VERSION "HNNBNNNYNNNNNNNNNNNNNNNNNNNNNNNNNNNNNNNNNN/4/%%%/4/'%**4NNN///"

NS_ :

BS_:

BU_: BAP_Tester BedienDisp_mi BedienDisp_vo_mi CDI ConMod_CD DashCAM Gateway_Max ICC_IO_Node LSH OCU RDK_RS3 Sound_MIB_ab_Gen3 STH ZR_MIB_EINSTIEG_ab_Gen3 ZR_MIB_OPTION_ab_Gen3 ZR_MIB_TOP_ab_Gen3

BO_ 975 TSG_HBFS_01: 8 Gateway_Max
 SG_ HBFS_Tuer_geoeffnet : 0|1@1+ (1.0,0.0) [0.0|1] ""  OCU,ZR_MIB_TOP_ab_Gen3
 SG_ HBFS_verriegelt : 1|1@1+ (1.0,0.0) [0.0|1] ""  OCU
 SG_ HBFS_gesafet : 2|1@1+ (1.0,0.0) [0.0|1] ""  OCU
 SG_ HBFS_Heckrollotaster_betaetigt : 3|1@1+ (1.0,0.0) [0.0|1] ""  Vector__XXX
 SG_ HBFS_Tuerschloss_defekt : 4|1@1+ (1.0,0.0) [0.0|1] ""  Vector__XXX
 SG_ HBFS_Unlock_Taster : 5|1@1+ (1.0,0.0) [0.0|1] ""  Vector__XXX
 SG_ HBFS_Lock_Taster : 6|1@1+ (1.0,0.0) [0.0|1] ""  Vector__XXX
 SG_ HBFS_Sperrklinke : 7|1@1+ (1.0,0.0) [0.0|1] ""  Vector__XXX
 SG_ HBFS_TAG_betaetigt : 8|1@1+ (1.0,0.0) [0.0|1] ""  Vector__XXX
 SG_ HBFS_TIG_betaetigt : 9|1@1+ (1.0,0.0) [0.0|1] ""  Vector__XXX
 SG_ HBFS_FH_S_HFS_AutoHoch : 10|1@1+ (1.0,0.0) [0.0|1] ""  Vector__XXX
 SG_ HBFS_FH_S_HFS_AutoTief : 11|1@1+ (1.0,0.0) [0.0|1] ""  Vector__XXX
 SG_ HBFS_FH_S_HFS_ManHoch : 12|1@1+ (1.0,0.0) [0.0|1] ""  Vector__XXX
 SG_ HBFS_FH_S_HFS_ManTief : 13|1@1+ (1.0,0.0) [0.0|1] ""  Vector__XXX
 SG_ HBFS_Tuer_Status : 14|2@1+ (1.0,0.0) [0.0|3] ""  OCU
 SG_ HBFS_SAD_Schalter : 16|4@1+ (1.0,0.0) [0.0|15] ""  Vector__XXX
 SG_ HBFS_FH_S_ManHoch : 20|1@1+ (1.0,0.0) [0.0|1] ""  Vector__XXX
 SG_ HBFS_FH_S_AutoHoch : 21|1@1+ (1.0,0.0) [0.0|1] ""  Vector__XXX
 SG_ HBFS_FH_S_ManTief : 22|1@1+ (1.0,0.0) [0.0|1] ""  Vector__XXX
 SG_ HBFS_FH_S_AutoTief : 23|1@1+ (1.0,0.0) [0.0|1] ""  Vector__XXX
 SG_ HBFS_FH_Oeffnung : 24|8@1+ (0.5,0) [0.0|100.0] "Unit_PerCent"  OCU,ZR_MIB_TOP_ab_Gen3
 SG_ HBFS_FH_Bew_hoch : 32|1@1+ (1.0,0.0) [0.0|1] ""  Vector__XXX
 SG_ HBFS_FH_Bew_tief : 33|1@1+ (1.0,0.0) [0.0|1] ""  Vector__XXX
 SG_ HBFS_FH_Fang : 34|1@1+ (1.0,0.0) [0.0|1] ""  OCU
 SG_ HBFS_FH_Block : 35|1@1+ (1.0,0.0) [0.0|1] ""  Vector__XXX
 SG_ HBFS_FH_Thermo : 36|1@1+ (1.0,0.0) [0.0|1] ""  Vector__XXX
 SG_ HBFS_UEKB_aktiviert : 37|1@1+ (1.0,0.0) [0.0|1] ""  Vector__XXX
 SG_ HBFS_Tueroeffnen_Warnung : 38|1@1+ (1.0,0.0) [0.0|1] ""  Vector__XXX
 SG_ HBFS_FH_normiert : 39|1@1+ (1.0,0.0) [0.0|1] ""  OCU
 SG_ ASW_Warnung_aktiv_HBFS : 40|1@1+ (1.0,0.0) [0.0|1] ""  Vector__XXX
 SG_ HBFS_Zuziehhilfe_aktiv : 41|1@1+ (1.0,0.0) [0.0|1] ""  Vector__XXX
 SG_ HBFS_Seitenrollo_hoch : 42|1@1+ (1.0,0.0) [0.0|1] ""  Vector__XXX
 SG_ HBFS_Seitenrollo_tief : 43|1@1+ (1.0,0.0) [0.0|1] ""  Vector__XXX
 SG_ HBFS_Status_KiSi : 44|1@1+ (1.0,0.0) [0.0|1] ""  Vector__XXX
 SG_ SSR_HBFS_Pos_Unten : 45|1@1+ (1.0,0.0) [0.0|1] ""  Vector__XXX
 SG_ HBFS_Oben_Block_erw : 46|1@1+ (1.0,0.0) [0.0|1] ""  Vector__XXX
 SG_ HBFS_Unten_Block_erw : 47|1@1+ (1.0,0.0) [0.0|1] ""  Vector__XXX
 SG_ MTHBFS_M_Taste : 48|1@1+ (1.0,0.0) [0.0|1] ""  Vector__XXX
 SG_ MTHBFS_Pos1 : 49|1@1+ (1.0,0.0) [0.0|1] ""  Vector__XXX
 SG_ MTHBFS_Pos2 : 50|1@1+ (1.0,0.0) [0.0|1] ""  Vector__XXX
 SG_ MTHBFS_Pos3 : 51|1@1+ (1.0,0.0) [0.0|1] ""  Vector__XXX
 SG_ HBFS_MRollo_Schalter : 52|3@1+ (1.0,0.0) [0.0|7] ""  Vector__XXX
 SG_ HBFS_Lock_Taster_inv : 55|1@1+ (1.0,0.0) [0.0|1] ""  Vector__XXX
 SG_ HBFS_Status_KiSi_inv : 56|1@1+ (1.0,0.0) [0.0|1] ""  Vector__XXX
 SG_ HBFS_Status_eTAG : 57|2@1+ (1.0,0.0) [0.0|3] ""  Vector__XXX
 SG_ HBFS_Tuer_Status_QBit : 59|1@1+ (1.0,0.0) [0.0|1] ""  Vector__XXX
 SG_ HBFS_TIG_betaetigt_schliessen : 60|1@1+ (1.0,0.0) [0.0|1] ""  Vector__XXX
 SG_ HBFS_TIG_betaetigt_oeffnen : 61|1@1+ (1.0,0.0) [0.0|1] ""  Vector__XXX
 SG_ HBFS_Vorraste_betaetigt : 62|1@1+ (1.0,0.0) [0.0|1] ""  Vector__XXX
 SG_ HBFS_SK_betaetigt : 63|1@1+ (1.0,0.0) [0.0|1] ""  Vector__XXX

BO_ 974 TSG_HFS_01: 8 Gateway_Max
 SG_ HFS_Tuer_geoeffnet : 0|1@1+ (1.0,0.0) [0.0|1] ""  OCU,ZR_MIB_TOP_ab_Gen3
 SG_ HFS_verriegelt : 1|1@1+ (1.0,0.0) [0.0|1] ""  OCU
 SG_ HFS_gesafet : 2|1@1+ (1.0,0.0) [0.0|1] ""  OCU
 SG_ HFS_Heckrollotaster_betaetigt : 3|1@1+ (1.0,0.0) [0.0|1] ""  Vector__XXX
 SG_ HFS_Tuerschloss_defekt : 4|1@1+ (1.0,0.0) [0.0|1] ""  Vector__XXX
 SG_ HFS_Unlock_Taster : 5|1@1+ (1.0,0.0) [0.0|1] ""  Vector__XXX
 SG_ HFS_Lock_Taster : 6|1@1+ (1.0,0.0) [0.0|1] ""  Vector__XXX
 SG_ HFS_Sperrklinke : 7|1@1+ (1.0,0.0) [0.0|1] ""  Vector__XXX
 SG_ HFS_TAG_betaetigt : 8|1@1+ (1.0,0.0) [0.0|1] ""  Vector__XXX
 SG_ HFS_TIG_betaetigt : 9|1@1+ (1.0,0.0) [0.0|1] ""  Vector__XXX
 SG_ HFS_FH_S_HBFS_AutoHoch : 10|1@1+ (1.0,0.0) [0.0|1] ""  Vector__XXX
 SG_ HFS_FH_S_HBFS_AutoTief : 11|1@1+ (1.0,0.0) [0.0|1] ""  Vector__XXX
 SG_ HFS_FH_S_HBFS_ManHoch : 12|1@1+ (1.0,0.0) [0.0|1] ""  Vector__XXX
 SG_ HFS_FH_S_HBFS_ManTief : 13|1@1+ (1.0,0.0) [0.0|1] ""  Vector__XXX
 SG_ HFS_Tuer_Status : 14|2@1+ (1.0,0.0) [0.0|3] ""  OCU
 SG_ HFS_SAD_Schalter : 16|4@1+ (1.0,0.0) [0.0|15] ""  Vector__XXX
 SG_ HFS_FH_S_ManHoch : 20|1@1+ (1.0,0.0) [0.0|1] ""  Vector__XXX
 SG_ HFS_FH_S_AutoHoch : 21|1@1+ (1.0,0.0) [0.0|1] ""  Vector__XXX
 SG_ HFS_FH_S_ManTief : 22|1@1+ (1.0,0.0) [0.0|1] ""  Vector__XXX
 SG_ HFS_FH_S_AutoTief : 23|1@1+ (1.0,0.0) [0.0|1] ""  Vector__XXX
 SG_ HFS_FH_Oeffnung : 24|8@1+ (0.5,0) [0.0|100.0] "Unit_PerCent"  OCU,ZR_MIB_TOP_ab_Gen3
 SG_ HFS_FH_Bew_hoch : 32|1@1+ (1.0,0.0) [0.0|1] ""  Vector__XXX
 SG_ HFS_FH_Bew_tief : 33|1@1+ (1.0,0.0) [0.0|1] ""  Vector__XXX
 SG_ HFS_FH_Fang : 34|1@1+ (1.0,0.0) [0.0|1] ""  OCU
 SG_ HFS_FH_Block : 35|1@1+ (1.0,0.0) [0.0|1] ""  Vector__XXX
 SG_ HFS_FH_Thermo : 36|1@1+ (1.0,0.0) [0.0|1] ""  Vector__XXX
 SG_ HFS_UEKB_aktiviert : 37|1@1+ (1.0,0.0) [0.0|1] ""  Vector__XXX
 SG_ HFS_Tueroeffnen_Warnung : 38|1@1+ (1.0,0.0) [0.0|1] ""  Vector__XXX
 SG_ HFS_FH_normiert : 39|1@1+ (1.0,0.0) [0.0|1] ""  OCU
 SG_ ASW_Warnung_aktiv_HFS : 40|1@1+ (1.0,0.0) [0.0|1] ""  Vector__XXX
 SG_ HFS_Zuziehhilfe_aktiv : 41|1@1+ (1.0,0.0) [0.0|1] ""  Vector__XXX
 SG_ HFS_Seitenrollo_hoch : 42|1@1+ (1.0,0.0) [0.0|1] ""  Vector__XXX
 SG_ HFS_Seitenrollo_tief : 43|1@1+ (1.0,0.0) [0.0|1] ""  Vector__XXX
 SG_ HFS_Status_KiSi : 44|1@1+ (1.0,0.0) [0.0|1] ""  Vector__XXX
 SG_ SSR_HFS_Pos_Unten : 45|1@1+ (1.0,0.0) [0.0|1] ""  Vector__XXX
 SG_ HFS_Oben_Block_erw : 46|1@1+ (1.0,0.0) [0.0|1] ""  Vector__XXX
 SG_ HFS_Unten_Block_erw : 47|1@1+ (1.0,0.0) [0.0|1] ""  Vector__XXX
 SG_ MTHFS_M_Taste : 48|1@1+ (1.0,0.0) [0.0|1] ""  Vector__XXX
 SG_ MTHFS_Pos1 : 49|1@1+ (1.0,0.0) [0.0|1] ""  Vector__XXX
 SG_ MTHFS_Pos2 : 50|1@1+ (1.0,0.0) [0.0|1] ""  Vector__XXX
 SG_ MTHFS_Pos3 : 51|1@1+ (1.0,0.0) [0.0|1] ""  Vector__XXX
 SG_ HFS_MRollo_Schalter : 52|3@1+ (1.0,0.0) [0.0|7] ""  Vector__XXX
 SG_ HFS_Lock_Taster_inv : 55|1@1+ (1.0,0.0) [0.0|1] ""  Vector__XXX
 SG_ HFS_Status_eTAG : 56|2@1+ (1.0,0.0) [0.0|3] ""  Vector__XXX
 SG_ HFS_Tuer_Status_QBit : 58|1@1+ (1.0,0.0) [0.0|1] ""  Vector__XXX
 SG_ HFS_TCR_Mode_aktiv : 59|1@1+ (1.0,0.0) [0.0|1] ""  Vector__XXX
 SG_ HFS_TIG_betaetigt_schliessen : 60|1@1+ (1.0,0.0) [0.0|1] ""  Vector__XXX
 SG_ HFS_TIG_betaetigt_oeffnen : 61|1@1+ (1.0,0.0) [0.0|1] ""  Vector__XXX
 SG_ HFS_Vorraste_betaetigt : 62|1@1+ (1.0,0.0) [0.0|1] ""  Vector__XXX
 SG_ HFS_SK_betaetigt : 63|1@1+ (1.0,0.0) [0.0|1] ""  Vector__XXX

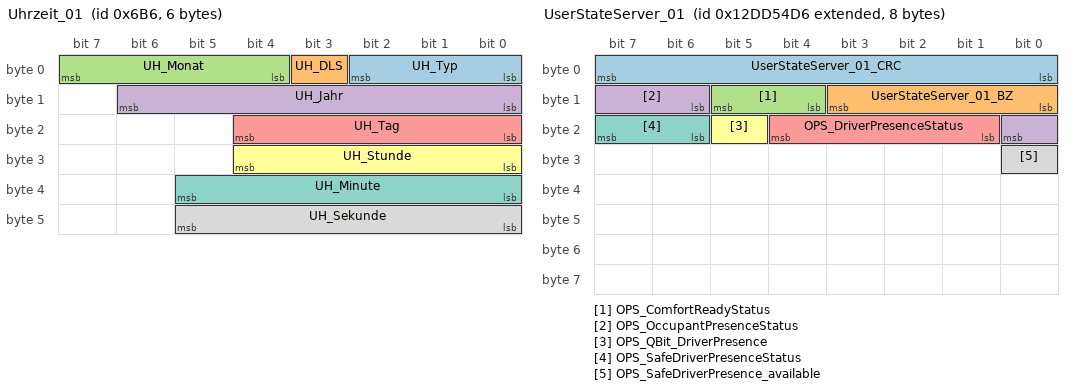
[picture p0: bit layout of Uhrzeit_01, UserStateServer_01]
BO_ 1718 Uhrzeit_01: 6 Gateway_Max
 SG_ UH_Typ : 0|3@1+ (1.0,0.0) [0.0|7] ""  OCU
 SG_ UH_DLS : 3|1@1+ (1.0,0.0) [0.0|1] ""  OCU
 SG_ UH_Monat : 4|4@1+ (1,0) [1|12] "Unit_Month"  CDI,OCU
 SG_ UH_Jahr : 8|7@1+ (1,2000) [2000|2127] "Unit_Year"  CDI,OCU
 SG_ UH_Tag : 16|5@1+ (1,0) [1|31] "Unit_Day"  CDI,OCU
 SG_ UH_Stunde : 24|5@1+ (1,0) [0|23] "Unit_Hours"  CDI,OCU
 SG_ UH_Minute : 32|6@1+ (1,0) [0|59] "Unit_Minut"  CDI,OCU
 SG_ UH_Sekunde : 40|6@1+ (1,0) [0|59] "Unit_Secon"  CDI,OCU

BO_ 2463978710 UserStateServer_01: 8 Gateway_Max
 SG_ UserStateServer_01_CRC : 0|8@1+ (1,0) [0|255] ""  Vector__XXX
 SG_ UserStateServer_01_BZ : 8|4@1+ (1,0) [0|15] ""  Vector__XXX
 SG_ OPS_ComfortReadyStatus : 12|2@1+ (1.0,0.0) [0.0|3] ""  BedienDisp_mi,BedienDisp_vo_mi,ConMod_CD
 SG_ OPS_OccupantPresenceStatus : 14|3@1+ (1.0,0.0) [0.0|7] ""  Vector__XXX
 SG_ OPS_DriverPresenceStatus : 17|4@1+ (1.0,0.0) [0.0|15] ""  BedienDisp_mi,BedienDisp_vo_mi
 SG_ OPS_QBit_DriverPresence : 21|1@1+ (1.0,0.0) [0.0|1] ""  Vector__XXX
 SG_ OPS_SafeDriverPresenceStatus : 22|2@1+ (1.0,0.0) [0.0|3] ""  Vector__XXX
 SG_ OPS_SafeDriverPresence_available : 24|1@1+ (1.0,0.0) [0.0|1] ""  Vector__XXX

BO_ 995 Verdeck_01: 8 Gateway_Max
 SG_ VS_VD_zu_ver : 16|1@1+ (1.0,0.0) [0.0|1] ""  OCU,ZR_MIB_TOP_ab_Gen3
 SG_ VS_VD_entriegelt : 17|1@1+ (1.0,0.0) [0.0|1] ""  OCU
 SG_ VS_VD_offen_ver : 18|1@1+ (1.0,0.0) [0.0|1] ""  OCU,ZR_MIB_TOP_ab_Gen3
 SG_ VS_VD_Zwischenposition : 19|1@1+ (1.0,0.0) [0.0|1] ""  Vector__XXX
 SG_ VS_VD_Bew_auf : 20|1@1+ (1.0,0.0) [0.0|1] ""  Vector__XXX
 SG_ VS_VD_Bew_zu : 21|1@1+ (1.0,0.0) [0.0|1] ""  Vector__XXX
 SG_ VS_Verdeck_Anf : 22|1@1+ (1.0,0.0) [0.0|1] ""  OCU
 SG_ VS_Hardtop : 23|1@1+ (1.0,0.0) [0.0|1] ""  Vector__XXX
 SG_ VS_VD_Fehler : 24|1@1+ (1.0,0.0) [0.0|1] ""  Vector__XXX
 SG_ VS_Lampe_Blk : 25|1@1+ (1.0,0.0) [0.0|1] ""  Vector__XXX
 SG_ VS_Buzzer : 26|1@1+ (1.0,0.0) [0.0|1] ""  Vector__XXX
 SG_ VS_HD_sperren : 27|1@1+ (1.0,0.0) [0.0|1] ""  Vector__XXX
 SG_ VS_HHS_enable : 28|1@1+ (1.0,0.0) [0.0|1] ""  Vector__XXX
 SG_ VD_SpannungsAnf : 29|2@1+ (1.0,0.0) [0.0|3] ""  Vector__XXX
 SG_ VS_VDKD_auf : 31|1@1+ (1.0,0.0) [0.0|1] ""  Vector__XXX
 SG_ VS_FS_AutoHoch : 32|1@1+ (1.0,0.0) [0.0|1] ""  Vector__XXX
 SG_ VS_FS_AutoTief : 33|1@1+ (1.0,0.0) [0.0|1] ""  Vector__XXX
 SG_ VS_FS_ManHoch : 34|1@1+ (1.0,0.0) [0.0|1] ""  Vector__XXX
 SG_ VS_FS_ManTief : 35|1@1+ (1.0,0.0) [0.0|1] ""  Vector__XXX
 SG_ VS_BFS_AutoHoch : 36|1@1+ (1.0,0.0) [0.0|1] ""  Vector__XXX
 SG_ VS_BFS_AutoTief : 37|1@1+ (1.0,0.0) [0.0|1] ""  Vector__XXX
 SG_ VS_BFS_ManHoch : 38|1@1+ (1.0,0.0) [0.0|1] ""  Vector__XXX
 SG_ VS_BFS_ManTief : 39|1@1+ (1.0,0.0) [0.0|1] ""  Vector__XXX
 SG_ VS_HFS_AutoHoch : 40|1@1+ (1.0,0.0) [0.0|1] ""  Vector__XXX
 SG_ VS_HFS_AutoTief : 41|1@1+ (1.0,0.0) [0.0|1] ""  Vector__XXX
 SG_ VS_HFS_ManHoch : 42|1@1+ (1.0,0.0) [0.0|1] ""  Vector__XXX
 SG_ VS_HFS_ManTief : 43|1@1+ (1.0,0.0) [0.0|1] ""  Vector__XXX
 SG_ VS_HBFS_AutoHoch : 44|1@1+ (1.0,0.0) [0.0|1] ""  Vector__XXX
 SG_ VS_HBFS_AutoTief : 45|1@1+ (1.0,0.0) [0.0|1] ""  Vector__XXX
 SG_ VS_HBFS_ManHoch : 46|1@1+ (1.0,0.0) [0.0|1] ""  Vector__XXX
 SG_ VS_HBFS_ManTief : 47|1@1+ (1.0,0.0) [0.0|1] ""  Vector__XXX
 SG_ VS_FH_FT_Langhub : 49|1@1+ (1.0,0.0) [0.0|1] ""  Vector__XXX
 SG_ VS_Windschott_nicht_abgelegt : 50|1@1+ (1.0,0.0) [0.0|1] ""  Vector__XXX
 SG_ VS_FH_BT_Langhub : 51|1@1+ (1.0,0.0) [0.0|1] ""  Vector__XXX
 SG_ VS_FH_HFS_Langhub : 53|1@1+ (1.0,0.0) [0.0|1] ""  Vector__XXX
 SG_ VS_Heckschloss_auf : 54|1@1+ (1.0,0.0) [0.0|1] ""  Vector__XXX
 SG_ VS_FH_HBFS_Langhub : 55|1@1+ (1.0,0.0) [0.0|1] ""  Vector__XXX
 SG_ VSG_Meldungen : 56|6@1+ (1,0) [1|63] "Unit_None"  Vector__XXX
 SG_ VS_StartStopp_Info : 62|2@1+ (1.0,0.0) [0.0|3] ""  Vector__XXX

BO_ 1716 VIN_01: 8 Gateway_Max
 SG_ VIN_01_MUX M  : 0|2@1+ (1,0) [0|3] ""  CDI,ConMod_CD,DashCAM,OCU,ZR_MIB_EINSTIEG_ab_Gen3,ZR_MIB_OPTION_ab_Gen3,ZR_MIB_TOP_ab_Gen3
 SG_ KS_Geheimnis_1 m0  : 8|8@1+ (1,0) [0|255] ""  CDI,ZR_MIB_EINSTIEG_ab_Gen3,ZR_MIB_OPTION_ab_Gen3,ZR_MIB_TOP_ab_Gen3
 SG_ VIN_4 m1  : 8|8@1+ (1,0) [0|255] ""  CDI,ConMod_CD,DashCAM,OCU,ZR_MIB_EINSTIEG_ab_Gen3,ZR_MIB_OPTION_ab_Gen3,ZR_MIB_TOP_ab_Gen3
 SG_ VIN_11 m2  : 8|8@1+ (1,0) [0|255] ""  CDI,ConMod_CD,DashCAM,OCU,ZR_MIB_EINSTIEG_ab_Gen3,ZR_MIB_OPTION_ab_Gen3,ZR_MIB_TOP_ab_Gen3
 SG_ KS_Geheimnis_2 m0  : 16|8@1+ (1,0) [0|255] ""  CDI,ZR_MIB_EINSTIEG_ab_Gen3,ZR_MIB_OPTION_ab_Gen3,ZR_MIB_TOP_ab_Gen3
 SG_ VIN_5 m1  : 16|8@1+ (1,0) [0|255] ""  CDI,ConMod_CD,DashCAM,OCU,ZR_MIB_EINSTIEG_ab_Gen3,ZR_MIB_OPTION_ab_Gen3,ZR_MIB_TOP_ab_Gen3
 SG_ VIN_12 m2  : 16|8@1+ (1,0) [0|255] ""  CDI,ConMod_CD,DashCAM,OCU,ZR_MIB_EINSTIEG_ab_Gen3,ZR_MIB_OPTION_ab_Gen3,ZR_MIB_TOP_ab_Gen3
 SG_ KS_Geheimnis_3 m0  : 24|8@1+ (1,0) [0|255] ""  CDI,ZR_MIB_EINSTIEG_ab_Gen3,ZR_MIB_OPTION_ab_Gen3,ZR_MIB_TOP_ab_Gen3
 SG_ VIN_6 m1  : 24|8@1+ (1,0) [0|255] ""  CDI,ConMod_CD,DashCAM,OCU,ZR_MIB_EINSTIEG_ab_Gen3,ZR_MIB_OPTION_ab_Gen3,ZR_MIB_TOP_ab_Gen3
 SG_ VIN_13 m2  : 24|8@1+ (1,0) [0|255] ""  CDI,ConMod_CD,DashCAM,OCU,ZR_MIB_EINSTIEG_ab_Gen3,ZR_MIB_OPTION_ab_Gen3,ZR_MIB_TOP_ab_Gen3
 SG_ KS_Geheimnis_4 m0  : 32|8@1+ (1,0) [0|255] ""  CDI,ZR_MIB_EINSTIEG_ab_Gen3,ZR_MIB_OPTION_ab_Gen3,ZR_MIB_TOP_ab_Gen3
 SG_ VIN_7 m1  : 32|8@1+ (1,0) [0|255] ""  CDI,ConMod_CD,DashCAM,OCU,ZR_MIB_EINSTIEG_ab_Gen3,ZR_MIB_OPTION_ab_Gen3,ZR_MIB_TOP_ab_Gen3
 SG_ VIN_14 m2  : 32|8@1+ (1,0) [0|255] ""  CDI,ConMod_CD,DashCAM,OCU,ZR_MIB_EINSTIEG_ab_Gen3,ZR_MIB_OPTION_ab_Gen3,ZR_MIB_TOP_ab_Gen3
 SG_ VIN_1 m0  : 40|8@1+ (1,0) [0|255] ""  CDI,ConMod_CD,DashCAM,OCU,ZR_MIB_EINSTIEG_ab_Gen3,ZR_MIB_OPTION_ab_Gen3,ZR_MIB_TOP_ab_Gen3
 SG_ VIN_8 m1  : 40|8@1+ (1,0) [0|255] ""  CDI,ConMod_CD,DashCAM,OCU,ZR_MIB_EINSTIEG_ab_Gen3,ZR_MIB_OPTION_ab_Gen3,ZR_MIB_TOP_ab_Gen3
 SG_ VIN_15 m2  : 40|8@1+ (1,0) [0|255] ""  CDI,ConMod_CD,DashCAM,OCU,ZR_MIB_EINSTIEG_ab_Gen3,ZR_MIB_OPTION_ab_Gen3,ZR_MIB_TOP_ab_Gen3
 SG_ VIN_2 m0  : 48|8@1+ (1,0) [0|255] ""  CDI,ConMod_CD,DashCAM,OCU,ZR_MIB_EINSTIEG_ab_Gen3,ZR_MIB_OPTION_ab_Gen3,ZR_MIB_TOP_ab_Gen3
 SG_ VIN_9 m1  : 48|8@1+ (1,0) [0|255] ""  CDI,ConMod_CD,DashCAM,OCU,ZR_MIB_EINSTIEG_ab_Gen3,ZR_MIB_OPTION_ab_Gen3,ZR_MIB_TOP_ab_Gen3
 SG_ VIN_16 m2  : 48|8@1+ (1,0) [0|255] ""  CDI,ConMod_CD,DashCAM,OCU,ZR_MIB_EINSTIEG_ab_Gen3,ZR_MIB_OPTION_ab_Gen3,ZR_MIB_TOP_ab_Gen3
 SG_ VIN_3 m0  : 56|8@1+ (1,0) [0|255] ""  CDI,ConMod_CD,DashCAM,OCU,ZR_MIB_EINSTIEG_ab_Gen3,ZR_MIB_OPTION_ab_Gen3,ZR_MIB_TOP_ab_Gen3
 SG_ VIN_10 m1  : 56|8@1+ (1,0) [0|255] ""  CDI,ConMod_CD,DashCAM,OCU,ZR_MIB_EINSTIEG_ab_Gen3,ZR_MIB_OPTION_ab_Gen3,ZR_MIB_TOP_ab_Gen3
 SG_ VIN_17 m2  : 56|8@1+ (1,0) [0|255] ""  CDI,ConMod_CD,DashCAM,OCU,ZR_MIB_EINSTIEG_ab_Gen3,ZR_MIB_OPTION_ab_Gen3,ZR_MIB_TOP_ab_Gen3

BO_ 916 WBA_03: 8 Gateway_Max
 SG_ WBA_03_CRC : 0|8@1+ (1,0) [0|255] ""  Vector__XXX
 SG_ WBA_03_BZ : 8|4@1+ (1,0) [0|15] ""  Vector__XXX
 SG_ WBA_Fahrstufe_02 : 12|4@1+ (1.0,0.0) [0.0|15] ""  OCU,ZR_MIB_EINSTIEG_ab_Gen3,ZR_MIB_OPTION_ab_Gen3,ZR_MIB_TOP_ab_Gen3
 SG_ WBA_ZielFahrstufe : 16|4@1+ (1.0,0.0) [0.0|15] ""  Vector__XXX
 SG_ WBA_GE_Warnung_02 : 20|4@1+ (1.0,0.0) [0.0|15] ""  Vector__XXX
 SG_ WBA_eing_Gang_02 : 24|4@1+ (1.0,0.0) [0.0|15] ""  OCU,ZR_MIB_EINSTIEG_ab_Gen3,ZR_MIB_OPTION_ab_Gen3,ZR_MIB_TOP_ab_Gen3
 SG_ WBA_GE_Texte : 28|3@1+ (1.0,0.0) [0.0|7] ""  Vector__XXX
 SG_ WBA_Segeln_aktiv : 31|1@1+ (1.0,0.0) [0.0|1] ""  OCU,ZR_MIB_EINSTIEG_ab_Gen3,ZR_MIB_OPTION_ab_Gen3,ZR_MIB_TOP_ab_Gen3
 SG_ WBA_Schaltschema_02 : 32|3@1+ (1.0,0.0) [0.0|7] ""  Vector__XXX
 SG_ WBA_Schaltschema_FS_inaktiv : 35|2@1+ (1.0,0.0) [0.0|3] ""  Vector__XXX
 SG_ WBA_GE_Zusatzwarnungen : 37|3@1+ (1.0,0.0) [0.0|7] ""  OCU,ZR_MIB_TOP_ab_Gen3
 SG_ GE_Sollgang : 40|4@1+ (1.0,0.0) [0.0|15] ""  OCU,ZR_MIB_EINSTIEG_ab_Gen3,ZR_MIB_OPTION_ab_Gen3,ZR_MIB_TOP_ab_Gen3
 SG_ GE_Tipschaltempf_verfuegbar : 44|1@1+ (1.0,0.0) [0.0|1] ""  OCU,ZR_MIB_OPTION_ab_Gen3
 SG_ WBA_GE_Texte_02 : 45|3@1+ (1.0,0.0) [0.0|7] ""  Vector__XXX
 SG_ WBA_Schaltschema_Tippgasse : 48|1@1+ (1.0,0.0) [0.0|1] ""  Vector__XXX
 SG_ WBA_Schaltschema_Fahreraktion : 49|1@1+ (1.0,0.0) [0.0|1] ""  Vector__XXX
 SG_ WBA_Schaltschema_FS_vorwaerts : 50|2@1+ (1.0,0.0) [0.0|3] ""  Vector__XXX
 SG_ WBA_Shiftlock_Lampe : 52|1@1+ (1.0,0.0) [0.0|1] ""  Vector__XXX
 SG_ WBA_Anforderung_Akustik : 53|1@1+ (1.0,0.0) [0.0|1] ""  Vector__XXX
 SG_ WBA_Blinken : 54|1@1+ (1.0,0.0) [0.0|1] ""  Vector__XXX
 SG_ GE_Wiederstart_Anz_Std : 55|1@1+ (1.0,0.0) [0.0|1] ""  Vector__XXX
 SG_ GE_Stoppverbot_Anz_01 : 56|1@1+ (1.0,0.0) [0.0|1] ""  Vector__XXX
 SG_ GE_Stoppverbot_Anz_02 : 57|1@1+ (1.0,0.0) [0.0|1] ""  Vector__XXX
 SG_ GE_Stoppverbot_Anz_03 : 58|1@1+ (1.0,0.0) [0.0|1] ""  Vector__XXX
 SG_ GE_Stoppverbot_Anz_04 : 59|1@1+ (1.0,0.0) [0.0|1] ""  Vector__XXX
 SG_ GE_Stoppverbot_Anz_05 : 60|1@1+ (1.0,0.0) [0.0|1] ""  Vector__XXX
 SG_ GE_Stoppverbot_Anz_06 : 61|1@1+ (1.0,0.0) [0.0|1] ""  Vector__XXX
 SG_ GE_Stoppverbot_Anz_07 : 62|1@1+ (1.0,0.0) [0.0|1] ""  Vector__XXX
 SG_ GE_Stoppverbot_Anz_Std : 63|1@1+ (1.0,0.0) [0.0|1] ""  Vector__XXX

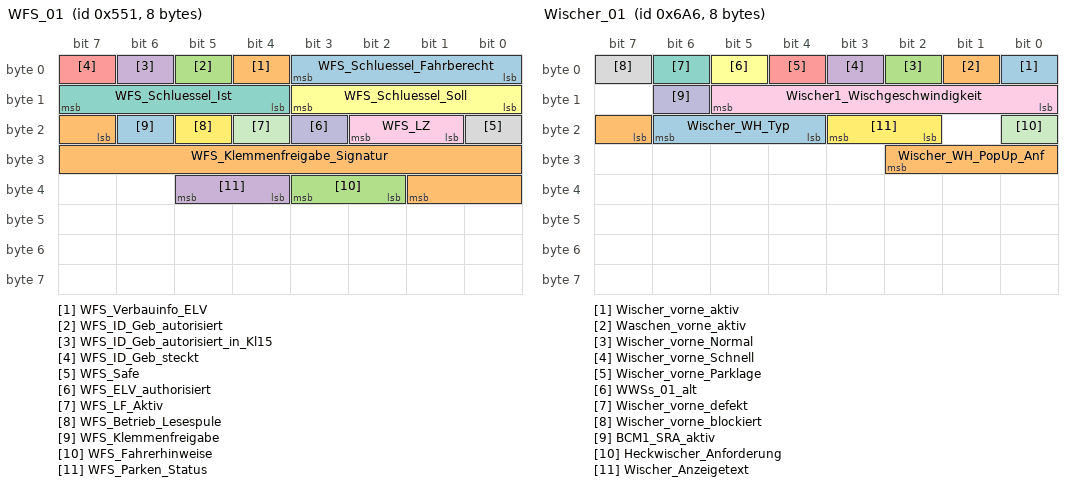
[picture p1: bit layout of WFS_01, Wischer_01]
BO_ 1361 WFS_01: 8 Gateway_Max
 SG_ WFS_Schluessel_Fahrberecht : 0|4@1+ (1.0,0.0) [0.0|15] ""  OCU,ZR_MIB_EINSTIEG_ab_Gen3
 SG_ WFS_Verbauinfo_ELV : 4|1@1+ (1.0,0.0) [0.0|1] ""  Vector__XXX
 SG_ WFS_ID_Geb_autorisiert : 5|1@1+ (1.0,0.0) [0.0|1] ""  Vector__XXX
 SG_ WFS_ID_Geb_autorisiert_in_Kl15 : 6|1@1+ (1.0,0.0) [0.0|1] ""  OCU
 SG_ WFS_ID_Geb_steckt : 7|1@1+ (1.0,0.0) [0.0|1] ""  Vector__XXX
 SG_ WFS_Schluessel_Soll : 8|4@1+ (1,0) [0|8] "Unit_None"  ZR_MIB_EINSTIEG_ab_Gen3,ZR_MIB_TOP_ab_Gen3
 SG_ WFS_Schluessel_Ist : 12|4@1+ (1,0) [0|8] "Unit_None"  ZR_MIB_EINSTIEG_ab_Gen3,ZR_MIB_TOP_ab_Gen3
 SG_ WFS_Safe : 16|1@1+ (1.0,0.0) [0.0|1] ""  Vector__XXX
 SG_ WFS_LZ : 17|2@1+ (1.0,0.0) [0.0|3] ""  Vector__XXX
 SG_ WFS_ELV_authorisiert : 19|1@1+ (1.0,0.0) [0.0|1] ""  Vector__XXX
 SG_ WFS_LF_Aktiv : 20|1@1+ (1.0,0.0) [0.0|1] ""  Vector__XXX
 SG_ WFS_Betrieb_Lesespule : 21|1@1+ (1.0,0.0) [0.0|1] ""  Vector__XXX
 SG_ WFS_Klemmenfreigabe : 22|1@1+ (1.0,0.0) [0.0|1] ""  OCU
 SG_ WFS_Klemmenfreigabe_Signatur : 23|11@1+ (1,0) [0|2047] ""  Vector__XXX
 SG_ WFS_Fahrerhinweise : 34|2@1+ (1.0,0.0) [0.0|3] ""  Vector__XXX
 SG_ WFS_Parken_Status : 36|2@1+ (1.0,0.0) [0.0|3] ""  Vector__XXX

BO_ 1702 Wischer_01: 8 Gateway_Max
 SG_ Wischer_vorne_aktiv : 0|1@1+ (1.0,0.0) [0.0|1] ""  OCU
 SG_ Waschen_vorne_aktiv : 1|1@1+ (1.0,0.0) [0.0|1] ""  OCU
 SG_ Wischer_vorne_Normal : 2|1@1+ (1.0,0.0) [0.0|1] ""  Vector__XXX
 SG_ Wischer_vorne_Schnell : 3|1@1+ (1.0,0.0) [0.0|1] ""  Vector__XXX
 SG_ Wischer_vorne_Parklage : 4|1@1+ (1.0,0.0) [0.0|1] ""  Vector__XXX
 SG_ WWSs_01_alt : 5|1@1+ (1.0,0.0) [0.0|1] ""  Vector__XXX
 SG_ Wischer_vorne_defekt : 6|1@1+ (1.0,0.0) [0.0|1] ""  OCU
 SG_ Wischer_vorne_blockiert : 7|1@1+ (1.0,0.0) [0.0|1] ""  Vector__XXX
 SG_ Wischer1_Wischgeschwindigkeit : 8|6@1+ (1,9) [10|70] "Unit_MinutInver"  OCU
 SG_ BCM1_SRA_aktiv : 14|1@1+ (1.0,0.0) [0.0|1] ""  Vector__XXX
 SG_ Heckwischer_Anforderung : 16|1@1+ (1.0,0.0) [0.0|1] ""  Vector__XXX
 SG_ Wischer_Anzeigetext : 18|2@1+ (1.0,0.0) [0.0|3] ""  Vector__XXX
 SG_ Wischer_WH_Typ : 20|3@1+ (1.0,0.0) [0.0|7] ""  Vector__XXX
 SG_ Wischer_WH_PopUp_Anf : 23|4@1+ (1.0,0.0) [0.0|15] ""  Vector__XXX

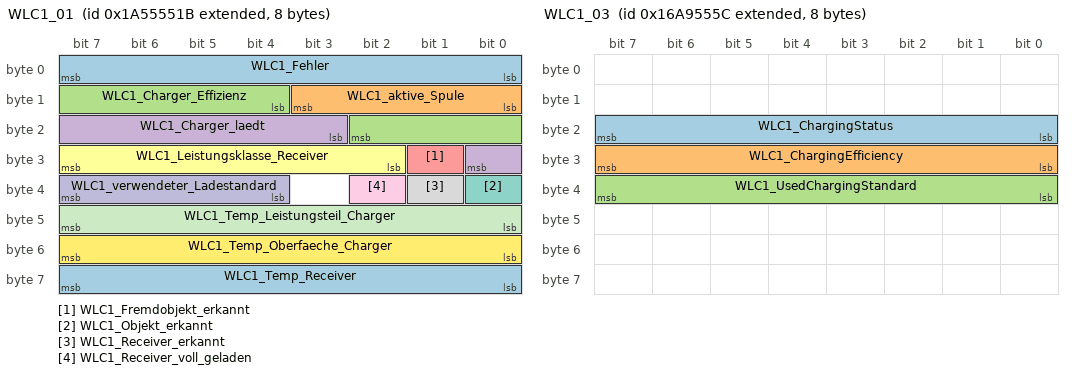
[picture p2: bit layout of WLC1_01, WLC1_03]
BO_ 2589283611 WLC1_01: 8 Gateway_Max
 SG_ WLC1_Fehler : 0|8@1+ (1.0,0.0) [0.0|255] ""  Gateway_Max,ICC_IO_Node,ZR_MIB_EINSTIEG_ab_Gen3,ZR_MIB_OPTION_ab_Gen3,ZR_MIB_TOP_ab_Gen3
 SG_ WLC1_aktive_Spule : 8|4@1+ (1,0) [0|10] ""  Gateway_Max,ICC_IO_Node,ZR_MIB_EINSTIEG_ab_Gen3,ZR_MIB_OPTION_ab_Gen3,ZR_MIB_TOP_ab_Gen3
 SG_ WLC1_Charger_Effizienz : 12|7@1+ (1,0) [0|100] "Unit_PerCent"  Gateway_Max,ICC_IO_Node,ZR_MIB_EINSTIEG_ab_Gen3,ZR_MIB_OPTION_ab_Gen3,ZR_MIB_TOP_ab_Gen3
 SG_ WLC1_Charger_laedt : 19|6@1+ (0.1,0) [0.0|5.0] "Unit_Watt"  Gateway_Max,ICC_IO_Node,ZR_MIB_EINSTIEG_ab_Gen3,ZR_MIB_OPTION_ab_Gen3,ZR_MIB_TOP_ab_Gen3
 SG_ WLC1_Fremdobjekt_erkannt : 25|1@1+ (1.0,0.0) [0.0|1] ""  Gateway_Max,ICC_IO_Node,ZR_MIB_EINSTIEG_ab_Gen3,ZR_MIB_OPTION_ab_Gen3,ZR_MIB_TOP_ab_Gen3
 SG_ WLC1_Leistungsklasse_Receiver : 26|6@1+ (0.1,0) [0.0|5.0] "Unit_Watt"  Gateway_Max,ICC_IO_Node,ZR_MIB_EINSTIEG_ab_Gen3,ZR_MIB_OPTION_ab_Gen3,ZR_MIB_TOP_ab_Gen3
 SG_ WLC1_Objekt_erkannt : 32|1@1+ (1.0,0.0) [0.0|1] ""  Gateway_Max,ICC_IO_Node,ZR_MIB_EINSTIEG_ab_Gen3,ZR_MIB_OPTION_ab_Gen3,ZR_MIB_TOP_ab_Gen3
 SG_ WLC1_Receiver_erkannt : 33|1@1+ (1.0,0.0) [0.0|1] ""  Gateway_Max,ICC_IO_Node,ZR_MIB_EINSTIEG_ab_Gen3,ZR_MIB_OPTION_ab_Gen3,ZR_MIB_TOP_ab_Gen3
 SG_ WLC1_Receiver_voll_geladen : 34|1@1+ (1.0,0.0) [0.0|1] ""  Gateway_Max,ICC_IO_Node,ZR_MIB_EINSTIEG_ab_Gen3,ZR_MIB_OPTION_ab_Gen3,ZR_MIB_TOP_ab_Gen3
 SG_ WLC1_verwendeter_Ladestandard : 36|4@1+ (1,0) [0|15] ""  Gateway_Max,ICC_IO_Node,ZR_MIB_EINSTIEG_ab_Gen3,ZR_MIB_OPTION_ab_Gen3,ZR_MIB_TOP_ab_Gen3
 SG_ WLC1_Temp_Leistungsteil_Charger : 40|8@1+ (1,-58) [-58|120] "Unit_DegreCelsi"  Gateway_Max,ICC_IO_Node,ZR_MIB_EINSTIEG_ab_Gen3,ZR_MIB_OPTION_ab_Gen3,ZR_MIB_TOP_ab_Gen3
 SG_ WLC1_Temp_Oberfaeche_Charger : 48|8@1+ (1,-58) [-58|120] "Unit_DegreCelsi"  Gateway_Max,ICC_IO_Node,ZR_MIB_EINSTIEG_ab_Gen3,ZR_MIB_OPTION_ab_Gen3,ZR_MIB_TOP_ab_Gen3
 SG_ WLC1_Temp_Receiver : 56|8@1+ (1,-58) [-58|120] "Unit_DegreCelsi"  Gateway_Max,ICC_IO_Node,ZR_MIB_EINSTIEG_ab_Gen3,ZR_MIB_OPTION_ab_Gen3,ZR_MIB_TOP_ab_Gen3

BO_ 2527679836 WLC1_03: 8 Gateway_Max
 SG_ WLC1_ChargingStatus : 16|8@1+ (1.0,0.0) [0.0|255] ""  Gateway_Max,ICC_IO_Node,ZR_MIB_EINSTIEG_ab_Gen3,ZR_MIB_OPTION_ab_Gen3,ZR_MIB_TOP_ab_Gen3
 SG_ WLC1_ChargingEfficiency : 24|8@1+ (1,0) [0|100] "Unit_PerCent"  Gateway_Max,ICC_IO_Node,ZR_MIB_EINSTIEG_ab_Gen3,ZR_MIB_OPTION_ab_Gen3,ZR_MIB_TOP_ab_Gen3
 SG_ WLC1_UsedChargingStandard : 32|8@1+ (1.0,0.0) [0.0|255] ""  Gateway_Max,ICC_IO_Node,ZR_MIB_EINSTIEG_ab_Gen3,ZR_MIB_OPTION_ab_Gen3,ZR_MIB_TOP_ab_Gen3

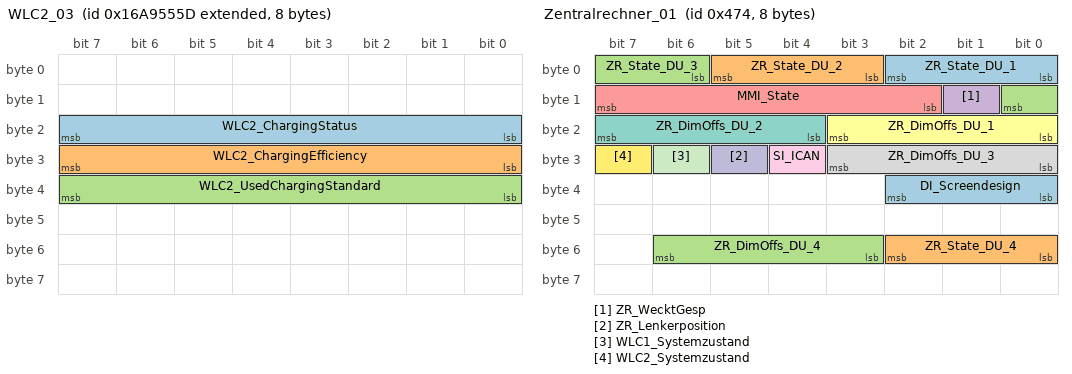
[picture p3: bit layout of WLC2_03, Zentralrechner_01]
BO_ 2527679837 WLC2_03: 8 Gateway_Max
 SG_ WLC2_ChargingStatus : 16|8@1+ (1.0,0.0) [0.0|255] ""  ZR_MIB_EINSTIEG_ab_Gen3,ZR_MIB_OPTION_ab_Gen3
 SG_ WLC2_ChargingEfficiency : 24|8@1+ (1,0) [0|100] "Unit_PerCent"  ZR_MIB_EINSTIEG_ab_Gen3,ZR_MIB_OPTION_ab_Gen3
 SG_ WLC2_UsedChargingStandard : 32|8@1+ (1.0,0.0) [0.0|255] ""  ZR_MIB_EINSTIEG_ab_Gen3,ZR_MIB_OPTION_ab_Gen3

BO_ 2617059072 XCP_LSH_CRO_01: 8 Vector__XXX
 SG_ XCP_LSH_CRO_01_Data : 0|64@1+ (1,0) [0|1] ""  LSH

BO_ 2617059073 XCP_LSH_DTO_01: 8 LSH
 SG_ XCP_LSH_DTO_01_Data : 0|64@1+ (1,0) [0|1] ""  Vector__XXX

BO_ 1140 Zentralrechner_01: 8 ICC_IO_Node
 SG_ ZR_State_DU_1 : 0|3@1+ (1.0,0.0) [0.0|7] ""  Gateway_Max
 SG_ ZR_State_DU_2 : 3|3@1+ (1.0,0.0) [0.0|7] ""  Gateway_Max
 SG_ ZR_State_DU_3 : 6|3@1+ (1.0,0.0) [0.0|7] ""  Gateway_Max
 SG_ ZR_WecktGesp : 9|1@1+ (1.0,0.0) [0.0|1] ""  Gateway_Max
 SG_ MMI_State : 10|6@1+ (1.0,0.0) [0.0|63] ""  BedienDisp_mi,BedienDisp_vo_mi,Gateway_Max
 SG_ ZR_DimOffs_DU_1 : 16|4@1+ (1,-5) [-5|5] "Unit_None"  BedienDisp_vo_mi,Gateway_Max
 SG_ ZR_DimOffs_DU_2 : 20|4@1+ (1,-5) [-5|5] "Unit_None"  Gateway_Max
 SG_ ZR_DimOffs_DU_3 : 24|4@1+ (1,-5) [-5|5] "Unit_None"  Gateway_Max
 SG_ SI_ICAN : 28|1@1+ (1.0,0.0) [0.0|1] ""  Gateway_Max
 SG_ ZR_Lenkerposition : 29|1@1+ (1.0,0.0) [0.0|1] ""  Gateway_Max
 SG_ WLC1_Systemzustand : 30|1@1+ (1.0,0.0) [0.0|1] ""  Gateway_Max
 SG_ WLC2_Systemzustand : 31|1@1+ (1.0,0.0) [0.0|1] ""  Gateway_Max
 SG_ DI_Screendesign : 32|3@1+ (1.0,0.0) [0.0|7] ""  BedienDisp_vo_mi,CDI,Gateway_Max
 SG_ ZR_State_DU_4 : 48|3@1+ (1.0,0.0) [0.0|7] ""  Gateway_Max
 SG_ ZR_DimOffs_DU_4 : 51|4@1+ (1,-5) [-5|5] "Unit_None"  Gateway_Max

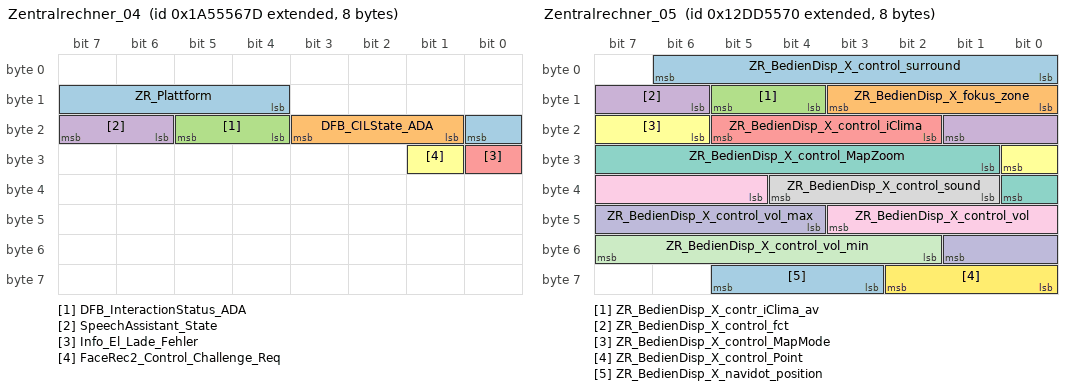
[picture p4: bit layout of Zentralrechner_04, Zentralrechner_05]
BO_ 2589283965 Zentralrechner_04: 8 ZR_MIB_EINSTIEG_ab_Gen3
 SG_ ZR_Plattform : 12|5@1+ (1.0,0.0) [0.0|31] ""  Gateway_Max
 SG_ DFB_CILState_ADA : 17|3@1+ (1.0,0.0) [0.0|7] ""  Gateway_Max
 SG_ DFB_InteractionStatus_ADA : 20|2@1+ (1.0,0.0) [0.0|3] ""  Gateway_Max
 SG_ SpeechAssistant_State : 22|2@1+ (1.0,0.0) [0.0|3] ""  Gateway_Max
 SG_ Info_El_Lade_Fehler : 24|1@1+ (1.0,0.0) [0.0|1] ""  Gateway_Max
 SG_ FaceRec2_Control_Challenge_Req : 25|1@1+ (1.0,0.0) [0.0|1] ""  Gateway_Max

BO_ 2463978864 Zentralrechner_05: 8 Gateway_Max
 SG_ ZR_BedienDisp_X_control_surround : 0|7@1+ (1,0) [0|100] "Unit_None"  Gateway_Max
 SG_ ZR_BedienDisp_X_fokus_zone : 8|4@1+ (1.0,0.0) [0.0|15] ""  Gateway_Max
 SG_ ZR_BedienDisp_X_contr_iClima_av : 12|2@1+ (1.0,0.0) [0.0|3] ""  BedienDisp_vo_mi,Gateway_Max
 SG_ ZR_BedienDisp_X_control_fct : 14|4@1+ (1.0,0.0) [0.0|15] ""  BedienDisp_vo_mi,Gateway_Max
 SG_ ZR_BedienDisp_X_control_iClima : 18|4@1+ (1.0,0.0) [0.0|15] ""  BedienDisp_vo_mi,Gateway_Max
 SG_ ZR_BedienDisp_X_control_MapMode : 22|3@1+ (1.0,0.0) [0.0|7] ""  BedienDisp_vo_mi,Gateway_Max
 SG_ ZR_BedienDisp_X_control_MapZoom : 25|8@1+ (1.0,0.0) [0.0|255] ""  BedienDisp_vo_mi,Gateway_Max
 SG_ ZR_BedienDisp_X_control_sound : 33|4@1+ (1.0,0.0) [0.0|15] ""  BedienDisp_mi,BedienDisp_vo_mi,Gateway_Max
 SG_ ZR_BedienDisp_X_control_vol : 37|7@1+ (1,0) [0|60] "Unit_None"  BedienDisp_mi,BedienDisp_vo_mi,Gateway_Max
 SG_ ZR_BedienDisp_X_control_vol_max : 44|6@1+ (1,0) [0|60] ""  BedienDisp_mi,BedienDisp_vo_mi,Gateway_Max
 SG_ ZR_BedienDisp_X_control_vol_min : 50|6@1+ (1,0) [0|60] ""  BedienDisp_mi,BedienDisp_vo_mi,Gateway_Max
 SG_ ZR_BedienDisp_X_control_Point : 56|3@1+ (1.0,0.0) [0.0|7] ""  BedienDisp_vo_mi,Gateway_Max
 SG_ ZR_BedienDisp_X_navidot_position : 59|3@1+ (1.0,0.0) [0.0|7] ""  BedienDisp_vo_mi,Gateway_Max

BO_ 388 ZV_01: 8 Gateway_Max
 SG_ ZV_01_CRC : 0|8@1+ (1,0) [0|255] ""  Vector__XXX
 SG_ ZV_01_BZ : 8|4@1+ (1,0) [0|15] ""  Vector__XXX
 SG_ ZV_FT_verriegeln : 12|1@1+ (1.0,0.0) [0.0|1] ""  OCU
 SG_ ZV_FT_entriegeln : 13|1@1+ (1.0,0.0) [0.0|1] ""  OCU
 SG_ ZV_BT_verriegeln : 14|1@1+ (1.0,0.0) [0.0|1] ""  OCU
 SG_ ZV_BT_entriegeln : 15|1@1+ (1.0,0.0) [0.0|1] ""  OCU
 SG_ ZV_HFS_verriegeln : 16|1@1+ (1.0,0.0) [0.0|1] ""  OCU
 SG_ ZV_HFS_entriegeln : 17|1@1+ (1.0,0.0) [0.0|1] ""  OCU
 SG_ ZV_HBFS_verriegeln : 18|1@1+ (1.0,0.0) [0.0|1] ""  OCU
 SG_ ZV_HBFS_entriegeln : 19|1@1+ (1.0,0.0) [0.0|1] ""  OCU
 SG_ ZV_zentral_safen : 20|1@1+ (1.0,0.0) [0.0|1] ""  OCU
 SG_ ZV_zentral_entsafen : 21|1@1+ (1.0,0.0) [0.0|1] ""  OCU
 SG_ ZV_Spg_Anklappen : 22|1@1+ (1.0,0.0) [0.0|1] ""  Vector__XXX
 SG_ ZV_Softtouch_betaetigt : 23|1@1+ (1.0,0.0) [0.0|1] ""  Vector__XXX
 SG_ ZV_LED_Steuerung : 24|1@1+ (1.0,0.0) [0.0|1] ""  Vector__XXX
 SG_ ZV_LED_Uebernahme : 25|1@1+ (1.0,0.0) [0.0|1] ""  Vector__XXX
 SG_ ZV_auf_FT : 26|1@1+ (1.0,0.0) [0.0|1] ""  Vector__XXX
 SG_ ZV_zu_FT : 27|1@1+ (1.0,0.0) [0.0|1] ""  Vector__XXX
 SG_ ZV_auf_BT : 28|1@1+ (1.0,0.0) [0.0|1] ""  Vector__XXX
 SG_ ZV_zu_BT : 29|1@1+ (1.0,0.0) [0.0|1] ""  Vector__XXX
 SG_ ZV_auf_Kessy : 30|1@1+ (1.0,0.0) [0.0|1] ""  Vector__XXX
 SG_ ZV_zu_Kessy : 31|1@1+ (1.0,0.0) [0.0|1] ""  Vector__XXX
 SG_ ZV_auf_Funk : 32|1@1+ (1.0,0.0) [0.0|1] ""  Vector__XXX
 SG_ ZV_zu_Funk : 33|1@1+ (1.0,0.0) [0.0|1] ""  Vector__XXX
 SG_ VIP_Sensor_betaetigt : 34|1@1+ (1.0,0.0) [0.0|1] ""  OCU
 SG_ VIP_Freigabe : 35|1@1+ (1.0,0.0) [0.0|1] ""  Vector__XXX
 SG_ ZV_zu_Zeitl_Nachverr : 36|1@1+ (1.0,0.0) [0.0|1] ""  Vector__XXX
 SG_ ZV_HSK_entriegeln : 37|1@1+ (1.0,0.0) [0.0|1] ""  Vector__XXX
 SG_ ZV_HSK_verriegeln : 38|1@1+ (1.0,0.0) [0.0|1] ""  Vector__XXX
 SG_ ZV_Verdeck_zu : 39|1@1+ (1.0,0.0) [0.0|1] ""  Vector__XXX
 SG_ ZV_Verdeck_auf : 40|1@1+ (1.0,0.0) [0.0|1] ""  Vector__XXX
 SG_ FH_FT_hoch : 41|1@1+ (1.0,0.0) [0.0|1] ""  Vector__XXX
 SG_ FH_FT_tief : 42|1@1+ (1.0,0.0) [0.0|1] ""  Vector__XXX
 SG_ FH_BT_hoch : 43|1@1+ (1.0,0.0) [0.0|1] ""  Vector__XXX
 SG_ FH_BT_tief : 44|1@1+ (1.0,0.0) [0.0|1] ""  Vector__XXX
 SG_ FH_HFS_hoch : 45|1@1+ (1.0,0.0) [0.0|1] ""  Vector__XXX
 SG_ FH_HFS_tief : 46|1@1+ (1.0,0.0) [0.0|1] ""  Vector__XXX
 SG_ FH_HBFS_hoch : 47|1@1+ (1.0,0.0) [0.0|1] ""  Vector__XXX
 SG_ FH_HBFS_tief : 48|1@1+ (1.0,0.0) [0.0|1] ""  Vector__XXX
 SG_ BCM_Spg_Synchron : 49|1@1+ (1.0,0.0) [0.0|1] ""  Vector__XXX
 SG_ BCM_BF_Spg_Absenkung : 50|1@1+ (1.0,0.0) [0.0|1] ""  Vector__XXX
 SG_ ZV_Signatur : 51|11@1+ (1,0) [0|2047] ""  OCU
 SG_ ZV_entriegeln_Anf : 62|1@1+ (1.0,0.0) [0.0|1] ""  Vector__XXX
 SG_ ZV_auto_Ansteuerung : 63|1@1+ (1.0,0.0) [0.0|1] ""  Vector__XXX

BO_ 1411 ZV_02: 8 Gateway_Max
 SG_ ZV_verriegeln_Anf : 0|1@1+ (1.0,0.0) [0.0|1] ""  Vector__XXX
 SG_ ZV_STSG_HFS_Anf : 1|1@1+ (1.0,0.0) [0.0|1] ""  Vector__XXX
 SG_ ZV_STSG_HBFS_Anf : 2|1@1+ (1.0,0.0) [0.0|1] ""  Vector__XXX
 SG_ ZV_Anf_Challenge_Auth : 3|1@1+ (1.0,0.0) [0.0|1] ""  Vector__XXX
 SG_ ZV_STSG_Crashzustand : 4|1@1+ (1.0,0.0) [0.0|1] ""  Vector__XXX
 SG_ ZV_STSG_eKiSi_defekt : 5|1@1+ (1.0,0.0) [0.0|1] ""  Vector__XXX
 SG_ ZV_eRWK_Umfeld_Pruefung : 6|1@1+ (1.0,0.0) [0.0|1] ""  Vector__XXX
 SG_ VIP_Sensor_STSG_HFS_betaetigt : 10|1@1+ (1.0,0.0) [0.0|1] ""  Vector__XXX
 SG_ VIP_Sensor_STSG_HBFS_betaetigt : 11|1@1+ (1.0,0.0) [0.0|1] ""  Vector__XXX
 SG_ BCM_FH_Freigabe : 12|1@1+ (1.0,0.0) [0.0|1] ""  Vector__XXX
 SG_ BCM_Komfortfkt_Freigabe : 13|1@1+ (1.0,0.0) [0.0|1] ""  Vector__XXX
 SG_ BCM_HSK_Freigabe : 14|1@1+ (1.0,0.0) [0.0|1] ""  Vector__XXX
 SG_ BCM_Verdeck_Freigabe : 15|1@1+ (1.0,0.0) [0.0|1] ""  Vector__XXX
 SG_ ZV_verriegelt_intern_ist : 16|1@1+ (1.0,0.0) [0.0|1] ""  OCU
 SG_ ZV_verriegelt_extern_ist : 17|1@1+ (1.0,0.0) [0.0|1] ""  OCU
 SG_ ZV_verriegelt_intern_soll : 18|1@1+ (1.0,0.0) [0.0|1] ""  Vector__XXX
 SG_ ZV_verriegelt_extern_soll : 19|1@1+ (1.0,0.0) [0.0|1] ""  CDI,ICC_IO_Node,OCU,ZR_MIB_EINSTIEG_ab_Gen3,ZR_MIB_OPTION_ab_Gen3,ZR_MIB_TOP_ab_Gen3
 SG_ ZV_gesafet_extern_ist : 20|1@1+ (1.0,0.0) [0.0|1] ""  OCU
 SG_ ZV_gesafet_extern_soll : 21|1@1+ (1.0,0.0) [0.0|1] ""  Vector__XXX
 SG_ ZV_Einzeltuerentriegelung : 22|1@1+ (1.0,0.0) [0.0|1] ""  Vector__XXX
 SG_ ZV_Heckeinzelentriegelung : 23|1@1+ (1.0,0.0) [0.0|1] ""  OCU
 SG_ ZV_FT_offen : 24|1@1+ (1.0,0.0) [0.0|1] ""  CDI,ICC_IO_Node,OCU,ZR_MIB_EINSTIEG_ab_Gen3,ZR_MIB_OPTION_ab_Gen3,ZR_MIB_TOP_ab_Gen3
 SG_ ZV_BT_offen : 25|1@1+ (1.0,0.0) [0.0|1] ""  CDI,ICC_IO_Node,OCU,ZR_MIB_EINSTIEG_ab_Gen3,ZR_MIB_OPTION_ab_Gen3,ZR_MIB_TOP_ab_Gen3
 SG_ ZV_HFS_offen : 26|1@1+ (1.0,0.0) [0.0|1] ""  CDI,ICC_IO_Node,OCU,ZR_MIB_EINSTIEG_ab_Gen3,ZR_MIB_OPTION_ab_Gen3,ZR_MIB_TOP_ab_Gen3
 SG_ ZV_HBFS_offen : 27|1@1+ (1.0,0.0) [0.0|1] ""  CDI,ICC_IO_Node,OCU,ZR_MIB_EINSTIEG_ab_Gen3,ZR_MIB_OPTION_ab_Gen3,ZR_MIB_TOP_ab_Gen3
 SG_ ZV_HD_offen : 28|1@1+ (1.0,0.0) [0.0|1] ""  ICC_IO_Node,OCU,ZR_MIB_EINSTIEG_ab_Gen3,ZR_MIB_OPTION_ab_Gen3,ZR_MIB_TOP_ab_Gen3
 SG_ ZV_HS_offen : 29|1@1+ (1.0,0.0) [0.0|1] ""  Vector__XXX
 SG_ IRUE_aktiv : 30|1@1+ (1.0,0.0) [0.0|1] ""  Vector__XXX
 SG_ DWA_aktiv : 31|1@1+ (1.0,0.0) [0.0|1] ""  OCU
 SG_ HD_Hauptraste : 32|1@1+ (1.0,0.0) [0.0|1] ""  OCU
 SG_ HD_Vorraste : 33|1@1+ (1.0,0.0) [0.0|1] ""  Vector__XXX
 SG_ FFB_HDF_Taste : 34|1@1+ (1.0,0.0) [0.0|1] ""  Vector__XXX
 SG_ FFB_Panik_Taste : 35|1@1+ (1.0,0.0) [0.0|1] ""  Vector__XXX
 SG_ FFB_Auf_Taste : 36|1@1+ (1.0,0.0) [0.0|1] ""  Vector__XXX
 SG_ FFB_Zu_Taste : 37|1@1+ (1.0,0.0) [0.0|1] ""  Vector__XXX
 SG_ FFB_CarFinder : 38|1@1+ (1.0,0.0) [0.0|1] ""  Vector__XXX
 SG_ FFB_Komfortoeffnen : 39|1@1+ (1.0,0.0) [0.0|1] ""  Vector__XXX
 SG_ FFB_Komfortschliessen : 40|1@1+ (1.0,0.0) [0.0|1] ""  Vector__XXX
 SG_ FBS_IDG_in_Reichweite : 41|1@1+ (1.0,0.0) [0.0|1] ""  Vector__XXX
 SG_ ZV_Schluessel_Zugang : 42|4@1+ (1.0,0.0) [0.0|15] ""  OCU
 SG_ ZV_SafeFunktion_aktiv : 46|1@1+ (1.0,0.0) [0.0|1] ""  Vector__XXX
 SG_ FBS_Warn_Schluessel_Batt : 47|1@1+ (1.0,0.0) [0.0|1] ""  Vector__XXX
 SG_ ZV_Oeffnungsmodus : 48|2@1+ (1.0,0.0) [0.0|3] ""  Vector__XXX
 SG_ HFS_verriegelt : 50|1@1+ (1.0,0.0) [0.0|1] ""  OCU
 SG_ HFS_gesafet : 51|1@1+ (1.0,0.0) [0.0|1] ""  OCU
 SG_ HBFS_verriegelt : 52|1@1+ (1.0,0.0) [0.0|1] ""  OCU
 SG_ HBFS_gesafet : 53|1@1+ (1.0,0.0) [0.0|1] ""  OCU
 SG_ ZV_ist_Zustand_verfuegbar : 54|1@1+ (1.0,0.0) [0.0|1] ""  Vector__XXX
 SG_ IRUE_Taster_Fkts_LED : 55|1@1+ (1.0,0.0) [0.0|1] ""  Vector__XXX
 SG_ ZV_Tankklappe_offen : 56|1@1+ (1.0,0.0) [0.0|1] ""  OCU
 SG_ ZV_Rollo_auf : 57|1@1+ (1.0,0.0) [0.0|1] ""  OCU
 SG_ ZV_Rollo_zu : 58|1@1+ (1.0,0.0) [0.0|1] ""  OCU
 SG_ ZV_SAD_auf : 59|1@1+ (1.0,0.0) [0.0|1] ""  Vector__XXX
 SG_ ZV_SAD_zu : 60|1@1+ (1.0,0.0) [0.0|1] ""  Vector__XXX
 SG_ BCM_Tankklappensteller_Fehler : 61|1@1+ (1.0,0.0) [0.0|1] ""  OCU
 SG_ ZV_verriegelt_soll : 62|2@1+ (1.0,0.0) [0.0|3] ""  OCU

BO_TX_BU_ 2589283611 :Gateway_Max,ZR_MIB_EINSTIEG_ab_Gen3,ZR_MIB_OPTION_ab_Gen3,ZR_MIB_TOP_ab_Gen3;
BO_TX_BU_ 2527679836 :Gateway_Max,ZR_MIB_EINSTIEG_ab_Gen3,ZR_MIB_OPTION_ab_Gen3,ZR_MIB_TOP_ab_Gen3;
BO_TX_BU_ 1140 :ICC_IO_Node,ZR_MIB_EINSTIEG_ab_Gen3,ZR_MIB_OPTION_ab_Gen3,ZR_MIB_TOP_ab_Gen3;
BO_TX_BU_ 2589283965 :ZR_MIB_EINSTIEG_ab_Gen3,ZR_MIB_OPTION_ab_Gen3,ZR_MIB_TOP_ab_Gen3;
BO_TX_BU_ 2463978864 :Gateway_Max,ZR_MIB_OPTION_ab_Gen3;
CM_ BO_ 995 "ab MQB IS5";
CM_ BO_ 1716 "200ms bei D4 und folgende";
CM_ BO_ 916 "ersetzt WBA_02";
CM_ BO_ 1702 "MLBevo";

CM_ SG_ 975 ASW_Warnung_aktiv_HBFS "Abschaltung der Ambientefunktion Tür hinten der Beifahrerseite bei aktiver ASW Warnung an der Fahrertür";
CM_ SG_ 975 HBFS_FH_Bew_hoch "HBFS Fenster bewegt sich in Richtung hoch";
CM_ SG_ 975 HBFS_FH_Bew_tief "HBFS Fenster bewegt sich in Richtung tief";
CM_ SG_ 975 HBFS_FH_Block "Fensterscheibe befindet sich im mechanischen Block (oben oder unten)";
CM_ SG_ 975 HBFS_FH_Fang "Fangbereich ist 4mm von oberer Lippendichtung";
CM_ SG_ 975 HBFS_FH_normiert "Die Position der Fensterheberscheibe ist bekannt.";
CM_ SG_ 975 HBFS_FH_Oeffnung "Gibt den Fensteröffnungswert in % an.";
CM_ SG_ 975 HBFS_FH_S_AutoHoch "Betaetigung FH Schalter auto tief ";
CM_ SG_ 975 HBFS_FH_S_AutoTief "Betaetigung FH Schalter auto hoch";
CM_ SG_ 975 HBFS_FH_S_HFS_AutoHoch "Automatisches Hochfahren der Seitenscheibe HFS";
CM_ SG_ 975 HBFS_FH_S_HFS_AutoTief "Automatisches Absenken der Seitenscheibe HFS";
CM_ SG_ 975 HBFS_FH_S_HFS_ManHoch "Manuelles Hochfahren der Seitenscheibe HFS";
CM_ SG_ 975 HBFS_FH_S_HFS_ManTief "Manuelles Absenken der Seitenscheibe HFS";
CM_ SG_ 975 HBFS_FH_S_ManHoch "Betaetigung FH Schalter man hoch ";
CM_ SG_ 975 HBFS_FH_S_ManTief "Betaetigung FH Schalter man tief";
CM_ SG_ 975 HBFS_FH_Thermo "gibt an ob Fensterheber im Thermoschutz ist";
CM_ SG_ 975 HBFS_gesafet "HBFS Tuer gesafet.
Im Zustand Safe wird auch das Signal HBFS_verriegelt = 1 gesendet.";
CM_ SG_ 975 HBFS_Heckrollotaster_betaetigt "Verfahren des Heckrollos in Richtung Hoch

Bei Einfachtaster wird Bit als Togglebit verwendet (Heckrollo hoch, tief)";
CM_ SG_ 975 HBFS_Lock_Taster "Betaetigung Lock-Taster";
CM_ SG_ 975 HBFS_Lock_Taster_inv "Lock Taster nicht betätigt";
CM_ SG_ 975 HBFS_MRollo_Schalter "  | MRollo2
-----------------------------
0 | nicht_betaetigt
1 | (m) Zu
2 | (a) Zu
3 | (m) Auf
4 | (a) Auf
5 | Schalter nicht verfuegbar
6 | Init
7 | Fehlerfall";
CM_ SG_ 975 HBFS_Oben_Block_erw "Fensterheber in Blockerwartung oben";
CM_ SG_ 975 HBFS_SAD_Schalter "  |   Ausstelldach MD3
-----------------------------
0 | nicht_betaetigt
1 |
2 |
3 |
4 |
5 | (m) Auf
6 | (a) Auf
7 | (m) Zu
8 | (a) Zu
13| Schalter nicht verfuegbar
14| Init
15| Fehlerfall";
CM_ SG_ 975 HBFS_Seitenrollo_tief "Seitenrollo in Bewegung Richtung tief";
CM_ SG_ 975 HBFS_SK_betaetigt "Status der Sperrklinke";
CM_ SG_ 975 HBFS_Sperrklinke "Vorraste für Schloß

zwischen Vor- und Hauptraste Signal kurz auf 1, danach wieder auf 0 wenn Tür in Hauptraste (Tür ist sicher zu wenn Sperrklinke und Türkontakt auf 0 sind)";
CM_ SG_ 975 HBFS_Status_eTAG "Status des elektrischen Tueraussengriffes Tuer Beifahrerseite hinten";
CM_ SG_ 975 HBFS_Status_KiSi "Status Kindersicherung HBFS
";
CM_ SG_ 975 HBFS_Status_KiSi_inv "Inverser Status der elektrischen Kindersicherung Beifahrerseite hinten";
CM_ SG_ 975 HBFS_TAG_betaetigt "Betaetigung Türaussengriff";
CM_ SG_ 975 HBFS_TIG_betaetigt "Betaetigung Tuerinnengriff";
CM_ SG_ 975 HBFS_TIG_betaetigt_oeffnen "Türinnenbetätigung, Taster Tür öffnen.";
CM_ SG_ 975 HBFS_TIG_betaetigt_schliessen "Türinnenbetätigung, Taster Tür schließen.";
CM_ SG_ 975 HBFS_Tuer_geoeffnet "HBFS Tuer geoeffnet";
CM_ SG_ 975 HBFS_Tuer_Status "Türstatus mit Fehler und Initwert";
CM_ SG_ 975 HBFS_Tuer_Status_QBit "Dieses Bit gibt die Zuverlässigkeit des Türkontakts an. Ein auf dieses Bit folgender Fehlereintrag ist mit dem Sender des Bits abzustimmen (gültig ab PPE).";
CM_ SG_ 975 HBFS_Tueroeffnen_Warnung "Bit wird gesetzt, wenn Tür während der Fahrt geoeffnet werden soll.";
CM_ SG_ 975 HBFS_Tuerschloss_defekt "Das hintere Tuerschloss auf der Beifahrerseite ist nicht mehr funktionsfähig.";
CM_ SG_ 975 HBFS_UEKB_aktiviert "Überschutzbegrenzungskraft bei Reversieren";
CM_ SG_ 975 HBFS_Unlock_Taster "Betaetigung Unlock Taster";
CM_ SG_ 975 HBFS_Unten_Block_erw "Fensterheber in Blockerwartung unten";
CM_ SG_ 975 HBFS_verriegelt "Verriegelungsstatus Tür";
CM_ SG_ 975 HBFS_Vorraste_betaetigt "Status der Vorraste";
CM_ SG_ 975 HBFS_Zuziehhilfe_aktiv "Zuziehhilfe aktiv";
CM_ SG_ 975 MTHBFS_M_Taste "Betätigung M-Taste HBFS";
CM_ SG_ 975 MTHBFS_Pos1 "Betätigung Postionstaste 1 HBFS";
CM_ SG_ 975 MTHBFS_Pos2 "Betätigung Postionstaste 2 HBFS
";
CM_ SG_ 975 MTHBFS_Pos3 "Betätigung Postionstaste 3 HBFS";
CM_ SG_ 975 SSR_HBFS_Pos_Unten "Signal für die 'Global Close'. Über dieses Bit wissen die anderen TSGs, ob der SSR oder der FH verfahren werden darf.";

CM_ SG_ 974 ASW_Warnung_aktiv_HFS "Abschaltung der Ambientefunktion Tür hinten der Fahrerseite bei aktiver ASW Warnung an der Fahrertür";
CM_ SG_ 974 HFS_FH_Bew_hoch "HFS Fenster bewegt sich in Richtung hoch";
CM_ SG_ 974 HFS_FH_Bew_tief "HFS Fenster bewegt sich in Richtung tief";
CM_ SG_ 974 HFS_FH_Block "Fensterscheibe befindet sich im mechanischen Block (oben oder unten)";
CM_ SG_ 974 HFS_FH_Fang "Fangbereich ist 4mm von oberer Lippendichtung";
CM_ SG_ 974 HFS_FH_normiert "Die Position der Fensterheberscheibe ist bekannt.";
CM_ SG_ 974 HFS_FH_Oeffnung "Gibt den Fensteröffnungswert in % an.";
CM_ SG_ 974 HFS_FH_S_AutoHoch "Betaetigung FH Schalter auto hoch";
CM_ SG_ 974 HFS_FH_S_AutoTief "Betaetigung FH Schalter auto tief ";
CM_ SG_ 974 HFS_FH_S_HBFS_AutoHoch "Automatisches Hochfahren der Seitenscheibe HBFS";
CM_ SG_ 974 HFS_FH_S_HBFS_AutoTief "Automatisches Absenken der Seitenscheibe HBFS";
CM_ SG_ 974 HFS_FH_S_HBFS_ManHoch "Manuelles Hochfahren der Seitenscheibe HBFS";
CM_ SG_ 974 HFS_FH_S_HBFS_ManTief "Manuelles Absenken der Seitenscheibe HBFS";
CM_ SG_ 974 HFS_FH_S_ManHoch "Betaetigung FH Schalter man hoch ";
CM_ SG_ 974 HFS_FH_S_ManTief "Betaetigung FH Schalter man tief";
CM_ SG_ 974 HFS_FH_Thermo "gibt an ob Fensterheber im Thermoschutz ist";
CM_ SG_ 974 HFS_gesafet "HFS Tuer gesafet.
Im Zustand Safe wird auch das Signal HFS_verriegelt = 1 gesendet.";
CM_ SG_ 974 HFS_Heckrollotaster_betaetigt "Verfahren des Heckrollos in Richtung Hoch

Bei Einfachtaster wird Bit als Togglebit verwendet (Heckrollo hoch, tief)";
CM_ SG_ 974 HFS_Lock_Taster "Betätigung Lock-Taster";
CM_ SG_ 974 HFS_Lock_Taster_inv "Lock Taster nicht betätigt";
CM_ SG_ 974 HFS_MRollo_Schalter "  | MRollo2
-----------------------------
0 | nicht_betaetigt
1 | (m) Zu
2 | (a) Zu
3 | (m) Auf
4 | (a) Auf
5 | Schalter nicht verfuegbar
6 | Init
7 | Fehlerfall";
CM_ SG_ 974 HFS_Oben_Block_erw "Fensterheber in Blockerwartung oben";
CM_ SG_ 974 HFS_SAD_Schalter "  |   Ausstelldach MD3
-----------------------------
0 | nicht_betaetigt
1 |
2 |
3 |
4 |
5 | (m) Auf
6 | (a) Auf
7 | (m) Zu
8 | (a) Zu
13| Schalter nicht verfuegbar
14| Init
15| Fehlerfall";
CM_ SG_ 974 HFS_Seitenrollo_hoch "Seitenrollo in Bewegung Richtung hoch";
CM_ SG_ 974 HFS_Seitenrollo_tief "Seitenrollo in Bewegung Richtung tief";
CM_ SG_ 974 HFS_SK_betaetigt "Status der Sperrklinke";
CM_ SG_ 974 HFS_Sperrklinke "Vorraste für Schloß

zwischen Vor- und Hauptraste Signal kurz auf 1, danach wieder auf 0 wenn Tür in Hauptraste (Tür ist sicher zu wenn Sperrklinke und Türkontakt auf 0 sind)";
CM_ SG_ 974 HFS_Status_eTAG "Status des elektrischen Tueraussengriffes Tuer Fahrerseite hinten";
CM_ SG_ 974 HFS_Status_KiSi "Status Kindersicherung hinten Fahrerseite";
CM_ SG_ 974 HFS_TAG_betaetigt "Betaetigung Türaussengriff";
CM_ SG_ 974 HFS_TCR_Mode_aktiv "Signal zeigt eine aktive mechanische Redundanz am Türschloss an.";
CM_ SG_ 974 HFS_TIG_betaetigt "Betaetigung Türinnengriff";
CM_ SG_ 974 HFS_TIG_betaetigt_oeffnen "Türinnenbetätigung, Taster Tür öffnen.";
CM_ SG_ 974 HFS_TIG_betaetigt_schliessen "Türinnenbetätigung, Taster Tür schließen.";
CM_ SG_ 974 HFS_Tuer_geoeffnet "HFS Tuer geoeffnet";
CM_ SG_ 974 HFS_Tuer_Status "Türstatus mit Fehler und Initwert";
CM_ SG_ 974 HFS_Tuer_Status_QBit "Dieses Bit gibt die Zuverlässigkeit des Türkontakts an. Ein auf dieses Bit folgender Fehlereintrag ist mit dem Sender des Bits abzustimmen (gültig ab PPE).";
CM_ SG_ 974 HFS_Tueroeffnen_Warnung "Bit wird gesetzt, wenn Tür während der Fahrt geoeffnet werden soll.";
CM_ SG_ 974 HFS_Tuerschloss_defekt "Das hintere Tuerschloss auf der Fahrerseite ist nicht mehr funktionsfähig.";
CM_ SG_ 974 HFS_UEKB_aktiviert "Überschutzbegrenzungskraft bei Reversieren";
CM_ SG_ 974 HFS_Unlock_Taster "Betaetigung Unlock Taster";
CM_ SG_ 974 HFS_Unten_Block_erw "Fensterheber in Blockerwartung unten";
CM_ SG_ 974 HFS_verriegelt "HFS Tuer verriegelt";
CM_ SG_ 974 HFS_Vorraste_betaetigt "Status der Vorraste";
CM_ SG_ 974 HFS_Zuziehhilfe_aktiv "Zuziehhilfe aktiv";
CM_ SG_ 974 MTHFS_M_Taste "Betätigung M-Taste HFS";
CM_ SG_ 974 MTHFS_Pos1 "Betätigung Postionstaste 1 HFS";
CM_ SG_ 974 MTHFS_Pos2 "Betätigung Postionstaste 2 HFS
";
CM_ SG_ 974 MTHFS_Pos3 "Betätigung Postionstaste 3 HFS";
CM_ SG_ 974 SSR_HFS_Pos_Unten "Signal für die 'Global Close'. Über dieses Bit wissen die anderen TSGs, ob der SSR oder der FH verfahren werden darf.";

CM_ SG_ 1718 UH_Minute "0x3C- 0x3f = Werte ungültig";
CM_ SG_ 1718 UH_Monat "0x0D, 0xF =  Werte ungültig
0x0E = Relatives Datum (nur VW)";
CM_ SG_ 1718 UH_Sekunde "0x3C- 0x3f = Werte ungültig";
CM_ SG_ 1718 UH_Stunde "0x18 - 0x1F = Werte ungültig";
CM_ SG_ 1718 UH_Tag "0x0: reserviert bei VW";
CM_ SG_ 1718 UH_Typ "0x4 - 0x7 = tbd. ";

CM_ SG_ 2463978710 OPS_ComfortReadyStatus "Das Signal wird durch den Basisdienst User State Server (Technikvariante: OccupantPresenceService) erzeugt und bildet einen neuen Zustand, bestehend aus einer Verknüpfung der Fahreranwesenheit (Fahrer abwesend / Fahrer anwesend) und der Klemmensteuerung (";
CM_ SG_ 2463978710 OPS_DriverPresenceStatus "Das Signal wird durch den Basisdienst User State Server (Service: OccupantPresenceService) erzeugt und bildet die Fahrerzustände im Fahrzeug ab.";
CM_ SG_ 2463978710 OPS_OccupantPresenceStatus "Das Signal wird durch den Basisdienst User State Server (Service: OccupantPresenceService) erzeugt und bildet die Anwesenheit und Abwesenheit aller Insassen im Fahrzeug ab.";
CM_ SG_ 2463978710 OPS_QBit_DriverPresence "Das Signal wird durch den Basisdienst User State Server (Service: OccupantPresenceService) erzeugt und signalisiert die Qualität der Fahrerzustände.";
CM_ SG_ 2463978710 OPS_SafeDriverPresence_available "Das Signal signalisiert inwiefern alle vorgesehene Sensoren  für die Anwesenheit verwendet werden oder möglichweise bestimmte Sensoren nicht verfügbar sind.
In beiden Fällen wird eine Anwesenheit berechnet, jedoch bei Ausfall bestimmter Sensoren kann zu ";
CM_ SG_ 2463978710 OPS_SafeDriverPresenceStatus "Signalisierung einer sicheren Fahreranwesenheit nach ASIL B";
CM_ SG_ 2463978710 UserStateServer_01_BZ "4bit Botschaftszähler, wird mit jeder Sendebotschaft inkrementiert";
CM_ SG_ 2463978710 UserStateServer_01_CRC "Für MLB:
Berechnung siehe Lastenheft 'Kommunikationsabsicherung für FlexRay und CAN'
Ab MQB und MLBevo:
Berechnung siehe Lastenheft 'End-to-End Kommunikationsabsicherung'

Endwerte siehe Begleitdokument 'S-PDU Kennungsfolgen'";

CM_ SG_ 995 VD_SpannungsAnf "Anforderung Forderung des Verdecks zur Spannungsanhebung des Bordnetzes.";
CM_ SG_ 995 VS_BFS_AutoHoch "automatischer Hochlauf des BFS Fenster ausgelöst durch die Verdecksteuerung";
CM_ SG_ 995 VS_BFS_AutoTief "automatischer Tieflauf des BFS Fenster ausgelöst durch die Verdecksteuerung";
CM_ SG_ 995 VS_BFS_ManHoch "manueller Hochlauf des BFS Fenster ausgelöst durch die Verdecksteuerung";
CM_ SG_ 995 VS_BFS_ManTief "manueller Tieflauf des BFS Fenster ausgelöst durch die Verdecksteuerung";
CM_ SG_ 995 VS_Buzzer "Buzzeransteuerung: 'Buzzeransteuerung' für Gong 200ms (Kombi)";
CM_ SG_ 995 VS_FH_BT_Langhub "Ansteuerung Fensterheber vom Verdecksteuergeraet";
CM_ SG_ 995 VS_FH_FT_Langhub "Ansteuerung Fensterheber vom Verdecksteuergeraet";
CM_ SG_ 995 VS_FH_HBFS_Langhub "Ansteuerung Fensterheber vom Verdecksteuergeraet";
CM_ SG_ 995 VS_FH_HFS_Langhub "Ansteuerung Fensterheber vom Verdecksteuergeraet";
CM_ SG_ 995 VS_FS_AutoHoch "automatischer Hochlauf des FS Fenster ausgelöst durch die Verdecksteuerung";
CM_ SG_ 995 VS_FS_AutoTief "automatischer Tieflauf des FS Fenster ausgelöst durch die Verdecksteuerung";
CM_ SG_ 995 VS_FS_ManHoch "manueller Hochlauf des FS Fenster ausgelöst durch die Verdecksteuerung";
CM_ SG_ 995 VS_FS_ManTief "manueller Tieflauf des FS Fenster ausgelöst durch die Verdecksteuerung";
CM_ SG_ 995 VS_Hardtop "Hardtop montiert";
CM_ SG_ 995 VS_HBFS_AutoHoch "automatischer Hochlauf des HBFS Fenster ausgelöst durch die Verdecksteuerung";
CM_ SG_ 995 VS_HBFS_AutoTief "automatischer Tieflauf des HBFS Fenster ausgelöst durch die Verdecksteuerung";
CM_ SG_ 995 VS_HBFS_ManHoch "manueller Hochlauf des HBFS Fenster ausgelöst durch die Verdecksteuerung";
CM_ SG_ 995 VS_HBFS_ManTief "manueller Tieflauf des HBFS Fenster ausgelöst durch die Verdecksteuerung";
CM_ SG_ 995 VS_HD_sperren "Bei gesetztem Signal wird der Kofferraum/Heckdeckel durch den BCM2 nicht entriegelt werden.";
CM_ SG_ 995 VS_Heckschloss_auf "Signal wird gesetzt, wenn fuer einen Verdeckbetrieb das Öffnen des Heckschlosses erforderlich ist.";
CM_ SG_ 995 VS_HFS_AutoHoch "automatischer Hochlauf des HFS Fenster ausgelöst durch die Verdecksteuerung";
CM_ SG_ 995 VS_HFS_AutoTief "automatischer Tieflauf des HFS Fenster ausgelöst durch die Verdecksteuerung";
CM_ SG_ 995 VS_HFS_ManHoch "manueller Hochlauf des HFS Fenster ausgelöst durch die Verdecksteuerung";
CM_ SG_ 995 VS_HFS_ManTief "manueller Tieflauf des HFS Fenster ausgelöst durch die Verdecksteuerung";
CM_ SG_ 995 VS_HHS_enable "Fehlende Beschreibung (Import)";
CM_ SG_ 995 VS_Lampe_Blk "Ansteuerung Lampe im Kombi

Wird aktiviert bei Aufprüfen, Verdecklauf und Fehlerfall (blinkend).


";
CM_ SG_ 995 VS_StartStopp_Info "Stopp-Freigabe und Start-Anforderung an den Start-Stopp-Koordinator";
CM_ SG_ 995 VS_VD_Bew_auf "



";
CM_ SG_ 995 VS_VD_Bew_zu "


";
CM_ SG_ 995 VS_VD_entriegelt "Zustand des Verdeck entriegelt";
CM_ SG_ 995 VS_VD_Fehler "Fehlerzustand Verdeck";
CM_ SG_ 995 VS_VD_offen_ver "Zustand des Verdecks verriegelt und offen";
CM_ SG_ 995 VS_VD_zu_ver "
";
CM_ SG_ 995 VS_VD_Zwischenposition "Verdeck in Zwischenposition";
CM_ SG_ 995 VS_VDKD_auf "Signal wird gesetzt, wenn der Verdeckkastendeckel vollstaendig geoeffnet ist



";
CM_ SG_ 995 VS_Verdeck_Anf "Verdeckanforderung (Signalisierung der Bereitschaft zur Verdeckbetaetigung ueber Komfortfunktion)";
CM_ SG_ 995 VS_Windschott_nicht_abgelegt "Windschott ist aufgestellt, in Zwischenposition oder die Position ist unbekannt";
CM_ SG_ 995 VSG_Meldungen "Meldungen fuers Kombi lt. konzernübergreifender Abstimmung

0 -> keine Meldung
1 -> 'Verdeckbetrieb RDW aktiv'
2 -> 'Verdeckbetrieb NAR aktiv'
3 -> 'stehendes Verdeck in Zwischenposition (ZP)'
4 -> 'autom. Verdeck in ZP und KL15 aus'
5 -> 'manuelle";

CM_ SG_ 1716 VIN_01_MUX "Achtung:
Die Botschaft ist nicht linear gemultiplext!!!
Sondern 0,1,0,2,0, usw.";
CM_ SG_ 1716 VIN_1 "Initwert:
0x2D bei Fahrzeugen mit Wegfahrsperrengeneration >= 5 
0x58 bei Fahrzeugen mit Wegfahrsperrengeneration < 5 (z.B. WFS-4)";
CM_ SG_ 1716 VIN_10 "Initwert:
0x2D bei Fahrzeugen mit Wegfahrsperrengeneration >= 5 
0x58 bei Fahrzeugen mit Wegfahrsperrengeneration < 5 (z.B. WFS-4)";
CM_ SG_ 1716 VIN_11 "Initwert:
0x2D bei Fahrzeugen mit Wegfahrsperrengeneration >= 5 
0x58 bei Fahrzeugen mit Wegfahrsperrengeneration < 5 (z.B. WFS-4)";
CM_ SG_ 1716 VIN_12 "Initwert:
0x2D bei Fahrzeugen mit Wegfahrsperrengeneration >= 5 
0x58 bei Fahrzeugen mit Wegfahrsperrengeneration < 5 (z.B. WFS-4)";
CM_ SG_ 1716 VIN_13 "Initwert:
0x2D bei Fahrzeugen mit Wegfahrsperrengeneration >= 5 
0x58 bei Fahrzeugen mit Wegfahrsperrengeneration < 5 (z.B. WFS-4)";
CM_ SG_ 1716 VIN_14 "Initwert:
0x2D bei Fahrzeugen mit Wegfahrsperrengeneration >= 5 
0x58 bei Fahrzeugen mit Wegfahrsperrengeneration < 5 (z.B. WFS-4)";
CM_ SG_ 1716 VIN_15 "Initwert:
0x2D bei Fahrzeugen mit Wegfahrsperrengeneration >= 5 
0x58 bei Fahrzeugen mit Wegfahrsperrengeneration < 5 (z.B. WFS-4)";
CM_ SG_ 1716 VIN_16 "Initwert:
0x2D bei Fahrzeugen mit Wegfahrsperrengeneration >= 5 
0x58 bei Fahrzeugen mit Wegfahrsperrengeneration < 5 (z.B. WFS-4)";
CM_ SG_ 1716 VIN_17 "Initwert:
0x2D bei Fahrzeugen mit Wegfahrsperrengeneration >= 5 
0x58 bei Fahrzeugen mit Wegfahrsperrengeneration < 5 (z.B. WFS-4)";
CM_ SG_ 1716 VIN_2 "Initwert:
0x2D bei Fahrzeugen mit Wegfahrsperrengeneration >= 5 
0x58 bei Fahrzeugen mit Wegfahrsperrengeneration < 5 (z.B. WFS-4)";
CM_ SG_ 1716 VIN_3 "Initwert:
0x2D bei Fahrzeugen mit Wegfahrsperrengeneration >= 5 
0x58 bei Fahrzeugen mit Wegfahrsperrengeneration < 5 (z.B. WFS-4)";
CM_ SG_ 1716 VIN_4 "Initwert:
0x2D bei Fahrzeugen mit Wegfahrsperrengeneration >= 5 
0x58 bei Fahrzeugen mit Wegfahrsperrengeneration < 5 (z.B. WFS-4)";
CM_ SG_ 1716 VIN_5 "Initwert:
0x2D bei Fahrzeugen mit Wegfahrsperrengeneration >= 5 
0x58 bei Fahrzeugen mit Wegfahrsperrengeneration < 5 (z.B. WFS-4)";
CM_ SG_ 1716 VIN_6 "Initwert:
0x2D bei Fahrzeugen mit Wegfahrsperrengeneration >= 5 
0x58 bei Fahrzeugen mit Wegfahrsperrengeneration < 5 (z.B. WFS-4)";
CM_ SG_ 1716 VIN_7 "Initwert:
0x2D bei Fahrzeugen mit Wegfahrsperrengeneration >= 5 
0x58 bei Fahrzeugen mit Wegfahrsperrengeneration < 5 (z.B. WFS-4)";
CM_ SG_ 1716 VIN_8 "Initwert:
0x2D bei Fahrzeugen mit Wegfahrsperrengeneration >= 5 
0x58 bei Fahrzeugen mit Wegfahrsperrengeneration < 5 (z.B. WFS-4)";
CM_ SG_ 1716 VIN_9 "Initwert:
0x2D bei Fahrzeugen mit Wegfahrsperrengeneration >= 5 
0x58 bei Fahrzeugen mit Wegfahrsperrengeneration < 5 (z.B. WFS-4)";

CM_ SG_ 916 GE_Sollgang "Signalisiert den Sollgang, in den getippt werden soll. Abhängig vom Signal 'WBA_eing_Gang_02' und dem Sollgang kann dann das Kombi die Hochschaltempfehlung in Tip darstellen.";
CM_ SG_ 916 GE_Stoppverbot_Anz_01 "Dieses Signal gibt die detaillierte Begründung für ein Stoppverbot vom Getriebesteuergerät an.";
CM_ SG_ 916 GE_Stoppverbot_Anz_02 "Dieses Signal gibt die detaillierte Begründung für ein Stoppverbot vom Getriebesteuergerät an.";
CM_ SG_ 916 GE_Stoppverbot_Anz_03 "Dieses Signal gibt die detaillierte Begründung für ein Stoppverbot vom Getriebesteuergerät an.";
CM_ SG_ 916 GE_Stoppverbot_Anz_04 "Dieses Signal gibt die detaillierte Begründung für ein Stoppverbot vom Getriebesteuergerät an.";
CM_ SG_ 916 GE_Stoppverbot_Anz_05 "Dieses Signal gibt die detaillierte Begründung für ein Stoppverbot vom Getriebesteuergerät an.";
CM_ SG_ 916 GE_Stoppverbot_Anz_06 "Dieses Signal gibt die detaillierte Begründung für ein Stoppverbot vom Getriebesteuergerät an.";
CM_ SG_ 916 GE_Stoppverbot_Anz_07 "Dieses Signal gibt die detaillierte Begründung für ein Stoppverbot vom Getriebesteuergerät an.";
CM_ SG_ 916 GE_Stoppverbot_Anz_Std "Dieses Signal gibt die detaillierte Begründung für ein Stoppverbot vom Getriebesteuergerät an.";
CM_ SG_ 916 GE_Tipschaltempf_verfuegbar "Signalisierung, ob eine Hochschaltempfehlung im Tipmodus verfügbar ist oder nicht.";
CM_ SG_ 916 GE_Wiederstart_Anz_Std "Dieses Signal gibt die detaillierte Begründung für einen Wiederstart vom Getriebesteuergerät an. ";
CM_ SG_ 916 WBA_03_CRC "Für MLB:
'Berechnung siehe Lastenheft 'Kommunikationsabsicherung für FlexRay und CAN''

Ab MQB und MLBevo:
'Berechnung siehe Lastenheft 'End-to-End Kommunikationsabsicherung''

Endwerte siehe Begleitdokument 'S-PDU Kennungsfolgen'";
CM_ SG_ 916 WBA_Anforderung_Akustik "Anforderung eines Signaltons bei Anwahl der Fahrstufe R";
CM_ SG_ 916 WBA_Blinken "Dieses Bit steuert die Fehlerlampe an oder wird zum Blinken der WBA-Anzeige genutzt - nur falls WBA_Senderkennung = 00 (GSG)
";
CM_ SG_ 916 WBA_eing_Gang_02 "Das Automatikgetriebe gibt den aktuell eingelegten Gang aus.
Besonderheiten:
0x0 = marktabhängig wird auf Ganganzeige zur Fahrstufe komplett verzichtet
0xA = kurzzeitige Unterdrückung der Ganganzeige (z. B. Segeln, Zwischenstellung, etc.)";
CM_ SG_ 916 WBA_Fahrstufe_02 "Bei Automatgetrieben wird in diesem Signal die aktuelle anzuzeigende Fahrstufe ausgegeben.

Die Signalkodierungen 0x9, 0xA und 0xB werden im MSS-R8NF und MQB-A1/B/A2 verwendet.

Die Signalkodierungen 0xC und 0xD werden nur im MQB-A1/B/A2 verwendet.
";
CM_ SG_ 916 WBA_GE_Texte "Fahrerhinweise für das Kombi";
CM_ SG_ 916 WBA_GE_Texte_02 "Fahrerhinweise für das Kombi";
CM_ SG_ 916 WBA_GE_Warnung_02 "Prioritätswarnungen Getriebe";
CM_ SG_ 916 WBA_GE_Zusatzwarnungen "Prioritaetswarnungen Getriebe an Kombi
Audi MLB Wertebereich 0 bis 3
VW MQB Projekte verwenden nur den Wertebereich 0 bis 2
VW MQB Getriebefehler werden über das Signal  GE_Warnungen_02 gesendet.";
CM_ SG_ 916 WBA_Schaltschema_02 "Basis-Layout des Schaltschemas zur Anzeige im Kombiinstrument";
CM_ SG_ 916 WBA_Schaltschema_Fahreraktion "Signalisiert Fahreraktion an der Schaltbetaetigung";
CM_ SG_ 916 WBA_Schaltschema_FS_inaktiv "Gibt an, welche Fahrstufen innerhalb von WBA_Schaltschema_02 aktuell nicht erreichbar sind (z.B. aufgrund zu hoher Fahrzeuggeschwindigkeit oder fehlender Fahrbereitschaft).";
CM_ SG_ 916 WBA_Schaltschema_FS_vorwaerts "Zeigt an, welche der zwei Vorwärtsfahrstufen aktiv ist und ob in die inaktive geschaltet werden kann.";
CM_ SG_ 916 WBA_Schaltschema_Tippgasse "Zeigt den Verbau einer Tippgasse zur Anzeige im Schaltschema an.";
CM_ SG_ 916 WBA_Segeln_aktiv "Getriebe geht in den Segelbetrieb";
CM_ SG_ 916 WBA_Shiftlock_Lampe "Signalisiert dem Kombi, dass die Shiftlock-Lampe (grünes 'Bremse treten' Symbol) anzuzeigen ist.

Anmerkung: Signal ist nur von Kombis auszuwerten, die die Shiftlock-Info über Soft- oder Hard-LED und nicht als reine Textmeldung anzeigen.";
CM_ SG_ 916 WBA_ZielFahrstufe "Zielfahrprogramm (Darstellung), für getipptes S/E/M mit neuem Wählhebel im MQB";

CM_ SG_ 1361 WFS_Betrieb_Lesespule "Schlüsselkommunikation über die Lesespule";
CM_ SG_ 1361 WFS_ELV_authorisiert "Authorisierung der elektrischen Lenkungsverriegelung an der WFS";
CM_ SG_ 1361 WFS_Fahrerhinweise "Meldungen, Fahrer- und Warnhinweise der Wegfahrsperre";
CM_ SG_ 1361 WFS_ID_Geb_autorisiert "Authorisierung Schluessel (ID-Geber)";
CM_ SG_ 1361 WFS_ID_Geb_autorisiert_in_Kl15 "Authorisierung des Schlüssels im aktiven Klemme-15-Zyklus";
CM_ SG_ 1361 WFS_ID_Geb_steckt "Schluessel (ID-Geber) im Zuendschloss
";
CM_ SG_ 1361 WFS_Klemmenfreigabe "Freigabe von der WFS zum Einschalten der Klemme 15 und Klemme S";
CM_ SG_ 1361 WFS_Klemmenfreigabe_Signatur "Signatur zur Klemmenfreigabe durch die WFS";
CM_ SG_ 1361 WFS_LF_Aktiv "LF Schluesselkommunikation
";
CM_ SG_ 1361 WFS_LZ "Anforderung aus Lastenheft WFS V
";
CM_ SG_ 1361 WFS_Parken_Status "Schnittstelle zwischen WFS und ZFAS für das Pilotierte Parken um in Richtung ZFAS den Status der WFS im BCM2 zu kommunizieren";
CM_ SG_ 1361 WFS_Safe "Status WFS";
CM_ SG_ 1361 WFS_Schluessel_Fahrberecht "Schlüsselnummer Fahrberechtigung
0 = ungueltig, xxxx = Schluessel-Nr.";
CM_ SG_ 1361 WFS_Schluessel_Ist "Istwert der gelernten Schluessel";
CM_ SG_ 1361 WFS_Schluessel_Soll "Sollwert der zu lernenden Schluessel";
CM_ SG_ 1361 WFS_Verbauinfo_ELV "Info über die Konfiguration der ELV im WFS-Master";

CM_ SG_ 1702 BCM1_SRA_aktiv "Status Scheinwerferreinigungsanlage";
CM_ SG_ 1702 Heckwischer_Anforderung "Das Signal beschreibt die Anforderung an den Signalausgang im BCM2 zur Ansteuerung des Heckwischers.";
CM_ SG_ 1702 Waschen_vorne_aktiv "Status: Waschen vorne aktiv";
CM_ SG_ 1702 Wischer1_Wischgeschwindigkeit "aktuelle, durch Sensorik gemessene Wischgeschwindigkeit";
CM_ SG_ 1702 Wischer_Anzeigetext "Das Signal fordert einen Kombi-Pop-Up mit entsprechenden Texten an";
CM_ SG_ 1702 Wischer_vorne_aktiv "Status: Wischer vorne";
CM_ SG_ 1702 Wischer_vorne_blockiert "Blockade Wischer vorne (z.B. durch Schnee)";
CM_ SG_ 1702 Wischer_vorne_defekt "Fehlerstatus Wischer vorne (Anzeige im Kombi)";
CM_ SG_ 1702 Wischer_vorne_Normal "Wischer Front normal aktiv";
CM_ SG_ 1702 Wischer_vorne_Parklage "Wischer Front in Parklage";
CM_ SG_ 1702 Wischer_vorne_Schnell "Wischer vorne schnell aktiv";
CM_ SG_ 1702 Wischer_WH_PopUp_Anf "Anzeige von Wischerstufen im Kombi.";
CM_ SG_ 1702 Wischer_WH_Typ "Signal beinhaltet Lenkstockschaltertyp für grafische Anzeige im Kombi zur Wischerfunktion";
CM_ SG_ 1702 WWSs_01_alt "Veraltet Bit für die LIN-Botschaft WWSs_01.

Betroffene Signale:

Wischer_vorne_aktiv";

CM_ SG_ 2589283611 WLC1_aktive_Spule "Active_Coil";
CM_ SG_ 2589283611 WLC1_Charger_Effizienz "Charger charging (Efficiency in % )
0 = no charging 
1 = charging with 1%
10 = charging with 10 %";
CM_ SG_ 2589283611 WLC1_Charger_laedt "Charger charging (übertragene Leistung) (0,1W)

0 = no charging 
1 = charging with 0,1 Watt
10 = charging with 1 Watt";
CM_ SG_ 2589283611 WLC1_Fehler "Übermittelt auftretende Fehler des WLC an das Master-SG zur Ablage im dort verorteten Fehlerspeicher";
CM_ SG_ 2589283611 WLC1_Fremdobjekt_erkannt "Messwert/Anzeige Fremdobjekt erkannt";
CM_ SG_ 2589283611 WLC1_Leistungsklasse_Receiver "Performance_Class_Receiver
0 = no Device
1 = class with 0,1 Watt
10 = class with 1 Watt";
CM_ SG_ 2589283611 WLC1_Objekt_erkannt "non wireless Charging Device in the storage box ";
CM_ SG_ 2589283611 WLC1_Receiver_erkannt "wireless Charging Device (Phone) is in the storage box ";
CM_ SG_ 2589283611 WLC1_Receiver_voll_geladen "0 = WLC not fully charged or no Device available
1 = WLC Device fully charged ";
CM_ SG_ 2589283611 WLC1_Temp_Leistungsteil_Charger "Temperature_Power_Electronics
0 = -58 °C
1 = -57 °C
..";
CM_ SG_ 2589283611 WLC1_Temp_Oberfaeche_Charger "Surface_Temperature_WLC
0 = -58 °C
1 = -57 °C
..";
CM_ SG_ 2589283611 WLC1_Temp_Receiver "Temperature_Receiver
0 = -58 °C
1 = -57 °C
..";
CM_ SG_ 2589283611 WLC1_verwendeter_Ladestandard "WLC_technology";

CM_ SG_ 2527679836 WLC1_ChargingEfficiency "This signal contains the charging efficiency in per cent of WLC1.";
CM_ SG_ 2527679836 WLC1_ChargingStatus "This signal contains the charging status of WLC1.";
CM_ SG_ 2527679836 WLC1_UsedChargingStandard "This signal contains the used charging standard of WLC1.";

CM_ SG_ 2527679837 WLC2_ChargingEfficiency "This signal contains the charging efficiency in per cent of WLC2.";
CM_ SG_ 2527679837 WLC2_ChargingStatus "This signal contains the charging status of WLC2.";
CM_ SG_ 2527679837 WLC2_UsedChargingStandard "This signal contains the used charging standard of WLC2.";

CM_ SG_ 1140 DI_Screendesign "Information welcher Designwunsch ausgewählt wurde zur Kennlinienumschaltung";
CM_ SG_ 1140 MMI_State "Powerstate des Zentralrechners. MMI_Off wird im Zustand dead mode gesendet.";
CM_ SG_ 1140 SI_ICAN "MQB: Busruhe ICAN.
E3: Busruhe ABCAN.";
CM_ SG_ 1140 WLC1_Systemzustand "0 = Wireless Charger off (Message produced by HMI)
1 = Wireless Charger on (Message produced by HMI)";
CM_ SG_ 1140 WLC2_Systemzustand "0 = Wireless Charger off
1 = Wireless Charger on";
CM_ SG_ 1140 ZR_DimOffs_DU_1 "Dimmungs-Offset der Display Unit.";
CM_ SG_ 1140 ZR_DimOffs_DU_2 "Dimmungs-Offset der Display Unit.";
CM_ SG_ 1140 ZR_DimOffs_DU_3 "Dimmungs-Offset der Display Unit.";
CM_ SG_ 1140 ZR_DimOffs_DU_4 "Dimmungs-Offset der Display Unit.";
CM_ SG_ 1140 ZR_Lenkerposition "Ueber Diagnose (Codierung) im Zentralrechner eingespeicherte Lenkerposition
  ";
CM_ SG_ 1140 ZR_State_DU_1 "Kontrollbit für Display, Hintergrundbeleuchtung aus, Hintergrundbeleuchtung an, Energiesparmodus.
";
CM_ SG_ 1140 ZR_State_DU_2 "Kontrollbit für Display, Hintergrundbeleuchtung aus, Hintergrundbeleuchtung an, Energiesparmodus.
";
CM_ SG_ 1140 ZR_State_DU_3 "Kontrollbit für Display, Hintergrundbeleuchtung aus, Hintergrundbeleuchtung an, Energiesparmodus.
";
CM_ SG_ 1140 ZR_State_DU_4 "Kontrollbit für Display, Hintergrundbeleuchtung aus, Hintergrundbeleuchtung an, Energiesparmodus.";
CM_ SG_ 1140 ZR_WecktGesp "Befehl zum Sperren der Wecktasten am Bedienteil.";

CM_ SG_ 2589283965 DFB_CILState_ADA "Gibt den Status der Bedieneingaben im ABT hinsichtlich der Kritikalität auf die Unaufmerksamkeit des Fahrers an.";
CM_ SG_ 2589283965 DFB_InteractionStatus_ADA "Gibt an, ob eine Bedieneingabe vom Kunde im ABT durchgeführt wurde.";
CM_ SG_ 2589283965 FaceRec2_Control_Challenge_Req "When IAA receives this signal it will provide a challenge via FaceRec2_Control_Challenge.

Duplicate of FaceRec signals for usage in separate messages using not SOK but own application level protection.";
CM_ SG_ 2589283965 Info_El_Lade_Fehler "Status Bit für Funktionsfähigkeit des MIB3 nach OBD-Anforderungen, Kundenfahrzeufunktion Erweiterte Ladefunktion";
CM_ SG_ 2589283965 SpeechAssistant_State "This signal contain the information if a speech assistant is active or not.";
CM_ SG_ 2589283965 ZR_Plattform "Fahrzeug-Plattform (vom Zentralrechner am I-CAN bzw. AB-CAN genutzte Datenfestlegungsversion)";

CM_ SG_ 2463978864 ZR_BedienDisp_X_contr_iClima_av "If iCLimate chosen function is availible to control";
CM_ SG_ 2463978864 ZR_BedienDisp_X_control_fct "Function, which will be active (controlled by rotary knob, visible on rotary knob display)";
CM_ SG_ 2463978864 ZR_BedienDisp_X_control_iClima "iClimate function, which is current active";
CM_ SG_ 2463978864 ZR_BedienDisp_X_control_MapMode "Current map mode";
CM_ SG_ 2463978864 ZR_BedienDisp_X_control_MapZoom "Map zooming signal";
CM_ SG_ 2463978864 ZR_BedienDisp_X_control_Point "number of selected preferred profiles";
CM_ SG_ 2463978864 ZR_BedienDisp_X_control_sound "Source of Audio signal";
CM_ SG_ 2463978864 ZR_BedienDisp_X_control_surround "Current HMI Surround Pegel";
CM_ SG_ 2463978864 ZR_BedienDisp_X_control_vol "Current volume value";
CM_ SG_ 2463978864 ZR_BedienDisp_X_control_vol_max "Current volume maximum value";
CM_ SG_ 2463978864 ZR_BedienDisp_X_control_vol_min "Current volume minimum value";
CM_ SG_ 2463978864 ZR_BedienDisp_X_fokus_zone "Current HMI Sound Fokus Zone";
CM_ SG_ 2463978864 ZR_BedienDisp_X_navidot_position "This signal highlights the corresponding active navidot position in middle rotary knob’s GUI";

CM_ SG_ 388 BCM_BF_Spg_Absenkung "Spiegelabsenkung Beifahrerseite";
CM_ SG_ 388 BCM_Spg_Synchron "Anforderung zur Aktivierung der synchronen Spiegelverstellung";
CM_ SG_ 388 FH_BT_hoch "Freigabeinformation fuer die FH-Komfortfunktion";
CM_ SG_ 388 FH_BT_tief "Freigabeinformation fuer die FH-Komfortfunktion";
CM_ SG_ 388 FH_FT_hoch "Freigabeinformation fuer die FH-Komfortfunktion";
CM_ SG_ 388 FH_FT_tief "Freigabeinformation fuer die FH-Komfortfunktion";
CM_ SG_ 388 FH_HBFS_hoch "Freigabeinformation fuer die FH-Komfortfunktion";
CM_ SG_ 388 FH_HBFS_tief "Freigabeinformation fuer die FH-Komfortfunktion";
CM_ SG_ 388 FH_HFS_hoch "Freigabeinformation fuer die FH-Komfortfunktion";
CM_ SG_ 388 FH_HFS_tief "Freigabeinformation fuer die FH-Komfortfunktion";
CM_ SG_ 388 VIP_Freigabe "Vituelles Pedal ist über HMI freigeschaltet.";
CM_ SG_ 388 VIP_Sensor_betaetigt "Heckentriegelung durch die Bedienstelle Virtuelles Pedal(VIP) erkannt. Der VIP Sensor hat eine Fusskickbewegung erkannt und es wurde ein Kessy - Schlüssel im Heckaussenbereich erkannt.";
CM_ SG_ 388 ZV_01_CRC "Für MLB:
'Berechnung siehe Lastenheft 'Kommunikationsabsicherung für FlexRay und CAN''

Ab MQB und MLBevo:
'Berechnung siehe Lastenheft 'End-to-End Kommunikationsabsicherung''

Endwerte siehe Begleitdokument 'S-PDU Kennungsfolgen'";
CM_ SG_ 388 ZV_auf_BT "ZV Schliessstelle";
CM_ SG_ 388 ZV_auf_FT "ZV Schliessstelle";
CM_ SG_ 388 ZV_auf_Funk "ZV Schliessstelle";
CM_ SG_ 388 ZV_auf_Kessy "ZV Schliessstelle";
CM_ SG_ 388 ZV_auto_Ansteuerung "Kennung für die automatische Ansteuerung der Zentralverriegelung (Autolock/Autounlock)";
CM_ SG_ 388 ZV_BT_entriegeln "Beifahrertür entriegeln (Anforderung ZV)";
CM_ SG_ 388 ZV_BT_verriegeln "Verriegelungsanforderung ZV für BT";
CM_ SG_ 388 ZV_entriegeln_Anf "Bei ZV Anforderung erfolgt die Entriegelung des Ladesteckers";
CM_ SG_ 388 ZV_FT_entriegeln "Entriegelungsanforderung ZV für FT";
CM_ SG_ 388 ZV_FT_verriegeln "Verriegelungsanforderung ZV für FT";
CM_ SG_ 388 ZV_HBFS_entriegeln "Entriegelungsanforderung ZV für HBFS
";
CM_ SG_ 388 ZV_HBFS_verriegeln "Verriegelungsanforderung ZV für HBFS
";
CM_ SG_ 388 ZV_HFS_entriegeln "Entriegelungsanforderung ZV für HFS
";
CM_ SG_ 388 ZV_HFS_verriegeln "Verriegelungsanforderung ZV für HFS
";
CM_ SG_ 388 ZV_HSK_entriegeln "Anforderungssignal zur Ansteuerung des Handschuhkastenmotors in Richtung Entriegeln. ";
CM_ SG_ 388 ZV_HSK_verriegeln "Anforderungssignal zur Ansteuerung des Handschuhkastenmotors in Richtung Verriegeln. ";
CM_ SG_ 388 ZV_LED_Steuerung "Ansteuerung der LED's in den Tueren; BAF gilt nicht für dieses Bit";
CM_ SG_ 388 ZV_LED_Uebernahme "Uebernahme der LED Steuerung durch das TSG FT";
CM_ SG_ 388 ZV_Signatur "Signatur der ZV";
CM_ SG_ 388 ZV_Softtouch_betaetigt "Betätigung Softtouch";
CM_ SG_ 388 ZV_Spg_Anklappen "Anforderung über ZV: Spiegel sind anzuklappen";
CM_ SG_ 388 ZV_Verdeck_auf "Anforderungssignal für ein Komfortöffnen des Verdecks. 
Signal wird angefordert wenn  SKontakt = 0 und eine Doppelbetätigung Schließzylinder_auf oder Funkfernbedienung_Taste_auf  innerhalb zwei Sekunden empfangen wird. Signal wird auch angefordert wenn S";
CM_ SG_ 388 ZV_Verdeck_zu "Anforderungssignal für ein Komfortschließen des Verdecks. 
Signal wird angefordert wenn  SKontakt = 0 und eine Doppelbetätigung Schließzylinder_Zu oder Funkfernbedienung_Taste_zu  innerhalb zwei Sekunden empfangen wird. Signal wird auch angefordert wenn ";
CM_ SG_ 388 ZV_zentral_entsafen "Zentral entsafen";
CM_ SG_ 388 ZV_zentral_safen "Zentral safen";
CM_ SG_ 388 ZV_zu_BT "ZV Schliessstelle";
CM_ SG_ 388 ZV_zu_FT "ZV Schliessstelle";
CM_ SG_ 388 ZV_zu_Funk "ZV Schliessstelle";
CM_ SG_ 388 ZV_zu_Kessy "ZV Schliessstelle";
CM_ SG_ 388 ZV_zu_Zeitl_Nachverr "ZV Schliessstelle";

CM_ SG_ 1411 BCM_FH_Freigabe "Funktionsfreigabe Fensterheber";
CM_ SG_ 1411 BCM_HSK_Freigabe "Handschuhkastenfreigabe";
CM_ SG_ 1411 BCM_Komfortfkt_Freigabe "globale Freigabe der Komfortfunktion";
CM_ SG_ 1411 BCM_Tankklappensteller_Fehler "Fehler: nicht Funktionalität des Tankklappenstellers";
CM_ SG_ 1411 BCM_Verdeck_Freigabe "Freigabe Verdeckbetrieb
";
CM_ SG_ 1411 DWA_aktiv "Status DWA  aktiv";
CM_ SG_ 1411 FBS_IDG_in_Reichweite "Für elektrisch betätigte Türen und Klappen muss für eine Betätigung über Funk eine Reichweitenbegrenzung eingeführt werden. Diese Bit zeigt an, dass sich der Funkschlüssel innerhalb der geforderten Reichweite befindet";
CM_ SG_ 1411 FBS_Warn_Schluessel_Batt "Kombi Prio Warnung Schluessel Batterie
'Bitte Schlüsselbatterie wechseln!'";
CM_ SG_ 1411 FFB_Auf_Taste "Auf-Taste Funkschluessel

";
CM_ SG_ 1411 FFB_CarFinder "Car Finder Funktion (Blinken ohne zu entriegeln)";
CM_ SG_ 1411 FFB_HDF_Taste "HDF Taste am Funkschluessel
";
CM_ SG_ 1411 FFB_Komfortoeffnen "Komfortoeffnen Funk
";
CM_ SG_ 1411 FFB_Komfortschliessen "Komfortschliessen Funk
";
CM_ SG_ 1411 FFB_Panik_Taste "Panik Taste Funkschluessel
";
CM_ SG_ 1411 FFB_Zu_Taste "Zu-Taste Funkschluessel
";
CM_ SG_ 1411 HBFS_gesafet "HBFS Tuer gesafet.
Im Zustand Safe wird auch das Signal HBFS_verriegelt = 1 gesendet.";
CM_ SG_ 1411 HBFS_verriegelt "Verriegelungsstatus Tür";
CM_ SG_ 1411 HD_Hauptraste "SBL-Schloss (MQB/MLBevo): Drehfalle Heckdeckel
sonst (MQB): Hauptraste Heckdeckel";
CM_ SG_ 1411 HD_Vorraste "SBL_Schloss (MQB/MLBevo): Sperrklinke Heckdeckel
sonst (MQB): Vorraste Heckdeckel";
CM_ SG_ 1411 HFS_gesafet "HFS Tuer gesafet.
Im Zustand Safe wird auch das Signal HFS_verriegelt = 1 gesendet.";
CM_ SG_ 1411 HFS_verriegelt "HFS Tuer verriegelt";
CM_ SG_ 1411 IRUE_aktiv "Status Innenraumüberwachung
";
CM_ SG_ 1411 IRUE_Taster_Fkts_LED "Anforderung Funktions-LED IRUE-Taster (LED wird vom TSG angesteuert)
MQB: Bei Verbau eines einzelnen Taster zur Deaktivierung von IRUE und NGS wird dieses Signal zur Ansteuerung der Funktions-LED gesendet.";
CM_ SG_ 1411 VIP_Sensor_STSG_HBFS_betaetigt "Schiebetürlauf HBFS wurde durch VIP angefordert und als berechtigt eingestuft.";
CM_ SG_ 1411 VIP_Sensor_STSG_HFS_betaetigt "Schiebetürlauf HFS wurde durch VIP angefordert und als berechtigt eingestuft.";
CM_ SG_ 1411 ZV_Anf_Challenge_Auth "Anforderung an alle beteiligten Steuergeräte die Challenge an den ZV-Master zu senden.";
CM_ SG_ 1411 ZV_BT_offen "gespiegeltes Bit BT_Tuer_geoeffnet TSG_BT_1 Botschaft";
CM_ SG_ 1411 ZV_Einzeltuerentriegelung "Einzeltürentriegelung ZV
";
CM_ SG_ 1411 ZV_eRWK_Umfeld_Pruefung "Anforderung an PDC/PLA im eRWK-Modus eine Umfeldprüfung durchzuführen";
CM_ SG_ 1411 ZV_FT_offen "gespiegeltes Bit FT_Tuer_geoeffnet TSG_FT_1 Botschaft";
CM_ SG_ 1411 ZV_gesafet_extern_ist "Istzustand: Fahrzeug aussen gesafet
";
CM_ SG_ 1411 ZV_gesafet_extern_soll "Sollzustand: Fahrzeug gesafet extern
";
CM_ SG_ 1411 ZV_HBFS_offen "gespiegeltes Bit HBFS_Tuer_geoeffnet TSG_HBFS_1 Botschaft";
CM_ SG_ 1411 ZV_HD_offen "Status Heckdeckel
";
CM_ SG_ 1411 ZV_Heckeinzelentriegelung "Heckdeckeleinzelentriegelung";
CM_ SG_ 1411 ZV_HFS_offen "gespiegeltes Bit HFS_Tuer_geoeffnet TSG_HFS_1 Botschaft";
CM_ SG_ 1411 ZV_HS_offen "Status Heckscheibe
";
CM_ SG_ 1411 ZV_ist_Zustand_verfuegbar "Verfügbarkeit IST-Zustand ZV

";
CM_ SG_ 1411 ZV_Oeffnungsmodus "Konfigurierter Oeffnungsmodus fuer ZV:
0 = globale Oeffnung (alle Tueren)
1 = ZV mit Einzeltuerentriegelung (FFB - nur Fahrertuer, Kessy - nur bediente Tuer)
2 = ZV individuell selektive Oeffnung (FFB - Fahrerseite, Kessy - bediente Tuer + Fahrertuer)";
CM_ SG_ 1411 ZV_Rollo_auf "Komfortöffnen des Dachrollos";
CM_ SG_ 1411 ZV_Rollo_zu "Komfortschließen des Dachrollos";
CM_ SG_ 1411 ZV_SAD_auf "Komfortöffnen des Schiebeausstelldaches";
CM_ SG_ 1411 ZV_SAD_zu "Komfortschließen des Schiebeausstelldaches";
CM_ SG_ 1411 ZV_SafeFunktion_aktiv "Statusübermittlung ob die Safe Funktion im Fzg. aktiv ist. Das Kombi benötigt das Signal, um den Text Safelock aktiv anzuzeigen. ";
CM_ SG_ 1411 ZV_Schluessel_Zugang "aktuelle Funkschlüsselnummer";
CM_ SG_ 1411 ZV_STSG_Crashzustand "Statusübermittlung ob der Crashzustand der Schiebetüren dauerhaft im Fzg. aktiv ist. Das Kombi benötigt das Signal, um die Meldung anzuzeigen.";
CM_ SG_ 1411 ZV_STSG_eKiSi_defekt "Statusübermittlung ob die elektronische Kindersicherung der Schiebetüren im Fzg. defekt ist. Das Kombi benötigt das Signal, um die Meldung anzuzeigen.";
CM_ SG_ 1411 ZV_STSG_HBFS_Anf "Die ZV fordert einen Lauf bzw. Stopp der Schiebetür an.";
CM_ SG_ 1411 ZV_STSG_HFS_Anf "Die ZV fordert einen Lauf bzw. Stopp der Schiebetür an.";
CM_ SG_ 1411 ZV_Tankklappe_offen "Öffnungsstatus der Tankklappe";
CM_ SG_ 1411 ZV_verriegeln_Anf "Gesammelte externe ZV-Verriegelungsanforderung des Kunden (z. B. zur Aktivierung der Anzeige des Ladezustands über Aussenlicht).";
CM_ SG_ 1411 ZV_verriegelt_extern_ist "Istzustand: Verriegelung Fahrzeug aussen
";
CM_ SG_ 1411 ZV_verriegelt_extern_soll "Sollzustand: Verriegelung Fahrzeug aussen
";
CM_ SG_ 1411 ZV_verriegelt_intern_ist "Istzustand: Verriegelung Fahrzeug innen
";
CM_ SG_ 1411 ZV_verriegelt_intern_soll "Sollzustand: Verriegelung Fahrzeug innen
";
CM_ SG_ 1411 ZV_verriegelt_soll "Fahrzeug Gesamtverriegelungsstatus Sollzustand für Ladestecker- und Ladeklappenverriegelung. ";
BA_DEF_REL_ BU_SG_REL_  "GenSigTimeoutTime" INT 0 65535;
BA_DEF_ BO_  "DiagRequest" ENUM "No", "Yes";
BA_DEF_ BO_  "DiagResponse" ENUM "No", "Yes";
BA_DEF_ BO_  "DiagState" ENUM "No", "Yes";
BA_DEF_ BO_  "GenMsgChkConstant" HEX 0 4095;
BA_DEF_ BO_  "GenMsgCycleTime" INT 0 65535;
BA_DEF_ BO_  "GenMsgCycleTimeFast" INT 0 65535;
BA_DEF_ BO_  "GenMsgDelayTime" INT 0 100000;
BA_DEF_ BO_  "GenMsgILSupport" ENUM "No", "Yes";
BA_DEF_ BO_  "GenMsgNrOfRepetition" INT 0 100;
BA_DEF_ BO_  "GenMsgPDUConstants" STRING;
BA_DEF_ BO_  "GenMsgSendType" ENUM "Cyclic", "not_used", "not_used", "not_used", "not_used", "not_used", "not_used", "IfActive", "NoMsgSendType";
BA_DEF_ BO_  "GenMsgStartDelayTime" INT 0 100000;
BA_DEF_ BO_  "NmMessage" ENUM "No", "Yes";
BA_DEF_ BO_  "NmhMessage" ENUM "No", "Yes";
BA_DEF_ BO_  "MsgType" ENUM "Application", "NM ", "NMH", "TP2.0", "ISO-TP ", "BAP", "EID", "KS", "XCP_PRE_CONFIGURED", "XCP_RUNTIME_CONFIGURED";
BA_DEF_ BO_  "VAGTP20_API" HEX 0 255;
BA_DEF_ BO_  "VAGTP20_DynConnection" ENUM "No", "Yes";
BA_DEF_ BO_  "VAGTP20_DynSetup" ENUM "No", "Yes";
BA_DEF_ BO_  "VAGTP20_StatConnection" ENUM "No", "Yes";
BA_DEF_ SG_  "GenSigActiveRepetitions" INT -2147483648 2147483647;
BA_DEF_ SG_  "GenSigInactiveValue" INT -2147483648 2147483647;
BA_DEF_ SG_  "GenSigSendType" ENUM "Cyclic", "OnWrite", "OnWriteWithRepetition", "OnChange", "OnChangeWithRepetition", "IfActive", "IfActiveWithRepetition", "NoSigSendType", "OnChangeAndIfActive", "OnChangeAndIfActiveWithRepetition";
BA_DEF_ SG_  "GenSigStartValue" INT -2147483648 2147483647;
BA_DEF_ SG_  "NWM-WakeupAllowed" ENUM "No", "Yes";
BA_DEF_ SG_  "GenSigFuncType" ENUM "NoFunction", "MsgCounter", "CRC-8", "XOR", "XOR-2", "DatedBit", "SW-Kl15", "CHK", "Constant", "Protocol", "CRC-8-SAE_J1850", "CRC-32", "DataLength", "DataID", "MsgCounter16", "SOK-Signatur", "Cluster";
BA_DEF_ SG_  "GenSigSwitchedByIgnition" ENUM "No", "Yes";
BA_DEF_ SG_  "Fehlerwert" HEX 0 2147483647;
BA_DEF_ SG_  "GenSigMissingSourceValue" HEX 0 2147483647;
BA_DEF_DEF_REL_  "GenSigTimeoutTime" 0;
BA_DEF_DEF_  "DiagRequest" "No";
BA_DEF_DEF_  "DiagResponse" "No";
BA_DEF_DEF_  "DiagState" "No";
BA_DEF_DEF_  "GenMsgChkConstant" 0;
BA_DEF_DEF_  "GenMsgCycleTime" 0;
BA_DEF_DEF_  "GenMsgCycleTimeFast" 0;
BA_DEF_DEF_  "GenMsgDelayTime" 0;
BA_DEF_DEF_  "GenMsgILSupport" "No";
BA_DEF_DEF_  "GenMsgNrOfRepetition" 0;
BA_DEF_DEF_  "GenMsgPDUConstants" "";
BA_DEF_DEF_  "GenMsgSendType" "NoMsgSendType";
BA_DEF_DEF_  "GenMsgStartDelayTime" 0;
BA_DEF_DEF_  "NmMessage" "No";
BA_DEF_DEF_  "NmhMessage" "No";
BA_DEF_DEF_  "MsgType" "Application";
BA_DEF_DEF_  "VAGTP20_API" 0;
BA_DEF_DEF_  "VAGTP20_DynConnection" "No";
BA_DEF_DEF_  "VAGTP20_DynSetup" "No";
BA_DEF_DEF_  "VAGTP20_StatConnection" "No";
BA_DEF_DEF_  "GenSigActiveRepetitions" 0;
BA_DEF_DEF_  "GenSigInactiveValue" 0;
BA_DEF_DEF_  "GenSigSendType" "NoSigSendType";
BA_DEF_DEF_  "GenSigStartValue" 0;
BA_DEF_DEF_  "NWM-WakeupAllowed" "No";
BA_DEF_DEF_  "GenSigFuncType" "NoFunction";
BA_DEF_DEF_  "GenSigSwitchedByIgnition" "Yes";
BA_DEF_DEF_  "Fehlerwert" 0;
BA_DEF_DEF_  "GenSigMissingSourceValue" 0;
BA_ "GenMsgCycleTime" BO_ 975 100;
BA_ "GenMsgDelayTime" BO_ 975 20;
BA_ "GenMsgILSupport" BO_ 975 1;
BA_ "GenMsgSendType" BO_ 975 0;
BA_ "GenMsgCycleTime" BO_ 974 100;
BA_ "GenMsgDelayTime" BO_ 974 20;
BA_ "GenMsgILSupport" BO_ 974 1;
BA_ "GenMsgSendType" BO_ 974 0;
BA_ "GenMsgCycleTime" BO_ 1718 1000;
BA_ "GenMsgILSupport" BO_ 1718 1;
BA_ "GenMsgSendType" BO_ 1718 0;
BA_ "GenMsgCycleTime" BO_ 2463978710 100;
BA_ "GenMsgCycleTimeFast" BO_ 2463978710 10;
BA_ "GenMsgDelayTime" BO_ 2463978710 10;
BA_ "GenMsgILSupport" BO_ 2463978710 1;
BA_ "GenMsgNrOfRepetition" BO_ 2463978710 5;
BA_ "GenMsgPDUConstants" BO_ 2463978710 "0xf3,0xbb,0x4c,0x48,0x05,0x08,0x69,0xc8,0x60,0x76,0x27,0x02,0x3a,0xa8,0x32,0x51";
BA_ "GenMsgSendType" BO_ 2463978710 0;
BA_ "GenMsgCycleTime" BO_ 995 100;
BA_ "GenMsgCycleTimeFast" BO_ 995 50;
BA_ "GenMsgDelayTime" BO_ 995 50;
BA_ "GenMsgILSupport" BO_ 995 1;
BA_ "GenMsgNrOfRepetition" BO_ 995 5;
BA_ "GenMsgSendType" BO_ 995 0;
BA_ "GenMsgCycleTime" BO_ 1716 200;
BA_ "GenMsgILSupport" BO_ 1716 1;
BA_ "GenMsgSendType" BO_ 1716 0;
BA_ "GenMsgCycleTime" BO_ 916 160;
BA_ "GenMsgCycleTimeFast" BO_ 916 10;
BA_ "GenMsgDelayTime" BO_ 916 10;
BA_ "GenMsgILSupport" BO_ 916 1;
BA_ "GenMsgNrOfRepetition" BO_ 916 3;
BA_ "GenMsgPDUConstants" BO_ 916 "0x47,0x94,0x92,0x6a,0x67,0xb5,0x0d,0x38,0xe3,0x8a,0x5d,0xb4,0x54,0xab,0xae,0x27";
BA_ "GenMsgSendType" BO_ 916 0;
BA_ "GenMsgCycleTime" BO_ 1361 200;
BA_ "GenMsgDelayTime" BO_ 1361 50;
BA_ "GenMsgILSupport" BO_ 1361 1;
BA_ "GenMsgSendType" BO_ 1361 0;
BA_ "GenMsgCycleTime" BO_ 1702 1000;
BA_ "GenMsgDelayTime" BO_ 1702 50;
BA_ "GenMsgILSupport" BO_ 1702 1;
BA_ "GenMsgSendType" BO_ 1702 0;
BA_ "GenMsgCycleTime" BO_ 2589283611 1000;
BA_ "GenMsgDelayTime" BO_ 2589283611 40;
BA_ "GenMsgILSupport" BO_ 2589283611 1;
BA_ "GenMsgSendType" BO_ 2589283611 0;
BA_ "GenMsgCycleTime" BO_ 2527679836 1000;
BA_ "GenMsgDelayTime" BO_ 2527679836 50;
BA_ "GenMsgILSupport" BO_ 2527679836 1;
BA_ "GenMsgSendType" BO_ 2527679836 0;
BA_ "GenMsgCycleTime" BO_ 2527679837 1000;
BA_ "GenMsgDelayTime" BO_ 2527679837 50;
BA_ "GenMsgILSupport" BO_ 2527679837 1;
BA_ "GenMsgSendType" BO_ 2527679837 0;
BA_ "MsgType" BO_ 2617059072 6;
BA_ "MsgType" BO_ 2617059073 6;
BA_ "GenMsgCycleTime" BO_ 1140 1000;
BA_ "GenMsgDelayTime" BO_ 1140 40;
BA_ "GenMsgILSupport" BO_ 1140 1;
BA_ "GenMsgSendType" BO_ 1140 0;
BA_ "GenMsgCycleTime" BO_ 2589283965 500;
BA_ "GenMsgDelayTime" BO_ 2589283965 100;
BA_ "GenMsgILSupport" BO_ 2589283965 1;
BA_ "GenMsgSendType" BO_ 2589283965 0;
BA_ "GenMsgCycleTime" BO_ 2463978864 1000;
BA_ "GenMsgDelayTime" BO_ 2463978864 30;
BA_ "GenMsgILSupport" BO_ 2463978864 1;
BA_ "GenMsgSendType" BO_ 2463978864 0;
BA_ "GenMsgCycleTime" BO_ 388 1000;
BA_ "GenMsgCycleTimeFast" BO_ 388 20;
BA_ "GenMsgILSupport" BO_ 388 1;
BA_ "GenMsgNrOfRepetition" BO_ 388 5;
BA_ "GenMsgPDUConstants" BO_ 388 "0xe3,0xe8,0xc4,0x7f,0xf1,0x95,0xd8,0xb0,0xc7,0xa3,0xf4,0x6c,0xe7,0xc3,0x5a,0xf7";
BA_ "GenMsgSendType" BO_ 388 0;
BA_ "GenMsgCycleTime" BO_ 1411 200;
BA_ "GenMsgCycleTimeFast" BO_ 1411 50;
BA_ "GenMsgDelayTime" BO_ 1411 20;
BA_ "GenMsgILSupport" BO_ 1411 1;
BA_ "GenMsgNrOfRepetition" BO_ 1411 3;
BA_ "GenMsgSendType" BO_ 1411 0;
BA_ "GenSigSendType" SG_ 975 ASW_Warnung_aktiv_HBFS 3;
BA_ "GenSigSwitchedByIgnition" SG_ 975 ASW_Warnung_aktiv_HBFS 0;
BA_ "GenSigSendType" SG_ 975 HBFS_FH_Bew_hoch 3;
BA_ "GenSigSwitchedByIgnition" SG_ 975 HBFS_FH_Bew_hoch 0;
BA_ "GenSigSendType" SG_ 975 HBFS_FH_Bew_tief 3;
BA_ "GenSigSwitchedByIgnition" SG_ 975 HBFS_FH_Bew_tief 0;
BA_ "GenSigSendType" SG_ 975 HBFS_FH_Block 3;
BA_ "GenSigSwitchedByIgnition" SG_ 975 HBFS_FH_Block 0;
BA_ "GenSigSendType" SG_ 975 HBFS_FH_Fang 3;
BA_ "GenSigSwitchedByIgnition" SG_ 975 HBFS_FH_Fang 0;
BA_ "GenSigSendType" SG_ 975 HBFS_FH_normiert 3;
BA_ "GenSigSwitchedByIgnition" SG_ 975 HBFS_FH_normiert 0;
BA_ "GenSigSendType" SG_ 975 HBFS_FH_Oeffnung 3;
BA_ "GenSigSwitchedByIgnition" SG_ 975 HBFS_FH_Oeffnung 0;
BA_ "GenSigSendType" SG_ 975 HBFS_FH_S_AutoHoch 3;
BA_ "GenSigSwitchedByIgnition" SG_ 975 HBFS_FH_S_AutoHoch 0;
BA_ "GenSigSendType" SG_ 975 HBFS_FH_S_AutoTief 3;
BA_ "GenSigSwitchedByIgnition" SG_ 975 HBFS_FH_S_AutoTief 0;
BA_ "GenSigSendType" SG_ 975 HBFS_FH_S_HFS_AutoHoch 3;
BA_ "GenSigSwitchedByIgnition" SG_ 975 HBFS_FH_S_HFS_AutoHoch 0;
BA_ "GenSigSendType" SG_ 975 HBFS_FH_S_HFS_AutoTief 3;
BA_ "GenSigSwitchedByIgnition" SG_ 975 HBFS_FH_S_HFS_AutoTief 0;
BA_ "GenSigSendType" SG_ 975 HBFS_FH_S_HFS_ManHoch 3;
BA_ "GenSigSwitchedByIgnition" SG_ 975 HBFS_FH_S_HFS_ManHoch 0;
BA_ "GenSigSendType" SG_ 975 HBFS_FH_S_HFS_ManTief 3;
BA_ "GenSigSwitchedByIgnition" SG_ 975 HBFS_FH_S_HFS_ManTief 0;
BA_ "GenSigSendType" SG_ 975 HBFS_FH_S_ManHoch 3;
BA_ "GenSigSwitchedByIgnition" SG_ 975 HBFS_FH_S_ManHoch 0;
BA_ "GenSigSendType" SG_ 975 HBFS_FH_S_ManTief 3;
BA_ "GenSigSwitchedByIgnition" SG_ 975 HBFS_FH_S_ManTief 0;
BA_ "GenSigSendType" SG_ 975 HBFS_FH_Thermo 3;
BA_ "GenSigSwitchedByIgnition" SG_ 975 HBFS_FH_Thermo 0;
BA_ "GenSigSendType" SG_ 975 HBFS_gesafet 3;
BA_ "GenSigSwitchedByIgnition" SG_ 975 HBFS_gesafet 0;
BA_ "GenSigSendType" SG_ 975 HBFS_Heckrollotaster_betaetigt 3;
BA_ "GenSigSwitchedByIgnition" SG_ 975 HBFS_Heckrollotaster_betaetigt 0;
BA_ "GenSigSendType" SG_ 975 HBFS_Lock_Taster 3;
BA_ "GenSigSwitchedByIgnition" SG_ 975 HBFS_Lock_Taster 0;
BA_ "GenSigSendType" SG_ 975 HBFS_Lock_Taster_inv 3;
BA_ "GenSigStartValue" SG_ 975 HBFS_Lock_Taster_inv 1;
BA_ "GenSigSwitchedByIgnition" SG_ 975 HBFS_Lock_Taster_inv 0;
BA_ "GenSigSendType" SG_ 975 HBFS_MRollo_Schalter 3;
BA_ "GenSigStartValue" SG_ 975 HBFS_MRollo_Schalter 6;
BA_ "GenSigSwitchedByIgnition" SG_ 975 HBFS_MRollo_Schalter 0;
BA_ "Fehlerwert" SG_ 975 HBFS_MRollo_Schalter 7;
BA_ "GenSigSendType" SG_ 975 HBFS_Oben_Block_erw 3;
BA_ "GenSigSwitchedByIgnition" SG_ 975 HBFS_Oben_Block_erw 0;
BA_ "GenSigSendType" SG_ 975 HBFS_SAD_Schalter 3;
BA_ "GenSigSwitchedByIgnition" SG_ 975 HBFS_SAD_Schalter 0;
BA_ "Fehlerwert" SG_ 975 HBFS_SAD_Schalter 15;
BA_ "GenSigSendType" SG_ 975 HBFS_Seitenrollo_hoch 3;
BA_ "GenSigSwitchedByIgnition" SG_ 975 HBFS_Seitenrollo_hoch 0;
BA_ "GenSigSendType" SG_ 975 HBFS_Seitenrollo_tief 3;
BA_ "GenSigSwitchedByIgnition" SG_ 975 HBFS_Seitenrollo_tief 0;
BA_ "GenSigSendType" SG_ 975 HBFS_SK_betaetigt 3;
BA_ "GenSigSwitchedByIgnition" SG_ 975 HBFS_SK_betaetigt 0;
BA_ "GenSigSendType" SG_ 975 HBFS_Sperrklinke 3;
BA_ "GenSigSwitchedByIgnition" SG_ 975 HBFS_Sperrklinke 0;
BA_ "GenSigSendType" SG_ 975 HBFS_Status_eTAG 0;
BA_ "GenSigSwitchedByIgnition" SG_ 975 HBFS_Status_eTAG 0;
BA_ "Fehlerwert" SG_ 975 HBFS_Status_eTAG 3;
BA_ "GenSigSendType" SG_ 975 HBFS_Status_KiSi 3;
BA_ "GenSigSwitchedByIgnition" SG_ 975 HBFS_Status_KiSi 0;
BA_ "GenSigSendType" SG_ 975 HBFS_Status_KiSi_inv 3;
BA_ "GenSigStartValue" SG_ 975 HBFS_Status_KiSi_inv 1;
BA_ "GenSigSwitchedByIgnition" SG_ 975 HBFS_Status_KiSi_inv 0;
BA_ "GenSigSendType" SG_ 975 HBFS_TAG_betaetigt 3;
BA_ "GenSigSwitchedByIgnition" SG_ 975 HBFS_TAG_betaetigt 0;
BA_ "GenSigSendType" SG_ 975 HBFS_TIG_betaetigt 3;
BA_ "GenSigSwitchedByIgnition" SG_ 975 HBFS_TIG_betaetigt 0;
BA_ "GenSigSendType" SG_ 975 HBFS_TIG_betaetigt_oeffnen 3;
BA_ "GenSigSwitchedByIgnition" SG_ 975 HBFS_TIG_betaetigt_oeffnen 0;
BA_ "GenSigSendType" SG_ 975 HBFS_TIG_betaetigt_schliessen 3;
BA_ "GenSigSwitchedByIgnition" SG_ 975 HBFS_TIG_betaetigt_schliessen 0;
BA_ "GenSigSendType" SG_ 975 HBFS_Tuer_geoeffnet 3;
BA_ "GenSigSwitchedByIgnition" SG_ 975 HBFS_Tuer_geoeffnet 0;
BA_ "GenSigSendType" SG_ 975 HBFS_Tuer_Status 3;
BA_ "GenSigSwitchedByIgnition" SG_ 975 HBFS_Tuer_Status 0;
BA_ "Fehlerwert" SG_ 975 HBFS_Tuer_Status 3;
BA_ "GenSigSendType" SG_ 975 HBFS_Tuer_Status_QBit 3;
BA_ "GenSigSwitchedByIgnition" SG_ 975 HBFS_Tuer_Status_QBit 0;
BA_ "GenSigSendType" SG_ 975 HBFS_Tueroeffnen_Warnung 3;
BA_ "GenSigSwitchedByIgnition" SG_ 975 HBFS_Tueroeffnen_Warnung 0;
BA_ "GenSigSendType" SG_ 975 HBFS_Tuerschloss_defekt 0;
BA_ "GenSigSwitchedByIgnition" SG_ 975 HBFS_Tuerschloss_defekt 0;
BA_ "GenSigSendType" SG_ 975 HBFS_UEKB_aktiviert 3;
BA_ "GenSigSwitchedByIgnition" SG_ 975 HBFS_UEKB_aktiviert 0;
BA_ "GenSigSendType" SG_ 975 HBFS_Unlock_Taster 3;
BA_ "GenSigSwitchedByIgnition" SG_ 975 HBFS_Unlock_Taster 0;
BA_ "GenSigSendType" SG_ 975 HBFS_Unten_Block_erw 3;
BA_ "GenSigSwitchedByIgnition" SG_ 975 HBFS_Unten_Block_erw 0;
BA_ "GenSigSendType" SG_ 975 HBFS_verriegelt 3;
BA_ "GenSigSwitchedByIgnition" SG_ 975 HBFS_verriegelt 0;
BA_ "GenSigSendType" SG_ 975 HBFS_Vorraste_betaetigt 3;
BA_ "GenSigSwitchedByIgnition" SG_ 975 HBFS_Vorraste_betaetigt 0;
BA_ "GenSigSendType" SG_ 975 HBFS_Zuziehhilfe_aktiv 3;
BA_ "GenSigSwitchedByIgnition" SG_ 975 HBFS_Zuziehhilfe_aktiv 0;
BA_ "GenSigSendType" SG_ 975 MTHBFS_M_Taste 3;
BA_ "GenSigSwitchedByIgnition" SG_ 975 MTHBFS_M_Taste 0;
BA_ "GenSigSendType" SG_ 975 MTHBFS_Pos1 3;
BA_ "GenSigSwitchedByIgnition" SG_ 975 MTHBFS_Pos1 0;
BA_ "GenSigSendType" SG_ 975 MTHBFS_Pos2 3;
BA_ "GenSigSwitchedByIgnition" SG_ 975 MTHBFS_Pos2 0;
BA_ "GenSigSendType" SG_ 975 MTHBFS_Pos3 3;
BA_ "GenSigSwitchedByIgnition" SG_ 975 MTHBFS_Pos3 0;
BA_ "GenSigSendType" SG_ 975 SSR_HBFS_Pos_Unten 0;
BA_ "GenSigSwitchedByIgnition" SG_ 975 SSR_HBFS_Pos_Unten 0;
BA_ "GenSigSendType" SG_ 974 ASW_Warnung_aktiv_HFS 3;
BA_ "GenSigSwitchedByIgnition" SG_ 974 ASW_Warnung_aktiv_HFS 0;
BA_ "GenSigSendType" SG_ 974 HFS_FH_Bew_hoch 3;
BA_ "GenSigSwitchedByIgnition" SG_ 974 HFS_FH_Bew_hoch 0;
BA_ "GenSigSendType" SG_ 974 HFS_FH_Bew_tief 3;
BA_ "GenSigSwitchedByIgnition" SG_ 974 HFS_FH_Bew_tief 0;
BA_ "GenSigSendType" SG_ 974 HFS_FH_Block 3;
BA_ "GenSigSwitchedByIgnition" SG_ 974 HFS_FH_Block 0;
BA_ "GenSigSendType" SG_ 974 HFS_FH_Fang 3;
BA_ "GenSigSwitchedByIgnition" SG_ 974 HFS_FH_Fang 0;
BA_ "GenSigSendType" SG_ 974 HFS_FH_normiert 3;
BA_ "GenSigSwitchedByIgnition" SG_ 974 HFS_FH_normiert 0;
BA_ "GenSigSendType" SG_ 974 HFS_FH_Oeffnung 3;
BA_ "GenSigSwitchedByIgnition" SG_ 974 HFS_FH_Oeffnung 0;
BA_ "GenSigSendType" SG_ 974 HFS_FH_S_AutoHoch 3;
BA_ "GenSigSwitchedByIgnition" SG_ 974 HFS_FH_S_AutoHoch 0;
BA_ "GenSigSendType" SG_ 974 HFS_FH_S_AutoTief 3;
BA_ "GenSigSwitchedByIgnition" SG_ 974 HFS_FH_S_AutoTief 0;
BA_ "GenSigSendType" SG_ 974 HFS_FH_S_HBFS_AutoHoch 3;
BA_ "GenSigSwitchedByIgnition" SG_ 974 HFS_FH_S_HBFS_AutoHoch 0;
BA_ "GenSigSendType" SG_ 974 HFS_FH_S_HBFS_AutoTief 3;
BA_ "GenSigSwitchedByIgnition" SG_ 974 HFS_FH_S_HBFS_AutoTief 0;
BA_ "GenSigSendType" SG_ 974 HFS_FH_S_HBFS_ManHoch 3;
BA_ "GenSigSwitchedByIgnition" SG_ 974 HFS_FH_S_HBFS_ManHoch 0;
BA_ "GenSigSendType" SG_ 974 HFS_FH_S_HBFS_ManTief 3;
BA_ "GenSigSwitchedByIgnition" SG_ 974 HFS_FH_S_HBFS_ManTief 0;
BA_ "GenSigSendType" SG_ 974 HFS_FH_S_ManHoch 3;
BA_ "GenSigSwitchedByIgnition" SG_ 974 HFS_FH_S_ManHoch 0;
BA_ "GenSigSendType" SG_ 974 HFS_FH_S_ManTief 3;
BA_ "GenSigSwitchedByIgnition" SG_ 974 HFS_FH_S_ManTief 0;
BA_ "GenSigSendType" SG_ 974 HFS_FH_Thermo 3;
BA_ "GenSigSwitchedByIgnition" SG_ 974 HFS_FH_Thermo 0;
BA_ "GenSigSendType" SG_ 974 HFS_gesafet 3;
BA_ "GenSigSwitchedByIgnition" SG_ 974 HFS_gesafet 0;
BA_ "GenSigSendType" SG_ 974 HFS_Heckrollotaster_betaetigt 3;
BA_ "GenSigSwitchedByIgnition" SG_ 974 HFS_Heckrollotaster_betaetigt 0;
BA_ "GenSigSendType" SG_ 974 HFS_Lock_Taster 3;
BA_ "GenSigSwitchedByIgnition" SG_ 974 HFS_Lock_Taster 0;
BA_ "GenSigSendType" SG_ 974 HFS_Lock_Taster_inv 3;
BA_ "GenSigSwitchedByIgnition" SG_ 974 HFS_Lock_Taster_inv 0;
BA_ "GenSigSendType" SG_ 974 HFS_MRollo_Schalter 3;
BA_ "GenSigStartValue" SG_ 974 HFS_MRollo_Schalter 6;
BA_ "GenSigSwitchedByIgnition" SG_ 974 HFS_MRollo_Schalter 0;
BA_ "Fehlerwert" SG_ 974 HFS_MRollo_Schalter 7;
BA_ "GenSigSendType" SG_ 974 HFS_Oben_Block_erw 3;
BA_ "GenSigSwitchedByIgnition" SG_ 974 HFS_Oben_Block_erw 0;
BA_ "GenSigSendType" SG_ 974 HFS_SAD_Schalter 3;
BA_ "GenSigStartValue" SG_ 974 HFS_SAD_Schalter 14;
BA_ "GenSigSwitchedByIgnition" SG_ 974 HFS_SAD_Schalter 0;
BA_ "Fehlerwert" SG_ 974 HFS_SAD_Schalter 15;
BA_ "GenSigSendType" SG_ 974 HFS_Seitenrollo_hoch 3;
BA_ "GenSigSwitchedByIgnition" SG_ 974 HFS_Seitenrollo_hoch 0;
BA_ "GenSigSendType" SG_ 974 HFS_Seitenrollo_tief 3;
BA_ "GenSigSwitchedByIgnition" SG_ 974 HFS_Seitenrollo_tief 0;
BA_ "GenSigSendType" SG_ 974 HFS_SK_betaetigt 3;
BA_ "GenSigSwitchedByIgnition" SG_ 974 HFS_SK_betaetigt 0;
BA_ "GenSigSendType" SG_ 974 HFS_Sperrklinke 3;
BA_ "GenSigSwitchedByIgnition" SG_ 974 HFS_Sperrklinke 0;
BA_ "GenSigSendType" SG_ 974 HFS_Status_eTAG 0;
BA_ "GenSigSwitchedByIgnition" SG_ 974 HFS_Status_eTAG 0;
BA_ "Fehlerwert" SG_ 974 HFS_Status_eTAG 3;
BA_ "GenSigSendType" SG_ 974 HFS_Status_KiSi 3;
BA_ "GenSigSwitchedByIgnition" SG_ 974 HFS_Status_KiSi 0;
BA_ "GenSigSendType" SG_ 974 HFS_TAG_betaetigt 3;
BA_ "GenSigSwitchedByIgnition" SG_ 974 HFS_TAG_betaetigt 0;
BA_ "GenSigSendType" SG_ 974 HFS_TCR_Mode_aktiv 3;
BA_ "GenSigSwitchedByIgnition" SG_ 974 HFS_TCR_Mode_aktiv 0;
BA_ "GenSigSendType" SG_ 974 HFS_TIG_betaetigt 3;
BA_ "GenSigSwitchedByIgnition" SG_ 974 HFS_TIG_betaetigt 0;
BA_ "GenSigSendType" SG_ 974 HFS_TIG_betaetigt_oeffnen 3;
BA_ "GenSigSwitchedByIgnition" SG_ 974 HFS_TIG_betaetigt_oeffnen 0;
BA_ "GenSigSendType" SG_ 974 HFS_TIG_betaetigt_schliessen 3;
BA_ "GenSigSwitchedByIgnition" SG_ 974 HFS_TIG_betaetigt_schliessen 0;
BA_ "GenSigSendType" SG_ 974 HFS_Tuer_geoeffnet 3;
BA_ "GenSigSwitchedByIgnition" SG_ 974 HFS_Tuer_geoeffnet 0;
BA_ "GenSigSendType" SG_ 974 HFS_Tuer_Status 3;
BA_ "GenSigSwitchedByIgnition" SG_ 974 HFS_Tuer_Status 0;
BA_ "Fehlerwert" SG_ 974 HFS_Tuer_Status 3;
BA_ "GenSigSendType" SG_ 974 HFS_Tuer_Status_QBit 0;
BA_ "GenSigSwitchedByIgnition" SG_ 974 HFS_Tuer_Status_QBit 0;
BA_ "GenSigSendType" SG_ 974 HFS_Tueroeffnen_Warnung 3;
BA_ "GenSigSwitchedByIgnition" SG_ 974 HFS_Tueroeffnen_Warnung 0;
BA_ "GenSigSendType" SG_ 974 HFS_Tuerschloss_defekt 0;
BA_ "GenSigSwitchedByIgnition" SG_ 974 HFS_Tuerschloss_defekt 0;
BA_ "GenSigSendType" SG_ 974 HFS_UEKB_aktiviert 3;
BA_ "GenSigSwitchedByIgnition" SG_ 974 HFS_UEKB_aktiviert 0;
BA_ "GenSigSendType" SG_ 974 HFS_Unlock_Taster 3;
BA_ "GenSigSwitchedByIgnition" SG_ 974 HFS_Unlock_Taster 0;
BA_ "GenSigSendType" SG_ 974 HFS_Unten_Block_erw 3;
BA_ "GenSigSwitchedByIgnition" SG_ 974 HFS_Unten_Block_erw 0;
BA_ "GenSigSendType" SG_ 974 HFS_verriegelt 3;
BA_ "GenSigSwitchedByIgnition" SG_ 974 HFS_verriegelt 0;
BA_ "GenSigSendType" SG_ 974 HFS_Vorraste_betaetigt 3;
BA_ "GenSigSwitchedByIgnition" SG_ 974 HFS_Vorraste_betaetigt 0;
BA_ "GenSigSendType" SG_ 974 HFS_Zuziehhilfe_aktiv 3;
BA_ "GenSigSwitchedByIgnition" SG_ 974 HFS_Zuziehhilfe_aktiv 0;
BA_ "GenSigSendType" SG_ 974 MTHFS_M_Taste 3;
BA_ "GenSigSwitchedByIgnition" SG_ 974 MTHFS_M_Taste 0;
BA_ "GenSigSendType" SG_ 974 MTHFS_Pos1 3;
BA_ "GenSigSwitchedByIgnition" SG_ 974 MTHFS_Pos1 0;
BA_ "GenSigSendType" SG_ 974 MTHFS_Pos2 3;
BA_ "GenSigSwitchedByIgnition" SG_ 974 MTHFS_Pos2 0;
BA_ "GenSigSendType" SG_ 974 MTHFS_Pos3 3;
BA_ "GenSigSwitchedByIgnition" SG_ 974 MTHFS_Pos3 0;
BA_ "GenSigSendType" SG_ 974 SSR_HFS_Pos_Unten 0;
BA_ "GenSigSwitchedByIgnition" SG_ 974 SSR_HFS_Pos_Unten 0;
BA_ "GenSigSendType" SG_ 1718 UH_DLS 0;
BA_ "GenSigSwitchedByIgnition" SG_ 1718 UH_DLS 0;
BA_ "GenSigSendType" SG_ 1718 UH_Jahr 0;
BA_ "GenSigSwitchedByIgnition" SG_ 1718 UH_Jahr 0;
BA_ "GenSigSendType" SG_ 1718 UH_Minute 0;
BA_ "GenSigSwitchedByIgnition" SG_ 1718 UH_Minute 0;
BA_ "GenSigSendType" SG_ 1718 UH_Monat 0;
BA_ "GenSigSwitchedByIgnition" SG_ 1718 UH_Monat 0;
BA_ "Fehlerwert" SG_ 1718 UH_Monat 15;
BA_ "GenSigSendType" SG_ 1718 UH_Sekunde 0;
BA_ "GenSigSwitchedByIgnition" SG_ 1718 UH_Sekunde 0;
BA_ "GenSigSendType" SG_ 1718 UH_Stunde 0;
BA_ "GenSigSwitchedByIgnition" SG_ 1718 UH_Stunde 0;
BA_ "GenSigSendType" SG_ 1718 UH_Tag 0;
BA_ "GenSigSwitchedByIgnition" SG_ 1718 UH_Tag 0;
BA_ "GenSigSendType" SG_ 1718 UH_Typ 0;
BA_ "GenSigFuncType" SG_ 1718 UH_Typ 8;
BA_ "GenSigSwitchedByIgnition" SG_ 1718 UH_Typ 0;
BA_ "GenSigSendType" SG_ 2463978710 OPS_ComfortReadyStatus 4;
BA_ "GenSigSwitchedByIgnition" SG_ 2463978710 OPS_ComfortReadyStatus 0;
BA_ "Fehlerwert" SG_ 2463978710 OPS_ComfortReadyStatus 3;
BA_ "GenSigSendType" SG_ 2463978710 OPS_DriverPresenceStatus 4;
BA_ "GenSigSwitchedByIgnition" SG_ 2463978710 OPS_DriverPresenceStatus 0;
BA_ "Fehlerwert" SG_ 2463978710 OPS_DriverPresenceStatus 15;
BA_ "GenSigSendType" SG_ 2463978710 OPS_OccupantPresenceStatus 4;
BA_ "GenSigSwitchedByIgnition" SG_ 2463978710 OPS_OccupantPresenceStatus 0;
BA_ "Fehlerwert" SG_ 2463978710 OPS_OccupantPresenceStatus 7;
BA_ "GenSigSendType" SG_ 2463978710 OPS_QBit_DriverPresence 4;
BA_ "GenSigStartValue" SG_ 2463978710 OPS_QBit_DriverPresence 1;
BA_ "GenSigSwitchedByIgnition" SG_ 2463978710 OPS_QBit_DriverPresence 0;
BA_ "GenSigSendType" SG_ 2463978710 OPS_SafeDriverPresence_available 4;
BA_ "GenSigSwitchedByIgnition" SG_ 2463978710 OPS_SafeDriverPresence_available 0;
BA_ "GenSigSendType" SG_ 2463978710 OPS_SafeDriverPresenceStatus 4;
BA_ "GenSigSwitchedByIgnition" SG_ 2463978710 OPS_SafeDriverPresenceStatus 0;
BA_ "Fehlerwert" SG_ 2463978710 OPS_SafeDriverPresenceStatus 3;
BA_ "GenSigSendType" SG_ 2463978710 UserStateServer_01_BZ 0;
BA_ "GenSigFuncType" SG_ 2463978710 UserStateServer_01_BZ 1;
BA_ "GenSigSwitchedByIgnition" SG_ 2463978710 UserStateServer_01_BZ 0;
BA_ "GenSigSendType" SG_ 2463978710 UserStateServer_01_CRC 0;
BA_ "GenSigFuncType" SG_ 2463978710 UserStateServer_01_CRC 2;
BA_ "GenSigSwitchedByIgnition" SG_ 2463978710 UserStateServer_01_CRC 0;
BA_ "GenSigSendType" SG_ 995 VD_SpannungsAnf 3;
BA_ "GenSigSwitchedByIgnition" SG_ 995 VD_SpannungsAnf 0;
BA_ "GenSigActiveRepetitions" SG_ 995 VS_BFS_AutoHoch 5;
BA_ "GenSigSendType" SG_ 995 VS_BFS_AutoHoch 4;
BA_ "GenSigSwitchedByIgnition" SG_ 995 VS_BFS_AutoHoch 0;
BA_ "GenSigActiveRepetitions" SG_ 995 VS_BFS_AutoTief 5;
BA_ "GenSigSendType" SG_ 995 VS_BFS_AutoTief 4;
BA_ "GenSigSwitchedByIgnition" SG_ 995 VS_BFS_AutoTief 0;
BA_ "GenSigActiveRepetitions" SG_ 995 VS_BFS_ManHoch 5;
BA_ "GenSigSendType" SG_ 995 VS_BFS_ManHoch 4;
BA_ "GenSigSwitchedByIgnition" SG_ 995 VS_BFS_ManHoch 0;
BA_ "GenSigActiveRepetitions" SG_ 995 VS_BFS_ManTief 5;
BA_ "GenSigSendType" SG_ 995 VS_BFS_ManTief 4;
BA_ "GenSigSwitchedByIgnition" SG_ 995 VS_BFS_ManTief 0;
BA_ "GenSigSendType" SG_ 995 VS_Buzzer 3;
BA_ "GenSigSwitchedByIgnition" SG_ 995 VS_Buzzer 0;
BA_ "GenSigSendType" SG_ 995 VS_FH_BT_Langhub 3;
BA_ "GenSigSwitchedByIgnition" SG_ 995 VS_FH_BT_Langhub 0;
BA_ "GenSigSendType" SG_ 995 VS_FH_FT_Langhub 3;
BA_ "GenSigSwitchedByIgnition" SG_ 995 VS_FH_FT_Langhub 0;
BA_ "GenSigSendType" SG_ 995 VS_FH_HBFS_Langhub 3;
BA_ "GenSigSwitchedByIgnition" SG_ 995 VS_FH_HBFS_Langhub 0;
BA_ "GenSigSendType" SG_ 995 VS_FH_HFS_Langhub 3;
BA_ "GenSigSwitchedByIgnition" SG_ 995 VS_FH_HFS_Langhub 0;
BA_ "GenSigActiveRepetitions" SG_ 995 VS_FS_AutoHoch 5;
BA_ "GenSigSendType" SG_ 995 VS_FS_AutoHoch 4;
BA_ "GenSigSwitchedByIgnition" SG_ 995 VS_FS_AutoHoch 0;
BA_ "GenSigActiveRepetitions" SG_ 995 VS_FS_AutoTief 5;
BA_ "GenSigSendType" SG_ 995 VS_FS_AutoTief 4;
BA_ "GenSigSwitchedByIgnition" SG_ 995 VS_FS_AutoTief 0;
BA_ "GenSigActiveRepetitions" SG_ 995 VS_FS_ManHoch 5;
BA_ "GenSigSendType" SG_ 995 VS_FS_ManHoch 4;
BA_ "GenSigSwitchedByIgnition" SG_ 995 VS_FS_ManHoch 0;
BA_ "GenSigActiveRepetitions" SG_ 995 VS_FS_ManTief 5;
BA_ "GenSigSendType" SG_ 995 VS_FS_ManTief 4;
BA_ "GenSigSwitchedByIgnition" SG_ 995 VS_FS_ManTief 0;
BA_ "GenSigSendType" SG_ 995 VS_Hardtop 3;
BA_ "GenSigSwitchedByIgnition" SG_ 995 VS_Hardtop 0;
BA_ "GenSigActiveRepetitions" SG_ 995 VS_HBFS_AutoHoch 5;
BA_ "GenSigSendType" SG_ 995 VS_HBFS_AutoHoch 4;
BA_ "GenSigSwitchedByIgnition" SG_ 995 VS_HBFS_AutoHoch 0;
BA_ "GenSigActiveRepetitions" SG_ 995 VS_HBFS_AutoTief 5;
BA_ "GenSigSendType" SG_ 995 VS_HBFS_AutoTief 4;
BA_ "GenSigSwitchedByIgnition" SG_ 995 VS_HBFS_AutoTief 0;
BA_ "GenSigActiveRepetitions" SG_ 995 VS_HBFS_ManHoch 5;
BA_ "GenSigSendType" SG_ 995 VS_HBFS_ManHoch 4;
BA_ "GenSigSwitchedByIgnition" SG_ 995 VS_HBFS_ManHoch 0;
BA_ "GenSigActiveRepetitions" SG_ 995 VS_HBFS_ManTief 5;
BA_ "GenSigSendType" SG_ 995 VS_HBFS_ManTief 4;
BA_ "GenSigSwitchedByIgnition" SG_ 995 VS_HBFS_ManTief 0;
BA_ "GenSigSendType" SG_ 995 VS_HD_sperren 3;
BA_ "GenSigSwitchedByIgnition" SG_ 995 VS_HD_sperren 0;
BA_ "GenSigSendType" SG_ 995 VS_Heckschloss_auf 3;
BA_ "GenSigSwitchedByIgnition" SG_ 995 VS_Heckschloss_auf 0;
BA_ "GenSigActiveRepetitions" SG_ 995 VS_HFS_AutoHoch 5;
BA_ "GenSigSendType" SG_ 995 VS_HFS_AutoHoch 4;
BA_ "GenSigSwitchedByIgnition" SG_ 995 VS_HFS_AutoHoch 0;
BA_ "GenSigActiveRepetitions" SG_ 995 VS_HFS_AutoTief 5;
BA_ "GenSigSendType" SG_ 995 VS_HFS_AutoTief 4;
BA_ "GenSigSwitchedByIgnition" SG_ 995 VS_HFS_AutoTief 0;
BA_ "GenSigActiveRepetitions" SG_ 995 VS_HFS_ManHoch 5;
BA_ "GenSigSendType" SG_ 995 VS_HFS_ManHoch 4;
BA_ "GenSigSwitchedByIgnition" SG_ 995 VS_HFS_ManHoch 0;
BA_ "GenSigActiveRepetitions" SG_ 995 VS_HFS_ManTief 5;
BA_ "GenSigSendType" SG_ 995 VS_HFS_ManTief 4;
BA_ "GenSigSwitchedByIgnition" SG_ 995 VS_HFS_ManTief 0;
BA_ "GenSigSendType" SG_ 995 VS_HHS_enable 3;
BA_ "GenSigSwitchedByIgnition" SG_ 995 VS_HHS_enable 0;
BA_ "GenSigSendType" SG_ 995 VS_Lampe_Blk 3;
BA_ "GenSigSwitchedByIgnition" SG_ 995 VS_Lampe_Blk 0;
BA_ "GenSigSendType" SG_ 995 VS_StartStopp_Info 3;
BA_ "GenSigSwitchedByIgnition" SG_ 995 VS_StartStopp_Info 0;
BA_ "Fehlerwert" SG_ 995 VS_StartStopp_Info 3;
BA_ "GenSigSendType" SG_ 995 VS_VD_Bew_auf 3;
BA_ "GenSigSwitchedByIgnition" SG_ 995 VS_VD_Bew_auf 0;
BA_ "GenSigSendType" SG_ 995 VS_VD_Bew_zu 3;
BA_ "GenSigSwitchedByIgnition" SG_ 995 VS_VD_Bew_zu 0;
BA_ "GenSigSendType" SG_ 995 VS_VD_entriegelt 3;
BA_ "GenSigSwitchedByIgnition" SG_ 995 VS_VD_entriegelt 0;
BA_ "GenSigSendType" SG_ 995 VS_VD_Fehler 3;
BA_ "GenSigSwitchedByIgnition" SG_ 995 VS_VD_Fehler 0;
BA_ "GenSigSendType" SG_ 995 VS_VD_offen_ver 3;
BA_ "GenSigSwitchedByIgnition" SG_ 995 VS_VD_offen_ver 0;
BA_ "GenSigSendType" SG_ 995 VS_VD_zu_ver 3;
BA_ "GenSigSwitchedByIgnition" SG_ 995 VS_VD_zu_ver 0;
BA_ "GenSigSendType" SG_ 995 VS_VD_Zwischenposition 3;
BA_ "GenSigSwitchedByIgnition" SG_ 995 VS_VD_Zwischenposition 0;
BA_ "GenSigSendType" SG_ 995 VS_VDKD_auf 3;
BA_ "GenSigSwitchedByIgnition" SG_ 995 VS_VDKD_auf 0;
BA_ "GenSigSendType" SG_ 995 VS_Verdeck_Anf 3;
BA_ "GenSigSwitchedByIgnition" SG_ 995 VS_Verdeck_Anf 0;
BA_ "GenSigSendType" SG_ 995 VS_Windschott_nicht_abgelegt 3;
BA_ "GenSigSwitchedByIgnition" SG_ 995 VS_Windschott_nicht_abgelegt 0;
BA_ "GenSigSendType" SG_ 995 VSG_Meldungen 3;
BA_ "GenSigSwitchedByIgnition" SG_ 995 VSG_Meldungen 0;
BA_ "GenSigSwitchedByIgnition" SG_ 1716 KS_Geheimnis_1 0;
BA_ "GenSigSwitchedByIgnition" SG_ 1716 KS_Geheimnis_2 0;
BA_ "GenSigSwitchedByIgnition" SG_ 1716 KS_Geheimnis_3 0;
BA_ "GenSigSwitchedByIgnition" SG_ 1716 KS_Geheimnis_4 0;
BA_ "GenSigSendType" SG_ 1716 VIN_01_MUX 0;
BA_ "GenSigSwitchedByIgnition" SG_ 1716 VIN_01_MUX 0;
BA_ "GenSigStartValue" SG_ 1716 VIN_1 45;
BA_ "GenSigSwitchedByIgnition" SG_ 1716 VIN_1 0;
BA_ "GenSigStartValue" SG_ 1716 VIN_10 45;
BA_ "GenSigSwitchedByIgnition" SG_ 1716 VIN_10 0;
BA_ "GenSigStartValue" SG_ 1716 VIN_11 45;
BA_ "GenSigSwitchedByIgnition" SG_ 1716 VIN_11 0;
BA_ "GenSigStartValue" SG_ 1716 VIN_12 45;
BA_ "GenSigSwitchedByIgnition" SG_ 1716 VIN_12 0;
BA_ "GenSigStartValue" SG_ 1716 VIN_13 45;
BA_ "GenSigSwitchedByIgnition" SG_ 1716 VIN_13 0;
BA_ "GenSigStartValue" SG_ 1716 VIN_14 45;
BA_ "GenSigSwitchedByIgnition" SG_ 1716 VIN_14 0;
BA_ "GenSigStartValue" SG_ 1716 VIN_15 45;
BA_ "GenSigSwitchedByIgnition" SG_ 1716 VIN_15 0;
BA_ "GenSigStartValue" SG_ 1716 VIN_16 45;
BA_ "GenSigSwitchedByIgnition" SG_ 1716 VIN_16 0;
BA_ "GenSigStartValue" SG_ 1716 VIN_17 45;
BA_ "GenSigSwitchedByIgnition" SG_ 1716 VIN_17 0;
BA_ "GenSigStartValue" SG_ 1716 VIN_2 45;
BA_ "GenSigSwitchedByIgnition" SG_ 1716 VIN_2 0;
BA_ "GenSigStartValue" SG_ 1716 VIN_3 45;
BA_ "GenSigSwitchedByIgnition" SG_ 1716 VIN_3 0;
BA_ "GenSigStartValue" SG_ 1716 VIN_4 45;
BA_ "GenSigSwitchedByIgnition" SG_ 1716 VIN_4 0;
BA_ "GenSigStartValue" SG_ 1716 VIN_5 45;
BA_ "GenSigSwitchedByIgnition" SG_ 1716 VIN_5 0;
BA_ "GenSigStartValue" SG_ 1716 VIN_6 45;
BA_ "GenSigSwitchedByIgnition" SG_ 1716 VIN_6 0;
BA_ "GenSigStartValue" SG_ 1716 VIN_7 45;
BA_ "GenSigSwitchedByIgnition" SG_ 1716 VIN_7 0;
BA_ "GenSigStartValue" SG_ 1716 VIN_8 45;
BA_ "GenSigSwitchedByIgnition" SG_ 1716 VIN_8 0;
BA_ "GenSigStartValue" SG_ 1716 VIN_9 45;
BA_ "GenSigSwitchedByIgnition" SG_ 1716 VIN_9 0;
BA_ "GenSigSendType" SG_ 916 GE_Sollgang 4;
BA_ "GenSigSwitchedByIgnition" SG_ 916 GE_Sollgang 0;
BA_ "GenSigSendType" SG_ 916 GE_Stoppverbot_Anz_01 0;
BA_ "GenSigSwitchedByIgnition" SG_ 916 GE_Stoppverbot_Anz_01 0;
BA_ "GenSigSendType" SG_ 916 GE_Stoppverbot_Anz_02 0;
BA_ "GenSigSwitchedByIgnition" SG_ 916 GE_Stoppverbot_Anz_02 0;
BA_ "GenSigSendType" SG_ 916 GE_Stoppverbot_Anz_03 0;
BA_ "GenSigSwitchedByIgnition" SG_ 916 GE_Stoppverbot_Anz_03 0;
BA_ "GenSigSendType" SG_ 916 GE_Stoppverbot_Anz_04 0;
BA_ "GenSigSwitchedByIgnition" SG_ 916 GE_Stoppverbot_Anz_04 0;
BA_ "GenSigSendType" SG_ 916 GE_Stoppverbot_Anz_05 0;
BA_ "GenSigSwitchedByIgnition" SG_ 916 GE_Stoppverbot_Anz_05 0;
BA_ "GenSigSendType" SG_ 916 GE_Stoppverbot_Anz_06 0;
BA_ "GenSigSwitchedByIgnition" SG_ 916 GE_Stoppverbot_Anz_06 0;
BA_ "GenSigSendType" SG_ 916 GE_Stoppverbot_Anz_07 0;
BA_ "GenSigSwitchedByIgnition" SG_ 916 GE_Stoppverbot_Anz_07 0;
BA_ "GenSigSendType" SG_ 916 GE_Stoppverbot_Anz_Std 0;
BA_ "GenSigSwitchedByIgnition" SG_ 916 GE_Stoppverbot_Anz_Std 0;
BA_ "GenSigSendType" SG_ 916 GE_Tipschaltempf_verfuegbar 0;
BA_ "GenSigFuncType" SG_ 916 GE_Tipschaltempf_verfuegbar 8;
BA_ "GenSigSwitchedByIgnition" SG_ 916 GE_Tipschaltempf_verfuegbar 0;
BA_ "GenSigSendType" SG_ 916 GE_Wiederstart_Anz_Std 0;
BA_ "GenSigSwitchedByIgnition" SG_ 916 GE_Wiederstart_Anz_Std 0;
BA_ "GenSigSendType" SG_ 916 WBA_03_BZ 0;
BA_ "GenSigFuncType" SG_ 916 WBA_03_BZ 1;
BA_ "GenSigSwitchedByIgnition" SG_ 916 WBA_03_BZ 0;
BA_ "GenSigSendType" SG_ 916 WBA_03_CRC 0;
BA_ "GenSigFuncType" SG_ 916 WBA_03_CRC 2;
BA_ "GenSigSwitchedByIgnition" SG_ 916 WBA_03_CRC 0;
BA_ "GenSigSendType" SG_ 916 WBA_Anforderung_Akustik 4;
BA_ "GenSigSwitchedByIgnition" SG_ 916 WBA_Anforderung_Akustik 0;
BA_ "GenSigSendType" SG_ 916 WBA_Blinken 3;
BA_ "GenSigSwitchedByIgnition" SG_ 916 WBA_Blinken 0;
BA_ "GenSigSendType" SG_ 916 WBA_eing_Gang_02 4;
BA_ "GenSigSwitchedByIgnition" SG_ 916 WBA_eing_Gang_02 0;
BA_ "GenSigSendType" SG_ 916 WBA_Fahrstufe_02 4;
BA_ "GenSigSwitchedByIgnition" SG_ 916 WBA_Fahrstufe_02 0;
BA_ "GenSigSendType" SG_ 916 WBA_GE_Texte 4;
BA_ "GenSigSwitchedByIgnition" SG_ 916 WBA_GE_Texte 0;
BA_ "GenSigSendType" SG_ 916 WBA_GE_Texte_02 0;
BA_ "GenSigSwitchedByIgnition" SG_ 916 WBA_GE_Texte_02 0;
BA_ "GenSigSendType" SG_ 916 WBA_GE_Warnung_02 4;
BA_ "GenSigSwitchedByIgnition" SG_ 916 WBA_GE_Warnung_02 0;
BA_ "GenSigSendType" SG_ 916 WBA_GE_Zusatzwarnungen 4;
BA_ "GenSigSwitchedByIgnition" SG_ 916 WBA_GE_Zusatzwarnungen 0;
BA_ "GenSigSendType" SG_ 916 WBA_Schaltschema_02 4;
BA_ "GenSigSwitchedByIgnition" SG_ 916 WBA_Schaltschema_02 0;
BA_ "GenSigSendType" SG_ 916 WBA_Schaltschema_Fahreraktion 4;
BA_ "GenSigSwitchedByIgnition" SG_ 916 WBA_Schaltschema_Fahreraktion 0;
BA_ "GenSigSendType" SG_ 916 WBA_Schaltschema_FS_inaktiv 4;
BA_ "GenSigSwitchedByIgnition" SG_ 916 WBA_Schaltschema_FS_inaktiv 0;
BA_ "GenSigSendType" SG_ 916 WBA_Schaltschema_FS_vorwaerts 4;
BA_ "GenSigSwitchedByIgnition" SG_ 916 WBA_Schaltschema_FS_vorwaerts 0;
BA_ "GenSigSendType" SG_ 916 WBA_Schaltschema_Tippgasse 4;
BA_ "GenSigSwitchedByIgnition" SG_ 916 WBA_Schaltschema_Tippgasse 0;
BA_ "GenSigSendType" SG_ 916 WBA_Segeln_aktiv 4;
BA_ "GenSigSwitchedByIgnition" SG_ 916 WBA_Segeln_aktiv 0;
BA_ "GenSigSendType" SG_ 916 WBA_Shiftlock_Lampe 4;
BA_ "GenSigSwitchedByIgnition" SG_ 916 WBA_Shiftlock_Lampe 0;
BA_ "GenSigSendType" SG_ 916 WBA_ZielFahrstufe 3;
BA_ "GenSigSwitchedByIgnition" SG_ 916 WBA_ZielFahrstufe 0;
BA_ "GenSigSendType" SG_ 1361 WFS_Betrieb_Lesespule 3;
BA_ "GenSigSwitchedByIgnition" SG_ 1361 WFS_Betrieb_Lesespule 0;
BA_ "GenSigSendType" SG_ 1361 WFS_ELV_authorisiert 3;
BA_ "GenSigSwitchedByIgnition" SG_ 1361 WFS_ELV_authorisiert 0;
BA_ "GenSigSendType" SG_ 1361 WFS_Fahrerhinweise 3;
BA_ "GenSigSwitchedByIgnition" SG_ 1361 WFS_Fahrerhinweise 0;
BA_ "GenSigSendType" SG_ 1361 WFS_ID_Geb_autorisiert 3;
BA_ "GenSigSwitchedByIgnition" SG_ 1361 WFS_ID_Geb_autorisiert 0;
BA_ "GenSigSendType" SG_ 1361 WFS_ID_Geb_autorisiert_in_Kl15 3;
BA_ "GenSigSwitchedByIgnition" SG_ 1361 WFS_ID_Geb_autorisiert_in_Kl15 0;
BA_ "GenSigSendType" SG_ 1361 WFS_ID_Geb_steckt 3;
BA_ "GenSigSwitchedByIgnition" SG_ 1361 WFS_ID_Geb_steckt 0;
BA_ "GenSigSendType" SG_ 1361 WFS_Klemmenfreigabe 3;
BA_ "GenSigSwitchedByIgnition" SG_ 1361 WFS_Klemmenfreigabe 0;
BA_ "GenSigSendType" SG_ 1361 WFS_Klemmenfreigabe_Signatur 3;
BA_ "GenSigSwitchedByIgnition" SG_ 1361 WFS_Klemmenfreigabe_Signatur 0;
BA_ "GenSigSendType" SG_ 1361 WFS_LF_Aktiv 3;
BA_ "GenSigSwitchedByIgnition" SG_ 1361 WFS_LF_Aktiv 0;
BA_ "GenSigSendType" SG_ 1361 WFS_LZ 3;
BA_ "GenSigSwitchedByIgnition" SG_ 1361 WFS_LZ 0;
BA_ "GenSigSendType" SG_ 1361 WFS_Parken_Status 3;
BA_ "GenSigSwitchedByIgnition" SG_ 1361 WFS_Parken_Status 0;
BA_ "GenSigSendType" SG_ 1361 WFS_Safe 3;
BA_ "GenSigSwitchedByIgnition" SG_ 1361 WFS_Safe 0;
BA_ "GenSigSendType" SG_ 1361 WFS_Schluessel_Fahrberecht 0;
BA_ "GenSigSwitchedByIgnition" SG_ 1361 WFS_Schluessel_Fahrberecht 0;
BA_ "GenSigSendType" SG_ 1361 WFS_Schluessel_Ist 3;
BA_ "GenSigSwitchedByIgnition" SG_ 1361 WFS_Schluessel_Ist 0;
BA_ "GenSigSendType" SG_ 1361 WFS_Schluessel_Soll 3;
BA_ "GenSigSwitchedByIgnition" SG_ 1361 WFS_Schluessel_Soll 0;
BA_ "GenSigSendType" SG_ 1361 WFS_Verbauinfo_ELV 3;
BA_ "GenSigSwitchedByIgnition" SG_ 1361 WFS_Verbauinfo_ELV 0;
BA_ "GenSigSendType" SG_ 1702 BCM1_SRA_aktiv 3;
BA_ "GenSigSwitchedByIgnition" SG_ 1702 BCM1_SRA_aktiv 0;
BA_ "GenSigActiveRepetitions" SG_ 1702 Heckwischer_Anforderung 3;
BA_ "GenSigSendType" SG_ 1702 Heckwischer_Anforderung 4;
BA_ "GenSigSwitchedByIgnition" SG_ 1702 Heckwischer_Anforderung 0;
BA_ "GenSigSendType" SG_ 1702 Waschen_vorne_aktiv 3;
BA_ "GenSigSwitchedByIgnition" SG_ 1702 Waschen_vorne_aktiv 0;
BA_ "GenSigSendType" SG_ 1702 Wischer1_Wischgeschwindigkeit 0;
BA_ "GenSigStartValue" SG_ 1702 Wischer1_Wischgeschwindigkeit 62;
BA_ "GenSigSwitchedByIgnition" SG_ 1702 Wischer1_Wischgeschwindigkeit 0;
BA_ "Fehlerwert" SG_ 1702 Wischer1_Wischgeschwindigkeit 63;
BA_ "GenSigSendType" SG_ 1702 Wischer_Anzeigetext 3;
BA_ "GenSigSwitchedByIgnition" SG_ 1702 Wischer_Anzeigetext 0;
BA_ "GenSigSendType" SG_ 1702 Wischer_vorne_aktiv 3;
BA_ "GenSigSwitchedByIgnition" SG_ 1702 Wischer_vorne_aktiv 0;
BA_ "GenSigSendType" SG_ 1702 Wischer_vorne_blockiert 3;
BA_ "GenSigSwitchedByIgnition" SG_ 1702 Wischer_vorne_blockiert 0;
BA_ "GenSigSendType" SG_ 1702 Wischer_vorne_defekt 3;
BA_ "GenSigSwitchedByIgnition" SG_ 1702 Wischer_vorne_defekt 0;
BA_ "GenSigSendType" SG_ 1702 Wischer_vorne_Normal 3;
BA_ "GenSigSwitchedByIgnition" SG_ 1702 Wischer_vorne_Normal 0;
BA_ "GenSigSendType" SG_ 1702 Wischer_vorne_Parklage 3;
BA_ "GenSigStartValue" SG_ 1702 Wischer_vorne_Parklage 1;
BA_ "GenSigSwitchedByIgnition" SG_ 1702 Wischer_vorne_Parklage 0;
BA_ "GenSigSendType" SG_ 1702 Wischer_vorne_Schnell 3;
BA_ "GenSigSwitchedByIgnition" SG_ 1702 Wischer_vorne_Schnell 0;
BA_ "GenSigSendType" SG_ 1702 Wischer_WH_PopUp_Anf 3;
BA_ "GenSigSwitchedByIgnition" SG_ 1702 Wischer_WH_PopUp_Anf 0;
BA_ "GenSigSendType" SG_ 1702 Wischer_WH_Typ 0;
BA_ "GenSigSwitchedByIgnition" SG_ 1702 Wischer_WH_Typ 0;
BA_ "GenSigSendType" SG_ 1702 WWSs_01_alt 0;
BA_ "GenSigStartValue" SG_ 1702 WWSs_01_alt 1;
BA_ "GenSigFuncType" SG_ 1702 WWSs_01_alt 5;
BA_ "GenSigSwitchedByIgnition" SG_ 1702 WWSs_01_alt 0;
BA_ "GenSigSendType" SG_ 2589283611 WLC1_aktive_Spule 3;
BA_ "GenSigSwitchedByIgnition" SG_ 2589283611 WLC1_aktive_Spule 0;
BA_ "GenSigSendType" SG_ 2589283611 WLC1_Charger_Effizienz 3;
BA_ "GenSigSwitchedByIgnition" SG_ 2589283611 WLC1_Charger_Effizienz 0;
BA_ "GenSigSendType" SG_ 2589283611 WLC1_Charger_laedt 3;
BA_ "GenSigSwitchedByIgnition" SG_ 2589283611 WLC1_Charger_laedt 0;
BA_ "GenSigSendType" SG_ 2589283611 WLC1_Fehler 3;
BA_ "GenSigSwitchedByIgnition" SG_ 2589283611 WLC1_Fehler 0;
BA_ "GenSigSendType" SG_ 2589283611 WLC1_Fremdobjekt_erkannt 3;
BA_ "GenSigSwitchedByIgnition" SG_ 2589283611 WLC1_Fremdobjekt_erkannt 0;
BA_ "GenSigSendType" SG_ 2589283611 WLC1_Leistungsklasse_Receiver 0;
BA_ "GenSigSwitchedByIgnition" SG_ 2589283611 WLC1_Leistungsklasse_Receiver 0;
BA_ "GenSigSendType" SG_ 2589283611 WLC1_Objekt_erkannt 3;
BA_ "GenSigSwitchedByIgnition" SG_ 2589283611 WLC1_Objekt_erkannt 0;
BA_ "GenSigSendType" SG_ 2589283611 WLC1_Receiver_erkannt 3;
BA_ "GenSigSwitchedByIgnition" SG_ 2589283611 WLC1_Receiver_erkannt 0;
BA_ "GenSigSendType" SG_ 2589283611 WLC1_Receiver_voll_geladen 3;
BA_ "GenSigSwitchedByIgnition" SG_ 2589283611 WLC1_Receiver_voll_geladen 0;
BA_ "GenSigSendType" SG_ 2589283611 WLC1_Temp_Leistungsteil_Charger 0;
BA_ "GenSigSwitchedByIgnition" SG_ 2589283611 WLC1_Temp_Leistungsteil_Charger 0;
BA_ "GenSigSendType" SG_ 2589283611 WLC1_Temp_Oberfaeche_Charger 0;
BA_ "GenSigSwitchedByIgnition" SG_ 2589283611 WLC1_Temp_Oberfaeche_Charger 0;
BA_ "GenSigSendType" SG_ 2589283611 WLC1_Temp_Receiver 0;
BA_ "GenSigSwitchedByIgnition" SG_ 2589283611 WLC1_Temp_Receiver 0;
BA_ "GenSigSendType" SG_ 2589283611 WLC1_verwendeter_Ladestandard 0;
BA_ "GenSigSwitchedByIgnition" SG_ 2589283611 WLC1_verwendeter_Ladestandard 0;
BA_ "GenSigSendType" SG_ 2527679836 WLC1_ChargingEfficiency 3;
BA_ "GenSigSendType" SG_ 2527679836 WLC1_ChargingStatus 3;
BA_ "GenSigSendType" SG_ 2527679836 WLC1_UsedChargingStandard 3;
BA_ "GenSigSendType" SG_ 2527679837 WLC2_ChargingEfficiency 3;
BA_ "GenSigSendType" SG_ 2527679837 WLC2_ChargingStatus 3;
BA_ "GenSigSendType" SG_ 2527679837 WLC2_UsedChargingStandard 3;
BA_ "GenSigSwitchedByIgnition" SG_ 2617059072 XCP_LSH_CRO_01_Data 0;
BA_ "GenSigSwitchedByIgnition" SG_ 2617059073 XCP_LSH_DTO_01_Data 0;
BA_ "GenSigSendType" SG_ 1140 DI_Screendesign 3;
BA_ "GenSigStartValue" SG_ 1140 DI_Screendesign 6;
BA_ "GenSigSwitchedByIgnition" SG_ 1140 DI_Screendesign 0;
BA_ "Fehlerwert" SG_ 1140 DI_Screendesign 7;
BA_ "GenSigSendType" SG_ 1140 MMI_State 3;
BA_ "GenSigSwitchedByIgnition" SG_ 1140 MMI_State 0;
BA_ "GenSigSendType" SG_ 1140 SI_ICAN 3;
BA_ "GenSigStartValue" SG_ 1140 SI_ICAN 1;
BA_ "GenSigSwitchedByIgnition" SG_ 1140 SI_ICAN 0;
BA_ "GenSigSendType" SG_ 1140 WLC1_Systemzustand 3;
BA_ "GenSigSwitchedByIgnition" SG_ 1140 WLC1_Systemzustand 0;
BA_ "GenSigSendType" SG_ 1140 WLC2_Systemzustand 3;
BA_ "GenSigSwitchedByIgnition" SG_ 1140 WLC2_Systemzustand 0;
BA_ "GenSigSendType" SG_ 1140 ZR_DimOffs_DU_1 3;
BA_ "GenSigStartValue" SG_ 1140 ZR_DimOffs_DU_1 14;
BA_ "GenSigSwitchedByIgnition" SG_ 1140 ZR_DimOffs_DU_1 0;
BA_ "GenSigSendType" SG_ 1140 ZR_DimOffs_DU_2 3;
BA_ "GenSigStartValue" SG_ 1140 ZR_DimOffs_DU_2 14;
BA_ "GenSigSwitchedByIgnition" SG_ 1140 ZR_DimOffs_DU_2 0;
BA_ "GenSigSendType" SG_ 1140 ZR_DimOffs_DU_3 3;
BA_ "GenSigStartValue" SG_ 1140 ZR_DimOffs_DU_3 14;
BA_ "GenSigSwitchedByIgnition" SG_ 1140 ZR_DimOffs_DU_3 0;
BA_ "GenSigSendType" SG_ 1140 ZR_DimOffs_DU_4 3;
BA_ "GenSigSendType" SG_ 1140 ZR_Lenkerposition 0;
BA_ "GenSigSwitchedByIgnition" SG_ 1140 ZR_Lenkerposition 0;
BA_ "GenSigSendType" SG_ 1140 ZR_State_DU_1 3;
BA_ "GenSigSwitchedByIgnition" SG_ 1140 ZR_State_DU_1 0;
BA_ "GenSigSendType" SG_ 1140 ZR_State_DU_2 3;
BA_ "GenSigSwitchedByIgnition" SG_ 1140 ZR_State_DU_2 0;
BA_ "GenSigSendType" SG_ 1140 ZR_State_DU_3 3;
BA_ "GenSigSwitchedByIgnition" SG_ 1140 ZR_State_DU_3 0;
BA_ "GenSigSendType" SG_ 1140 ZR_State_DU_4 3;
BA_ "GenSigSendType" SG_ 1140 ZR_WecktGesp 3;
BA_ "GenSigSwitchedByIgnition" SG_ 1140 ZR_WecktGesp 0;
BA_ "GenSigSendType" SG_ 2589283965 DFB_CILState_ADA 3;
BA_ "GenSigSwitchedByIgnition" SG_ 2589283965 DFB_CILState_ADA 0;
BA_ "GenSigSendType" SG_ 2589283965 DFB_InteractionStatus_ADA 3;
BA_ "GenSigSwitchedByIgnition" SG_ 2589283965 DFB_InteractionStatus_ADA 0;
BA_ "GenSigSendType" SG_ 2589283965 FaceRec2_Control_Challenge_Req 3;
BA_ "GenSigSwitchedByIgnition" SG_ 2589283965 FaceRec2_Control_Challenge_Req 0;
BA_ "GenSigSendType" SG_ 2589283965 Info_El_Lade_Fehler 3;
BA_ "GenSigSwitchedByIgnition" SG_ 2589283965 Info_El_Lade_Fehler 0;
BA_ "Fehlerwert" SG_ 2589283965 Info_El_Lade_Fehler 1;
BA_ "GenSigSendType" SG_ 2589283965 SpeechAssistant_State 3;
BA_ "GenSigSwitchedByIgnition" SG_ 2589283965 SpeechAssistant_State 0;
BA_ "GenSigSendType" SG_ 2589283965 ZR_Plattform 3;
BA_ "GenSigSwitchedByIgnition" SG_ 2589283965 ZR_Plattform 0;
BA_ "GenSigSendType" SG_ 2463978864 ZR_BedienDisp_X_contr_iClima_av 3;
BA_ "GenSigSwitchedByIgnition" SG_ 2463978864 ZR_BedienDisp_X_contr_iClima_av 0;
BA_ "Fehlerwert" SG_ 2463978864 ZR_BedienDisp_X_contr_iClima_av 3;
BA_ "GenSigSendType" SG_ 2463978864 ZR_BedienDisp_X_control_fct 3;
BA_ "GenSigSwitchedByIgnition" SG_ 2463978864 ZR_BedienDisp_X_control_fct 0;
BA_ "Fehlerwert" SG_ 2463978864 ZR_BedienDisp_X_control_fct 15;
BA_ "GenSigSendType" SG_ 2463978864 ZR_BedienDisp_X_control_iClima 3;
BA_ "GenSigSwitchedByIgnition" SG_ 2463978864 ZR_BedienDisp_X_control_iClima 0;
BA_ "Fehlerwert" SG_ 2463978864 ZR_BedienDisp_X_control_iClima 15;
BA_ "GenSigSendType" SG_ 2463978864 ZR_BedienDisp_X_control_MapMode 3;
BA_ "GenSigSwitchedByIgnition" SG_ 2463978864 ZR_BedienDisp_X_control_MapMode 0;
BA_ "Fehlerwert" SG_ 2463978864 ZR_BedienDisp_X_control_MapMode 7;
BA_ "GenSigSendType" SG_ 2463978864 ZR_BedienDisp_X_control_MapZoom 3;
BA_ "GenSigSwitchedByIgnition" SG_ 2463978864 ZR_BedienDisp_X_control_MapZoom 0;
BA_ "GenSigSendType" SG_ 2463978864 ZR_BedienDisp_X_control_Point 3;
BA_ "GenSigSwitchedByIgnition" SG_ 2463978864 ZR_BedienDisp_X_control_Point 0;
BA_ "Fehlerwert" SG_ 2463978864 ZR_BedienDisp_X_control_Point 7;
BA_ "GenSigSendType" SG_ 2463978864 ZR_BedienDisp_X_control_sound 3;
BA_ "GenSigSwitchedByIgnition" SG_ 2463978864 ZR_BedienDisp_X_control_sound 0;
BA_ "GenSigSendType" SG_ 2463978864 ZR_BedienDisp_X_control_surround 3;
BA_ "GenSigStartValue" SG_ 2463978864 ZR_BedienDisp_X_control_surround 126;
BA_ "GenSigSwitchedByIgnition" SG_ 2463978864 ZR_BedienDisp_X_control_surround 0;
BA_ "Fehlerwert" SG_ 2463978864 ZR_BedienDisp_X_control_surround 127;
BA_ "GenSigSendType" SG_ 2463978864 ZR_BedienDisp_X_control_vol 3;
BA_ "GenSigStartValue" SG_ 2463978864 ZR_BedienDisp_X_control_vol 126;
BA_ "GenSigSwitchedByIgnition" SG_ 2463978864 ZR_BedienDisp_X_control_vol 0;
BA_ "Fehlerwert" SG_ 2463978864 ZR_BedienDisp_X_control_vol 127;
BA_ "GenSigSendType" SG_ 2463978864 ZR_BedienDisp_X_control_vol_max 3;
BA_ "GenSigStartValue" SG_ 2463978864 ZR_BedienDisp_X_control_vol_max 62;
BA_ "GenSigSwitchedByIgnition" SG_ 2463978864 ZR_BedienDisp_X_control_vol_max 0;
BA_ "Fehlerwert" SG_ 2463978864 ZR_BedienDisp_X_control_vol_max 63;
BA_ "GenSigSendType" SG_ 2463978864 ZR_BedienDisp_X_control_vol_min 3;
BA_ "GenSigStartValue" SG_ 2463978864 ZR_BedienDisp_X_control_vol_min 62;
BA_ "GenSigSwitchedByIgnition" SG_ 2463978864 ZR_BedienDisp_X_control_vol_min 0;
BA_ "Fehlerwert" SG_ 2463978864 ZR_BedienDisp_X_control_vol_min 63;
BA_ "GenSigSendType" SG_ 2463978864 ZR_BedienDisp_X_fokus_zone 3;
BA_ "GenSigSwitchedByIgnition" SG_ 2463978864 ZR_BedienDisp_X_fokus_zone 0;
BA_ "Fehlerwert" SG_ 2463978864 ZR_BedienDisp_X_fokus_zone 15;
BA_ "GenSigSendType" SG_ 2463978864 ZR_BedienDisp_X_navidot_position 3;
BA_ "GenSigSwitchedByIgnition" SG_ 2463978864 ZR_BedienDisp_X_navidot_position 0;
BA_ "Fehlerwert" SG_ 2463978864 ZR_BedienDisp_X_navidot_position 7;
BA_ "GenSigSendType" SG_ 388 BCM_BF_Spg_Absenkung 0;
BA_ "GenSigSwitchedByIgnition" SG_ 388 BCM_BF_Spg_Absenkung 0;
BA_ "GenSigSendType" SG_ 388 BCM_Spg_Synchron 0;
BA_ "GenSigSwitchedByIgnition" SG_ 388 BCM_Spg_Synchron 0;
BA_ "GenSigSendType" SG_ 388 FH_BT_hoch 6;
BA_ "GenSigSwitchedByIgnition" SG_ 388 FH_BT_hoch 0;
BA_ "GenSigSendType" SG_ 388 FH_BT_tief 6;
BA_ "GenSigSwitchedByIgnition" SG_ 388 FH_BT_tief 0;
BA_ "GenSigSendType" SG_ 388 FH_FT_hoch 6;
BA_ "GenSigSwitchedByIgnition" SG_ 388 FH_FT_hoch 0;
BA_ "GenSigSendType" SG_ 388 FH_FT_tief 6;
BA_ "GenSigSwitchedByIgnition" SG_ 388 FH_FT_tief 0;
BA_ "GenSigSendType" SG_ 388 FH_HBFS_hoch 6;
BA_ "GenSigSwitchedByIgnition" SG_ 388 FH_HBFS_hoch 0;
BA_ "GenSigSendType" SG_ 388 FH_HBFS_tief 6;
BA_ "GenSigSwitchedByIgnition" SG_ 388 FH_HBFS_tief 0;
BA_ "GenSigSendType" SG_ 388 FH_HFS_hoch 6;
BA_ "GenSigSwitchedByIgnition" SG_ 388 FH_HFS_hoch 0;
BA_ "GenSigSendType" SG_ 388 FH_HFS_tief 6;
BA_ "GenSigSwitchedByIgnition" SG_ 388 FH_HFS_tief 0;
BA_ "GenSigSendType" SG_ 388 VIP_Freigabe 0;
BA_ "GenSigSwitchedByIgnition" SG_ 388 VIP_Freigabe 0;
BA_ "GenSigSendType" SG_ 388 VIP_Sensor_betaetigt 6;
BA_ "GenSigSwitchedByIgnition" SG_ 388 VIP_Sensor_betaetigt 0;
BA_ "GenSigSendType" SG_ 388 ZV_01_BZ 0;
BA_ "GenSigFuncType" SG_ 388 ZV_01_BZ 1;
BA_ "GenSigSendType" SG_ 388 ZV_01_CRC 0;
BA_ "GenSigFuncType" SG_ 388 ZV_01_CRC 2;
BA_ "GenSigSendType" SG_ 388 ZV_auf_BT 6;
BA_ "GenSigSwitchedByIgnition" SG_ 388 ZV_auf_BT 0;
BA_ "GenSigSendType" SG_ 388 ZV_auf_FT 6;
BA_ "GenSigSwitchedByIgnition" SG_ 388 ZV_auf_FT 0;
BA_ "GenSigSendType" SG_ 388 ZV_auf_Funk 6;
BA_ "GenSigSwitchedByIgnition" SG_ 388 ZV_auf_Funk 0;
BA_ "GenSigSendType" SG_ 388 ZV_auf_Kessy 6;
BA_ "GenSigSwitchedByIgnition" SG_ 388 ZV_auf_Kessy 0;
BA_ "GenSigSendType" SG_ 388 ZV_auto_Ansteuerung 6;
BA_ "GenSigSwitchedByIgnition" SG_ 388 ZV_auto_Ansteuerung 0;
BA_ "GenSigSendType" SG_ 388 ZV_BT_entriegeln 6;
BA_ "GenSigSwitchedByIgnition" SG_ 388 ZV_BT_entriegeln 0;
BA_ "GenSigSendType" SG_ 388 ZV_BT_verriegeln 6;
BA_ "GenSigSwitchedByIgnition" SG_ 388 ZV_BT_verriegeln 0;
BA_ "GenSigSendType" SG_ 388 ZV_entriegeln_Anf 6;
BA_ "GenSigSwitchedByIgnition" SG_ 388 ZV_entriegeln_Anf 0;
BA_ "GenSigSendType" SG_ 388 ZV_FT_entriegeln 6;
BA_ "GenSigSwitchedByIgnition" SG_ 388 ZV_FT_entriegeln 0;
BA_ "GenSigSendType" SG_ 388 ZV_FT_verriegeln 6;
BA_ "GenSigSwitchedByIgnition" SG_ 388 ZV_FT_verriegeln 0;
BA_ "GenSigSendType" SG_ 388 ZV_HBFS_entriegeln 6;
BA_ "GenSigSwitchedByIgnition" SG_ 388 ZV_HBFS_entriegeln 0;
BA_ "GenSigSendType" SG_ 388 ZV_HBFS_verriegeln 6;
BA_ "GenSigSwitchedByIgnition" SG_ 388 ZV_HBFS_verriegeln 0;
BA_ "GenSigSendType" SG_ 388 ZV_HFS_entriegeln 6;
BA_ "GenSigSwitchedByIgnition" SG_ 388 ZV_HFS_entriegeln 0;
BA_ "GenSigSendType" SG_ 388 ZV_HFS_verriegeln 6;
BA_ "GenSigSwitchedByIgnition" SG_ 388 ZV_HFS_verriegeln 0;
BA_ "GenSigSendType" SG_ 388 ZV_HSK_entriegeln 6;
BA_ "GenSigSwitchedByIgnition" SG_ 388 ZV_HSK_entriegeln 0;
BA_ "GenSigSendType" SG_ 388 ZV_HSK_verriegeln 6;
BA_ "GenSigSwitchedByIgnition" SG_ 388 ZV_HSK_verriegeln 0;
BA_ "GenSigSendType" SG_ 388 ZV_LED_Steuerung 6;
BA_ "GenSigSwitchedByIgnition" SG_ 388 ZV_LED_Steuerung 0;
BA_ "GenSigSendType" SG_ 388 ZV_LED_Uebernahme 6;
BA_ "GenSigSwitchedByIgnition" SG_ 388 ZV_LED_Uebernahme 0;
BA_ "GenSigSendType" SG_ 388 ZV_Signatur 6;
BA_ "GenSigSwitchedByIgnition" SG_ 388 ZV_Signatur 0;
BA_ "GenSigSendType" SG_ 388 ZV_Softtouch_betaetigt 6;
BA_ "GenSigSwitchedByIgnition" SG_ 388 ZV_Softtouch_betaetigt 0;
BA_ "GenSigSendType" SG_ 388 ZV_Spg_Anklappen 6;
BA_ "GenSigSwitchedByIgnition" SG_ 388 ZV_Spg_Anklappen 0;
BA_ "GenSigSendType" SG_ 388 ZV_Verdeck_auf 6;
BA_ "GenSigSwitchedByIgnition" SG_ 388 ZV_Verdeck_auf 0;
BA_ "GenSigSendType" SG_ 388 ZV_Verdeck_zu 6;
BA_ "GenSigSwitchedByIgnition" SG_ 388 ZV_Verdeck_zu 0;
BA_ "GenSigSendType" SG_ 388 ZV_zentral_entsafen 6;
BA_ "GenSigSwitchedByIgnition" SG_ 388 ZV_zentral_entsafen 0;
BA_ "GenSigSendType" SG_ 388 ZV_zentral_safen 6;
BA_ "GenSigSwitchedByIgnition" SG_ 388 ZV_zentral_safen 0;
BA_ "GenSigSendType" SG_ 388 ZV_zu_BT 6;
BA_ "GenSigSwitchedByIgnition" SG_ 388 ZV_zu_BT 0;
BA_ "GenSigSendType" SG_ 388 ZV_zu_FT 6;
BA_ "GenSigSwitchedByIgnition" SG_ 388 ZV_zu_FT 0;
BA_ "GenSigSendType" SG_ 388 ZV_zu_Funk 6;
BA_ "GenSigSwitchedByIgnition" SG_ 388 ZV_zu_Funk 0;
BA_ "GenSigSendType" SG_ 388 ZV_zu_Kessy 6;
BA_ "GenSigSwitchedByIgnition" SG_ 388 ZV_zu_Kessy 0;
BA_ "GenSigSendType" SG_ 388 ZV_zu_Zeitl_Nachverr 6;
BA_ "GenSigSwitchedByIgnition" SG_ 388 ZV_zu_Zeitl_Nachverr 0;
BA_ "GenSigSendType" SG_ 1411 BCM_FH_Freigabe 3;
BA_ "GenSigSwitchedByIgnition" SG_ 1411 BCM_FH_Freigabe 0;
BA_ "GenSigSendType" SG_ 1411 BCM_HSK_Freigabe 3;
BA_ "GenSigSwitchedByIgnition" SG_ 1411 BCM_HSK_Freigabe 0;
BA_ "GenSigSendType" SG_ 1411 BCM_Komfortfkt_Freigabe 3;
BA_ "GenSigSwitchedByIgnition" SG_ 1411 BCM_Komfortfkt_Freigabe 0;
BA_ "GenSigSendType" SG_ 1411 BCM_Tankklappensteller_Fehler 0;
BA_ "GenSigSwitchedByIgnition" SG_ 1411 BCM_Tankklappensteller_Fehler 0;
BA_ "Fehlerwert" SG_ 1411 BCM_Tankklappensteller_Fehler 1;
BA_ "GenSigSendType" SG_ 1411 BCM_Verdeck_Freigabe 3;
BA_ "GenSigSwitchedByIgnition" SG_ 1411 BCM_Verdeck_Freigabe 0;
BA_ "GenSigSendType" SG_ 1411 DWA_aktiv 3;
BA_ "GenSigSwitchedByIgnition" SG_ 1411 DWA_aktiv 0;
BA_ "GenSigSendType" SG_ 1411 FBS_IDG_in_Reichweite 6;
BA_ "GenSigSwitchedByIgnition" SG_ 1411 FBS_IDG_in_Reichweite 0;
BA_ "GenSigSendType" SG_ 1411 FBS_Warn_Schluessel_Batt 3;
BA_ "GenSigSwitchedByIgnition" SG_ 1411 FBS_Warn_Schluessel_Batt 0;
BA_ "GenSigSendType" SG_ 1411 FFB_Auf_Taste 6;
BA_ "GenSigSwitchedByIgnition" SG_ 1411 FFB_Auf_Taste 0;
BA_ "GenSigSendType" SG_ 1411 FFB_CarFinder 6;
BA_ "GenSigSwitchedByIgnition" SG_ 1411 FFB_CarFinder 0;
BA_ "GenSigSendType" SG_ 1411 FFB_HDF_Taste 6;
BA_ "GenSigSwitchedByIgnition" SG_ 1411 FFB_HDF_Taste 0;
BA_ "GenSigSendType" SG_ 1411 FFB_Komfortoeffnen 6;
BA_ "GenSigSwitchedByIgnition" SG_ 1411 FFB_Komfortoeffnen 0;
BA_ "GenSigSendType" SG_ 1411 FFB_Komfortschliessen 6;
BA_ "GenSigSwitchedByIgnition" SG_ 1411 FFB_Komfortschliessen 0;
BA_ "GenSigSendType" SG_ 1411 FFB_Panik_Taste 6;
BA_ "GenSigSwitchedByIgnition" SG_ 1411 FFB_Panik_Taste 0;
BA_ "GenSigSendType" SG_ 1411 FFB_Zu_Taste 6;
BA_ "GenSigSwitchedByIgnition" SG_ 1411 FFB_Zu_Taste 0;
BA_ "GenSigSendType" SG_ 1411 HBFS_gesafet 3;
BA_ "GenSigSwitchedByIgnition" SG_ 1411 HBFS_gesafet 0;
BA_ "GenSigSendType" SG_ 1411 HBFS_verriegelt 3;
BA_ "GenSigSwitchedByIgnition" SG_ 1411 HBFS_verriegelt 0;
BA_ "GenSigSendType" SG_ 1411 HD_Hauptraste 3;
BA_ "GenSigSwitchedByIgnition" SG_ 1411 HD_Hauptraste 0;
BA_ "GenSigSendType" SG_ 1411 HD_Vorraste 3;
BA_ "GenSigSwitchedByIgnition" SG_ 1411 HD_Vorraste 0;
BA_ "GenSigSendType" SG_ 1411 HFS_gesafet 3;
BA_ "GenSigSwitchedByIgnition" SG_ 1411 HFS_gesafet 0;
BA_ "GenSigSendType" SG_ 1411 HFS_verriegelt 3;
BA_ "GenSigSwitchedByIgnition" SG_ 1411 HFS_verriegelt 0;
BA_ "GenSigSendType" SG_ 1411 IRUE_aktiv 3;
BA_ "GenSigSwitchedByIgnition" SG_ 1411 IRUE_aktiv 0;
BA_ "GenSigSendType" SG_ 1411 IRUE_Taster_Fkts_LED 3;
BA_ "GenSigSwitchedByIgnition" SG_ 1411 IRUE_Taster_Fkts_LED 0;
BA_ "GenSigSendType" SG_ 1411 VIP_Sensor_STSG_HBFS_betaetigt 6;
BA_ "GenSigSwitchedByIgnition" SG_ 1411 VIP_Sensor_STSG_HBFS_betaetigt 0;
BA_ "GenSigSendType" SG_ 1411 VIP_Sensor_STSG_HFS_betaetigt 6;
BA_ "GenSigSwitchedByIgnition" SG_ 1411 VIP_Sensor_STSG_HFS_betaetigt 0;
BA_ "GenSigSendType" SG_ 1411 ZV_Anf_Challenge_Auth 6;
BA_ "GenSigSwitchedByIgnition" SG_ 1411 ZV_Anf_Challenge_Auth 0;
BA_ "GenSigSendType" SG_ 1411 ZV_BT_offen 3;
BA_ "GenSigSwitchedByIgnition" SG_ 1411 ZV_BT_offen 0;
BA_ "GenSigSendType" SG_ 1411 ZV_Einzeltuerentriegelung 3;
BA_ "GenSigSwitchedByIgnition" SG_ 1411 ZV_Einzeltuerentriegelung 0;
BA_ "GenSigSendType" SG_ 1411 ZV_eRWK_Umfeld_Pruefung 6;
BA_ "GenSigSwitchedByIgnition" SG_ 1411 ZV_eRWK_Umfeld_Pruefung 0;
BA_ "GenSigSendType" SG_ 1411 ZV_FT_offen 3;
BA_ "GenSigSwitchedByIgnition" SG_ 1411 ZV_FT_offen 0;
BA_ "GenSigSendType" SG_ 1411 ZV_gesafet_extern_ist 3;
BA_ "GenSigSwitchedByIgnition" SG_ 1411 ZV_gesafet_extern_ist 0;
BA_ "GenSigSendType" SG_ 1411 ZV_gesafet_extern_soll 3;
BA_ "GenSigSwitchedByIgnition" SG_ 1411 ZV_gesafet_extern_soll 0;
BA_ "GenSigSendType" SG_ 1411 ZV_HBFS_offen 3;
BA_ "GenSigSwitchedByIgnition" SG_ 1411 ZV_HBFS_offen 0;
BA_ "GenSigSendType" SG_ 1411 ZV_HD_offen 3;
BA_ "GenSigSwitchedByIgnition" SG_ 1411 ZV_HD_offen 0;
BA_ "GenSigSendType" SG_ 1411 ZV_Heckeinzelentriegelung 3;
BA_ "GenSigSwitchedByIgnition" SG_ 1411 ZV_Heckeinzelentriegelung 0;
BA_ "GenSigSendType" SG_ 1411 ZV_HFS_offen 3;
BA_ "GenSigSwitchedByIgnition" SG_ 1411 ZV_HFS_offen 0;
BA_ "GenSigSendType" SG_ 1411 ZV_HS_offen 3;
BA_ "GenSigSwitchedByIgnition" SG_ 1411 ZV_HS_offen 0;
BA_ "GenSigSendType" SG_ 1411 ZV_ist_Zustand_verfuegbar 3;
BA_ "GenSigSwitchedByIgnition" SG_ 1411 ZV_ist_Zustand_verfuegbar 0;
BA_ "GenSigSendType" SG_ 1411 ZV_Oeffnungsmodus 3;
BA_ "GenSigSwitchedByIgnition" SG_ 1411 ZV_Oeffnungsmodus 0;
BA_ "GenSigSendType" SG_ 1411 ZV_Rollo_auf 3;
BA_ "GenSigSwitchedByIgnition" SG_ 1411 ZV_Rollo_auf 0;
BA_ "GenSigSendType" SG_ 1411 ZV_Rollo_zu 3;
BA_ "GenSigSwitchedByIgnition" SG_ 1411 ZV_Rollo_zu 0;
BA_ "GenSigSendType" SG_ 1411 ZV_SAD_auf 3;
BA_ "GenSigSwitchedByIgnition" SG_ 1411 ZV_SAD_auf 0;
BA_ "GenSigSendType" SG_ 1411 ZV_SAD_zu 3;
BA_ "GenSigSwitchedByIgnition" SG_ 1411 ZV_SAD_zu 0;
BA_ "GenSigSendType" SG_ 1411 ZV_SafeFunktion_aktiv 3;
BA_ "GenSigSwitchedByIgnition" SG_ 1411 ZV_SafeFunktion_aktiv 0;
BA_ "GenSigSendType" SG_ 1411 ZV_Schluessel_Zugang 3;
BA_ "GenSigSwitchedByIgnition" SG_ 1411 ZV_Schluessel_Zugang 0;
BA_ "GenSigSendType" SG_ 1411 ZV_STSG_Crashzustand 4;
BA_ "GenSigSwitchedByIgnition" SG_ 1411 ZV_STSG_Crashzustand 0;
BA_ "GenSigSendType" SG_ 1411 ZV_STSG_eKiSi_defekt 4;
BA_ "GenSigSwitchedByIgnition" SG_ 1411 ZV_STSG_eKiSi_defekt 0;
BA_ "GenSigSendType" SG_ 1411 ZV_STSG_HBFS_Anf 3;
BA_ "GenSigSwitchedByIgnition" SG_ 1411 ZV_STSG_HBFS_Anf 0;
BA_ "GenSigSendType" SG_ 1411 ZV_STSG_HFS_Anf 3;
BA_ "GenSigSwitchedByIgnition" SG_ 1411 ZV_STSG_HFS_Anf 0;
BA_ "GenSigSendType" SG_ 1411 ZV_Tankklappe_offen 0;
BA_ "GenSigSwitchedByIgnition" SG_ 1411 ZV_Tankklappe_offen 0;
BA_ "GenSigSendType" SG_ 1411 ZV_verriegeln_Anf 6;
BA_ "GenSigSwitchedByIgnition" SG_ 1411 ZV_verriegeln_Anf 0;
BA_ "GenSigSendType" SG_ 1411 ZV_verriegelt_extern_ist 3;
BA_ "GenSigSwitchedByIgnition" SG_ 1411 ZV_verriegelt_extern_ist 0;
BA_ "GenSigSendType" SG_ 1411 ZV_verriegelt_extern_soll 3;
BA_ "GenSigSwitchedByIgnition" SG_ 1411 ZV_verriegelt_extern_soll 0;
BA_ "GenSigSendType" SG_ 1411 ZV_verriegelt_intern_ist 3;
BA_ "GenSigSwitchedByIgnition" SG_ 1411 ZV_verriegelt_intern_ist 0;
BA_ "GenSigSendType" SG_ 1411 ZV_verriegelt_intern_soll 3;
BA_ "GenSigSwitchedByIgnition" SG_ 1411 ZV_verriegelt_intern_soll 0;
BA_ "GenSigSendType" SG_ 1411 ZV_verriegelt_soll 3;
BA_ "GenSigSwitchedByIgnition" SG_ 1411 ZV_verriegelt_soll 0;
BA_REL_ "GenSigTimeoutTime" BU_SG_REL_ BedienDisp_mi SG_ 2463978710 OPS_ComfortReadyStatus 1000;
BA_REL_ "GenSigTimeoutTime" BU_SG_REL_ BedienDisp_mi SG_ 2463978710 OPS_DriverPresenceStatus 1000;
BA_REL_ "GenSigTimeoutTime" BU_SG_REL_ BedienDisp_mi SG_ 1140 MMI_State 5000;
BA_REL_ "GenSigTimeoutTime" BU_SG_REL_ BedienDisp_mi SG_ 2463978864 ZR_BedienDisp_X_control_sound 5000;
BA_REL_ "GenSigTimeoutTime" BU_SG_REL_ BedienDisp_mi SG_ 2463978864 ZR_BedienDisp_X_control_vol 5000;
BA_REL_ "GenSigTimeoutTime" BU_SG_REL_ BedienDisp_mi SG_ 2463978864 ZR_BedienDisp_X_control_vol_max 5000;
BA_REL_ "GenSigTimeoutTime" BU_SG_REL_ BedienDisp_mi SG_ 2463978864 ZR_BedienDisp_X_control_vol_min 5000;
BA_REL_ "GenSigTimeoutTime" BU_SG_REL_ BedienDisp_vo_mi SG_ 2463978710 OPS_ComfortReadyStatus 1000;
BA_REL_ "GenSigTimeoutTime" BU_SG_REL_ BedienDisp_vo_mi SG_ 2463978710 OPS_DriverPresenceStatus 1000;
BA_REL_ "GenSigTimeoutTime" BU_SG_REL_ BedienDisp_vo_mi SG_ 1140 MMI_State 5000;
BA_REL_ "GenSigTimeoutTime" BU_SG_REL_ BedienDisp_vo_mi SG_ 1140 ZR_DimOffs_DU_1 5000;
BA_REL_ "GenSigTimeoutTime" BU_SG_REL_ BedienDisp_vo_mi SG_ 1140 DI_Screendesign 5000;
BA_REL_ "GenSigTimeoutTime" BU_SG_REL_ BedienDisp_vo_mi SG_ 2463978864 ZR_BedienDisp_X_contr_iClima_av 5000;
BA_REL_ "GenSigTimeoutTime" BU_SG_REL_ BedienDisp_vo_mi SG_ 2463978864 ZR_BedienDisp_X_control_fct 5000;
BA_REL_ "GenSigTimeoutTime" BU_SG_REL_ BedienDisp_vo_mi SG_ 2463978864 ZR_BedienDisp_X_control_iClima 5000;
BA_REL_ "GenSigTimeoutTime" BU_SG_REL_ BedienDisp_vo_mi SG_ 2463978864 ZR_BedienDisp_X_control_MapMode 5000;
BA_REL_ "GenSigTimeoutTime" BU_SG_REL_ BedienDisp_vo_mi SG_ 2463978864 ZR_BedienDisp_X_control_MapZoom 5000;
BA_REL_ "GenSigTimeoutTime" BU_SG_REL_ BedienDisp_vo_mi SG_ 2463978864 ZR_BedienDisp_X_control_sound 5000;
BA_REL_ "GenSigTimeoutTime" BU_SG_REL_ BedienDisp_vo_mi SG_ 2463978864 ZR_BedienDisp_X_control_vol 5000;
BA_REL_ "GenSigTimeoutTime" BU_SG_REL_ BedienDisp_vo_mi SG_ 2463978864 ZR_BedienDisp_X_control_vol_max 5000;
BA_REL_ "GenSigTimeoutTime" BU_SG_REL_ BedienDisp_vo_mi SG_ 2463978864 ZR_BedienDisp_X_control_vol_min 5000;
BA_REL_ "GenSigTimeoutTime" BU_SG_REL_ BedienDisp_vo_mi SG_ 2463978864 ZR_BedienDisp_X_control_Point 5000;
BA_REL_ "GenSigTimeoutTime" BU_SG_REL_ BedienDisp_vo_mi SG_ 2463978864 ZR_BedienDisp_X_navidot_position 5000;
BA_REL_ "GenSigTimeoutTime" BU_SG_REL_ CDI SG_ 1718 UH_Monat 5000;
BA_REL_ "GenSigTimeoutTime" BU_SG_REL_ CDI SG_ 1718 UH_Jahr 5000;
BA_REL_ "GenSigTimeoutTime" BU_SG_REL_ CDI SG_ 1718 UH_Tag 5000;
BA_REL_ "GenSigTimeoutTime" BU_SG_REL_ CDI SG_ 1718 UH_Stunde 5000;
BA_REL_ "GenSigTimeoutTime" BU_SG_REL_ CDI SG_ 1718 UH_Minute 5000;
BA_REL_ "GenSigTimeoutTime" BU_SG_REL_ CDI SG_ 1718 UH_Sekunde 5000;
BA_REL_ "GenSigTimeoutTime" BU_SG_REL_ CDI SG_ 1716 VIN_01_MUX 2000;
BA_REL_ "GenSigTimeoutTime" BU_SG_REL_ CDI SG_ 1716 KS_Geheimnis_1 2000;
BA_REL_ "GenSigTimeoutTime" BU_SG_REL_ CDI SG_ 1716 VIN_4 2000;
BA_REL_ "GenSigTimeoutTime" BU_SG_REL_ CDI SG_ 1716 VIN_11 2000;
BA_REL_ "GenSigTimeoutTime" BU_SG_REL_ CDI SG_ 1716 KS_Geheimnis_2 2000;
BA_REL_ "GenSigTimeoutTime" BU_SG_REL_ CDI SG_ 1716 VIN_5 2000;
BA_REL_ "GenSigTimeoutTime" BU_SG_REL_ CDI SG_ 1716 VIN_12 2000;
BA_REL_ "GenSigTimeoutTime" BU_SG_REL_ CDI SG_ 1716 KS_Geheimnis_3 2000;
BA_REL_ "GenSigTimeoutTime" BU_SG_REL_ CDI SG_ 1716 VIN_6 2000;
BA_REL_ "GenSigTimeoutTime" BU_SG_REL_ CDI SG_ 1716 VIN_13 2000;
BA_REL_ "GenSigTimeoutTime" BU_SG_REL_ CDI SG_ 1716 KS_Geheimnis_4 2000;
BA_REL_ "GenSigTimeoutTime" BU_SG_REL_ CDI SG_ 1716 VIN_7 2000;
BA_REL_ "GenSigTimeoutTime" BU_SG_REL_ CDI SG_ 1716 VIN_14 2000;
BA_REL_ "GenSigTimeoutTime" BU_SG_REL_ CDI SG_ 1716 VIN_1 2000;
BA_REL_ "GenSigTimeoutTime" BU_SG_REL_ CDI SG_ 1716 VIN_8 2000;
BA_REL_ "GenSigTimeoutTime" BU_SG_REL_ CDI SG_ 1716 VIN_15 2000;
BA_REL_ "GenSigTimeoutTime" BU_SG_REL_ CDI SG_ 1716 VIN_2 2000;
BA_REL_ "GenSigTimeoutTime" BU_SG_REL_ CDI SG_ 1716 VIN_9 2000;
BA_REL_ "GenSigTimeoutTime" BU_SG_REL_ CDI SG_ 1716 VIN_16 2000;
BA_REL_ "GenSigTimeoutTime" BU_SG_REL_ CDI SG_ 1716 VIN_3 2000;
BA_REL_ "GenSigTimeoutTime" BU_SG_REL_ CDI SG_ 1716 VIN_10 2000;
BA_REL_ "GenSigTimeoutTime" BU_SG_REL_ CDI SG_ 1716 VIN_17 2000;
BA_REL_ "GenSigTimeoutTime" BU_SG_REL_ CDI SG_ 1140 DI_Screendesign 5000;
BA_REL_ "GenSigTimeoutTime" BU_SG_REL_ CDI SG_ 1411 ZV_verriegelt_extern_soll 2000;
BA_REL_ "GenSigTimeoutTime" BU_SG_REL_ CDI SG_ 1411 ZV_FT_offen 2000;
BA_REL_ "GenSigTimeoutTime" BU_SG_REL_ CDI SG_ 1411 ZV_BT_offen 2000;
BA_REL_ "GenSigTimeoutTime" BU_SG_REL_ CDI SG_ 1411 ZV_HFS_offen 2000;
BA_REL_ "GenSigTimeoutTime" BU_SG_REL_ CDI SG_ 1411 ZV_HBFS_offen 2000;
BA_REL_ "GenSigTimeoutTime" BU_SG_REL_ ConMod_CD SG_ 2463978710 OPS_ComfortReadyStatus 1000;
BA_REL_ "GenSigTimeoutTime" BU_SG_REL_ ConMod_CD SG_ 1716 VIN_01_MUX 2000;
BA_REL_ "GenSigTimeoutTime" BU_SG_REL_ ConMod_CD SG_ 1716 VIN_4 2000;
BA_REL_ "GenSigTimeoutTime" BU_SG_REL_ ConMod_CD SG_ 1716 VIN_11 2000;
BA_REL_ "GenSigTimeoutTime" BU_SG_REL_ ConMod_CD SG_ 1716 VIN_5 2000;
BA_REL_ "GenSigTimeoutTime" BU_SG_REL_ ConMod_CD SG_ 1716 VIN_12 2000;
BA_REL_ "GenSigTimeoutTime" BU_SG_REL_ ConMod_CD SG_ 1716 VIN_6 2000;
BA_REL_ "GenSigTimeoutTime" BU_SG_REL_ ConMod_CD SG_ 1716 VIN_13 2000;
BA_REL_ "GenSigTimeoutTime" BU_SG_REL_ ConMod_CD SG_ 1716 VIN_7 2000;
BA_REL_ "GenSigTimeoutTime" BU_SG_REL_ ConMod_CD SG_ 1716 VIN_14 2000;
BA_REL_ "GenSigTimeoutTime" BU_SG_REL_ ConMod_CD SG_ 1716 VIN_1 2000;
BA_REL_ "GenSigTimeoutTime" BU_SG_REL_ ConMod_CD SG_ 1716 VIN_8 2000;
BA_REL_ "GenSigTimeoutTime" BU_SG_REL_ ConMod_CD SG_ 1716 VIN_15 2000;
BA_REL_ "GenSigTimeoutTime" BU_SG_REL_ ConMod_CD SG_ 1716 VIN_2 2000;
BA_REL_ "GenSigTimeoutTime" BU_SG_REL_ ConMod_CD SG_ 1716 VIN_9 2000;
BA_REL_ "GenSigTimeoutTime" BU_SG_REL_ ConMod_CD SG_ 1716 VIN_16 2000;
BA_REL_ "GenSigTimeoutTime" BU_SG_REL_ ConMod_CD SG_ 1716 VIN_3 2000;
BA_REL_ "GenSigTimeoutTime" BU_SG_REL_ ConMod_CD SG_ 1716 VIN_10 2000;
BA_REL_ "GenSigTimeoutTime" BU_SG_REL_ ConMod_CD SG_ 1716 VIN_17 2000;
BA_REL_ "GenSigTimeoutTime" BU_SG_REL_ DashCAM SG_ 1716 VIN_01_MUX 2000;
BA_REL_ "GenSigTimeoutTime" BU_SG_REL_ DashCAM SG_ 1716 VIN_4 2000;
BA_REL_ "GenSigTimeoutTime" BU_SG_REL_ DashCAM SG_ 1716 VIN_11 2000;
BA_REL_ "GenSigTimeoutTime" BU_SG_REL_ DashCAM SG_ 1716 VIN_5 2000;
BA_REL_ "GenSigTimeoutTime" BU_SG_REL_ DashCAM SG_ 1716 VIN_12 2000;
BA_REL_ "GenSigTimeoutTime" BU_SG_REL_ DashCAM SG_ 1716 VIN_6 2000;
BA_REL_ "GenSigTimeoutTime" BU_SG_REL_ DashCAM SG_ 1716 VIN_13 2000;
BA_REL_ "GenSigTimeoutTime" BU_SG_REL_ DashCAM SG_ 1716 VIN_7 2000;
BA_REL_ "GenSigTimeoutTime" BU_SG_REL_ DashCAM SG_ 1716 VIN_14 2000;
BA_REL_ "GenSigTimeoutTime" BU_SG_REL_ DashCAM SG_ 1716 VIN_1 2000;
BA_REL_ "GenSigTimeoutTime" BU_SG_REL_ DashCAM SG_ 1716 VIN_8 2000;
BA_REL_ "GenSigTimeoutTime" BU_SG_REL_ DashCAM SG_ 1716 VIN_15 2000;
BA_REL_ "GenSigTimeoutTime" BU_SG_REL_ DashCAM SG_ 1716 VIN_2 2000;
BA_REL_ "GenSigTimeoutTime" BU_SG_REL_ DashCAM SG_ 1716 VIN_9 2000;
BA_REL_ "GenSigTimeoutTime" BU_SG_REL_ DashCAM SG_ 1716 VIN_16 2000;
BA_REL_ "GenSigTimeoutTime" BU_SG_REL_ DashCAM SG_ 1716 VIN_3 2000;
BA_REL_ "GenSigTimeoutTime" BU_SG_REL_ DashCAM SG_ 1716 VIN_10 2000;
BA_REL_ "GenSigTimeoutTime" BU_SG_REL_ DashCAM SG_ 1716 VIN_17 2000;
BA_REL_ "GenSigTimeoutTime" BU_SG_REL_ Gateway_Max SG_ 2589283965 DFB_CILState_ADA 5000;
BA_REL_ "GenSigTimeoutTime" BU_SG_REL_ Gateway_Max SG_ 2589283965 DFB_InteractionStatus_ADA 5000;
BA_REL_ "GenSigTimeoutTime" BU_SG_REL_ Gateway_Max SG_ 2589283965 SpeechAssistant_State 5000;
BA_REL_ "GenSigTimeoutTime" BU_SG_REL_ Gateway_Max SG_ 2589283965 Info_El_Lade_Fehler 5000;
BA_REL_ "GenSigTimeoutTime" BU_SG_REL_ ICC_IO_Node SG_ 1411 ZV_verriegelt_extern_soll 2000;
BA_REL_ "GenSigTimeoutTime" BU_SG_REL_ ICC_IO_Node SG_ 1411 ZV_FT_offen 2000;
BA_REL_ "GenSigTimeoutTime" BU_SG_REL_ ICC_IO_Node SG_ 1411 ZV_BT_offen 2000;
BA_REL_ "GenSigTimeoutTime" BU_SG_REL_ ICC_IO_Node SG_ 1411 ZV_HFS_offen 2000;
BA_REL_ "GenSigTimeoutTime" BU_SG_REL_ ICC_IO_Node SG_ 1411 ZV_HBFS_offen 2000;
BA_REL_ "GenSigTimeoutTime" BU_SG_REL_ ICC_IO_Node SG_ 1411 ZV_HD_offen 2000;
BA_REL_ "GenSigTimeoutTime" BU_SG_REL_ OCU SG_ 975 HBFS_Tuer_geoeffnet 1000;
BA_REL_ "GenSigTimeoutTime" BU_SG_REL_ OCU SG_ 975 HBFS_verriegelt 1000;
BA_REL_ "GenSigTimeoutTime" BU_SG_REL_ OCU SG_ 975 HBFS_gesafet 1000;
BA_REL_ "GenSigTimeoutTime" BU_SG_REL_ OCU SG_ 975 HBFS_Tuer_Status 1000;
BA_REL_ "GenSigTimeoutTime" BU_SG_REL_ OCU SG_ 975 HBFS_FH_Oeffnung 1000;
BA_REL_ "GenSigTimeoutTime" BU_SG_REL_ OCU SG_ 975 HBFS_FH_Fang 1000;
BA_REL_ "GenSigTimeoutTime" BU_SG_REL_ OCU SG_ 975 HBFS_FH_normiert 1000;
BA_REL_ "GenSigTimeoutTime" BU_SG_REL_ OCU SG_ 974 HFS_Tuer_geoeffnet 1000;
BA_REL_ "GenSigTimeoutTime" BU_SG_REL_ OCU SG_ 974 HFS_verriegelt 1000;
BA_REL_ "GenSigTimeoutTime" BU_SG_REL_ OCU SG_ 974 HFS_gesafet 1000;
BA_REL_ "GenSigTimeoutTime" BU_SG_REL_ OCU SG_ 974 HFS_Tuer_Status 1000;
BA_REL_ "GenSigTimeoutTime" BU_SG_REL_ OCU SG_ 974 HFS_FH_Oeffnung 1000;
BA_REL_ "GenSigTimeoutTime" BU_SG_REL_ OCU SG_ 974 HFS_FH_Fang 1000;
BA_REL_ "GenSigTimeoutTime" BU_SG_REL_ OCU SG_ 974 HFS_FH_normiert 1000;
BA_REL_ "GenSigTimeoutTime" BU_SG_REL_ OCU SG_ 1718 UH_Typ 5000;
BA_REL_ "GenSigTimeoutTime" BU_SG_REL_ OCU SG_ 1718 UH_DLS 5000;
BA_REL_ "GenSigTimeoutTime" BU_SG_REL_ OCU SG_ 1718 UH_Monat 5000;
BA_REL_ "GenSigTimeoutTime" BU_SG_REL_ OCU SG_ 1718 UH_Jahr 5000;
BA_REL_ "GenSigTimeoutTime" BU_SG_REL_ OCU SG_ 1718 UH_Tag 5000;
BA_REL_ "GenSigTimeoutTime" BU_SG_REL_ OCU SG_ 1718 UH_Stunde 5000;
BA_REL_ "GenSigTimeoutTime" BU_SG_REL_ OCU SG_ 1718 UH_Minute 5000;
BA_REL_ "GenSigTimeoutTime" BU_SG_REL_ OCU SG_ 1718 UH_Sekunde 5000;
BA_REL_ "GenSigTimeoutTime" BU_SG_REL_ OCU SG_ 995 VS_VD_zu_ver 1000;
BA_REL_ "GenSigTimeoutTime" BU_SG_REL_ OCU SG_ 995 VS_VD_entriegelt 1000;
BA_REL_ "GenSigTimeoutTime" BU_SG_REL_ OCU SG_ 995 VS_VD_offen_ver 1000;
BA_REL_ "GenSigTimeoutTime" BU_SG_REL_ OCU SG_ 995 VS_Verdeck_Anf 1000;
BA_REL_ "GenSigTimeoutTime" BU_SG_REL_ OCU SG_ 1716 VIN_01_MUX 2000;
BA_REL_ "GenSigTimeoutTime" BU_SG_REL_ OCU SG_ 1716 VIN_4 2000;
BA_REL_ "GenSigTimeoutTime" BU_SG_REL_ OCU SG_ 1716 VIN_11 2000;
BA_REL_ "GenSigTimeoutTime" BU_SG_REL_ OCU SG_ 1716 VIN_5 2000;
BA_REL_ "GenSigTimeoutTime" BU_SG_REL_ OCU SG_ 1716 VIN_12 2000;
BA_REL_ "GenSigTimeoutTime" BU_SG_REL_ OCU SG_ 1716 VIN_6 2000;
BA_REL_ "GenSigTimeoutTime" BU_SG_REL_ OCU SG_ 1716 VIN_13 2000;
BA_REL_ "GenSigTimeoutTime" BU_SG_REL_ OCU SG_ 1716 VIN_7 2000;
BA_REL_ "GenSigTimeoutTime" BU_SG_REL_ OCU SG_ 1716 VIN_14 2000;
BA_REL_ "GenSigTimeoutTime" BU_SG_REL_ OCU SG_ 1716 VIN_1 2000;
BA_REL_ "GenSigTimeoutTime" BU_SG_REL_ OCU SG_ 1716 VIN_8 2000;
BA_REL_ "GenSigTimeoutTime" BU_SG_REL_ OCU SG_ 1716 VIN_15 2000;
BA_REL_ "GenSigTimeoutTime" BU_SG_REL_ OCU SG_ 1716 VIN_2 2000;
BA_REL_ "GenSigTimeoutTime" BU_SG_REL_ OCU SG_ 1716 VIN_9 2000;
BA_REL_ "GenSigTimeoutTime" BU_SG_REL_ OCU SG_ 1716 VIN_16 2000;
BA_REL_ "GenSigTimeoutTime" BU_SG_REL_ OCU SG_ 1716 VIN_3 2000;
BA_REL_ "GenSigTimeoutTime" BU_SG_REL_ OCU SG_ 1716 VIN_10 2000;
BA_REL_ "GenSigTimeoutTime" BU_SG_REL_ OCU SG_ 1716 VIN_17 2000;
BA_REL_ "GenSigTimeoutTime" BU_SG_REL_ OCU SG_ 916 WBA_Fahrstufe_02 1600;
BA_REL_ "GenSigTimeoutTime" BU_SG_REL_ OCU SG_ 916 WBA_eing_Gang_02 1600;
BA_REL_ "GenSigTimeoutTime" BU_SG_REL_ OCU SG_ 916 WBA_Segeln_aktiv 1600;
BA_REL_ "GenSigTimeoutTime" BU_SG_REL_ OCU SG_ 916 WBA_GE_Zusatzwarnungen 1600;
BA_REL_ "GenSigTimeoutTime" BU_SG_REL_ OCU SG_ 916 GE_Sollgang 1600;
BA_REL_ "GenSigTimeoutTime" BU_SG_REL_ OCU SG_ 916 GE_Tipschaltempf_verfuegbar 1600;
BA_REL_ "GenSigTimeoutTime" BU_SG_REL_ OCU SG_ 1361 WFS_Schluessel_Fahrberecht 2000;
BA_REL_ "GenSigTimeoutTime" BU_SG_REL_ OCU SG_ 1361 WFS_ID_Geb_autorisiert_in_Kl15 2000;
BA_REL_ "GenSigTimeoutTime" BU_SG_REL_ OCU SG_ 1361 WFS_Klemmenfreigabe 2000;
BA_REL_ "GenSigTimeoutTime" BU_SG_REL_ OCU SG_ 1702 Wischer_vorne_aktiv 5000;
BA_REL_ "GenSigTimeoutTime" BU_SG_REL_ OCU SG_ 1702 Waschen_vorne_aktiv 5000;
BA_REL_ "GenSigTimeoutTime" BU_SG_REL_ OCU SG_ 1702 Wischer_vorne_defekt 5000;
BA_REL_ "GenSigTimeoutTime" BU_SG_REL_ OCU SG_ 1702 Wischer1_Wischgeschwindigkeit 5000;
BA_REL_ "GenSigTimeoutTime" BU_SG_REL_ OCU SG_ 388 ZV_FT_verriegeln 5000;
BA_REL_ "GenSigTimeoutTime" BU_SG_REL_ OCU SG_ 388 ZV_FT_entriegeln 5000;
BA_REL_ "GenSigTimeoutTime" BU_SG_REL_ OCU SG_ 388 ZV_BT_verriegeln 5000;
BA_REL_ "GenSigTimeoutTime" BU_SG_REL_ OCU SG_ 388 ZV_BT_entriegeln 5000;
BA_REL_ "GenSigTimeoutTime" BU_SG_REL_ OCU SG_ 388 ZV_HFS_verriegeln 5000;
BA_REL_ "GenSigTimeoutTime" BU_SG_REL_ OCU SG_ 388 ZV_HFS_entriegeln 5000;
BA_REL_ "GenSigTimeoutTime" BU_SG_REL_ OCU SG_ 388 ZV_HBFS_verriegeln 5000;
BA_REL_ "GenSigTimeoutTime" BU_SG_REL_ OCU SG_ 388 ZV_HBFS_entriegeln 5000;
BA_REL_ "GenSigTimeoutTime" BU_SG_REL_ OCU SG_ 388 ZV_zentral_safen 5000;
BA_REL_ "GenSigTimeoutTime" BU_SG_REL_ OCU SG_ 388 ZV_zentral_entsafen 5000;
BA_REL_ "GenSigTimeoutTime" BU_SG_REL_ OCU SG_ 388 VIP_Sensor_betaetigt 5000;
BA_REL_ "GenSigTimeoutTime" BU_SG_REL_ OCU SG_ 388 ZV_Signatur 5000;
BA_REL_ "GenSigTimeoutTime" BU_SG_REL_ OCU SG_ 1411 ZV_verriegelt_intern_ist 2000;
BA_REL_ "GenSigTimeoutTime" BU_SG_REL_ OCU SG_ 1411 ZV_verriegelt_extern_ist 2000;
BA_REL_ "GenSigTimeoutTime" BU_SG_REL_ OCU SG_ 1411 ZV_verriegelt_extern_soll 2000;
BA_REL_ "GenSigTimeoutTime" BU_SG_REL_ OCU SG_ 1411 ZV_gesafet_extern_ist 2000;
BA_REL_ "GenSigTimeoutTime" BU_SG_REL_ OCU SG_ 1411 ZV_Heckeinzelentriegelung 2000;
BA_REL_ "GenSigTimeoutTime" BU_SG_REL_ OCU SG_ 1411 ZV_FT_offen 2000;
BA_REL_ "GenSigTimeoutTime" BU_SG_REL_ OCU SG_ 1411 ZV_BT_offen 2000;
BA_REL_ "GenSigTimeoutTime" BU_SG_REL_ OCU SG_ 1411 ZV_HFS_offen 2000;
BA_REL_ "GenSigTimeoutTime" BU_SG_REL_ OCU SG_ 1411 ZV_HBFS_offen 2000;
BA_REL_ "GenSigTimeoutTime" BU_SG_REL_ OCU SG_ 1411 ZV_HD_offen 2000;
BA_REL_ "GenSigTimeoutTime" BU_SG_REL_ OCU SG_ 1411 DWA_aktiv 2000;
BA_REL_ "GenSigTimeoutTime" BU_SG_REL_ OCU SG_ 1411 HD_Hauptraste 2000;
BA_REL_ "GenSigTimeoutTime" BU_SG_REL_ OCU SG_ 1411 ZV_Schluessel_Zugang 2000;
BA_REL_ "GenSigTimeoutTime" BU_SG_REL_ OCU SG_ 1411 HFS_verriegelt 2000;
BA_REL_ "GenSigTimeoutTime" BU_SG_REL_ OCU SG_ 1411 HFS_gesafet 2000;
BA_REL_ "GenSigTimeoutTime" BU_SG_REL_ OCU SG_ 1411 HBFS_verriegelt 2000;
BA_REL_ "GenSigTimeoutTime" BU_SG_REL_ OCU SG_ 1411 HBFS_gesafet 2000;
BA_REL_ "GenSigTimeoutTime" BU_SG_REL_ OCU SG_ 1411 ZV_Tankklappe_offen 2000;
BA_REL_ "GenSigTimeoutTime" BU_SG_REL_ OCU SG_ 1411 ZV_Rollo_auf 2000;
BA_REL_ "GenSigTimeoutTime" BU_SG_REL_ OCU SG_ 1411 ZV_Rollo_zu 2000;
BA_REL_ "GenSigTimeoutTime" BU_SG_REL_ OCU SG_ 1411 BCM_Tankklappensteller_Fehler 2000;
BA_REL_ "GenSigTimeoutTime" BU_SG_REL_ OCU SG_ 1411 ZV_verriegelt_soll 2000;
BA_REL_ "GenSigTimeoutTime" BU_SG_REL_ ZR_MIB_EINSTIEG_ab_Gen3 SG_ 1716 VIN_01_MUX 2000;
BA_REL_ "GenSigTimeoutTime" BU_SG_REL_ ZR_MIB_EINSTIEG_ab_Gen3 SG_ 1716 KS_Geheimnis_1 2000;
BA_REL_ "GenSigTimeoutTime" BU_SG_REL_ ZR_MIB_EINSTIEG_ab_Gen3 SG_ 1716 VIN_4 2000;
BA_REL_ "GenSigTimeoutTime" BU_SG_REL_ ZR_MIB_EINSTIEG_ab_Gen3 SG_ 1716 VIN_11 2000;
BA_REL_ "GenSigTimeoutTime" BU_SG_REL_ ZR_MIB_EINSTIEG_ab_Gen3 SG_ 1716 KS_Geheimnis_2 2000;
BA_REL_ "GenSigTimeoutTime" BU_SG_REL_ ZR_MIB_EINSTIEG_ab_Gen3 SG_ 1716 VIN_5 2000;
BA_REL_ "GenSigTimeoutTime" BU_SG_REL_ ZR_MIB_EINSTIEG_ab_Gen3 SG_ 1716 VIN_12 2000;
BA_REL_ "GenSigTimeoutTime" BU_SG_REL_ ZR_MIB_EINSTIEG_ab_Gen3 SG_ 1716 KS_Geheimnis_3 2000;
BA_REL_ "GenSigTimeoutTime" BU_SG_REL_ ZR_MIB_EINSTIEG_ab_Gen3 SG_ 1716 VIN_6 2000;
BA_REL_ "GenSigTimeoutTime" BU_SG_REL_ ZR_MIB_EINSTIEG_ab_Gen3 SG_ 1716 VIN_13 2000;
BA_REL_ "GenSigTimeoutTime" BU_SG_REL_ ZR_MIB_EINSTIEG_ab_Gen3 SG_ 1716 KS_Geheimnis_4 2000;
BA_REL_ "GenSigTimeoutTime" BU_SG_REL_ ZR_MIB_EINSTIEG_ab_Gen3 SG_ 1716 VIN_7 2000;
BA_REL_ "GenSigTimeoutTime" BU_SG_REL_ ZR_MIB_EINSTIEG_ab_Gen3 SG_ 1716 VIN_14 2000;
BA_REL_ "GenSigTimeoutTime" BU_SG_REL_ ZR_MIB_EINSTIEG_ab_Gen3 SG_ 1716 VIN_1 2000;
BA_REL_ "GenSigTimeoutTime" BU_SG_REL_ ZR_MIB_EINSTIEG_ab_Gen3 SG_ 1716 VIN_8 2000;
BA_REL_ "GenSigTimeoutTime" BU_SG_REL_ ZR_MIB_EINSTIEG_ab_Gen3 SG_ 1716 VIN_15 2000;
BA_REL_ "GenSigTimeoutTime" BU_SG_REL_ ZR_MIB_EINSTIEG_ab_Gen3 SG_ 1716 VIN_2 2000;
BA_REL_ "GenSigTimeoutTime" BU_SG_REL_ ZR_MIB_EINSTIEG_ab_Gen3 SG_ 1716 VIN_9 2000;
BA_REL_ "GenSigTimeoutTime" BU_SG_REL_ ZR_MIB_EINSTIEG_ab_Gen3 SG_ 1716 VIN_16 2000;
BA_REL_ "GenSigTimeoutTime" BU_SG_REL_ ZR_MIB_EINSTIEG_ab_Gen3 SG_ 1716 VIN_3 2000;
BA_REL_ "GenSigTimeoutTime" BU_SG_REL_ ZR_MIB_EINSTIEG_ab_Gen3 SG_ 1716 VIN_10 2000;
BA_REL_ "GenSigTimeoutTime" BU_SG_REL_ ZR_MIB_EINSTIEG_ab_Gen3 SG_ 1716 VIN_17 2000;
BA_REL_ "GenSigTimeoutTime" BU_SG_REL_ ZR_MIB_EINSTIEG_ab_Gen3 SG_ 916 WBA_Fahrstufe_02 1600;
BA_REL_ "GenSigTimeoutTime" BU_SG_REL_ ZR_MIB_EINSTIEG_ab_Gen3 SG_ 916 WBA_eing_Gang_02 1600;
BA_REL_ "GenSigTimeoutTime" BU_SG_REL_ ZR_MIB_EINSTIEG_ab_Gen3 SG_ 916 WBA_Segeln_aktiv 1600;
BA_REL_ "GenSigTimeoutTime" BU_SG_REL_ ZR_MIB_EINSTIEG_ab_Gen3 SG_ 916 GE_Sollgang 1600;
BA_REL_ "GenSigTimeoutTime" BU_SG_REL_ ZR_MIB_EINSTIEG_ab_Gen3 SG_ 1361 WFS_Schluessel_Fahrberecht 2000;
BA_REL_ "GenSigTimeoutTime" BU_SG_REL_ ZR_MIB_EINSTIEG_ab_Gen3 SG_ 1361 WFS_Schluessel_Soll 2000;
BA_REL_ "GenSigTimeoutTime" BU_SG_REL_ ZR_MIB_EINSTIEG_ab_Gen3 SG_ 1361 WFS_Schluessel_Ist 2000;
BA_REL_ "GenSigTimeoutTime" BU_SG_REL_ ZR_MIB_EINSTIEG_ab_Gen3 SG_ 2589283611 WLC1_Charger_Effizienz 5000;
BA_REL_ "GenSigTimeoutTime" BU_SG_REL_ ZR_MIB_EINSTIEG_ab_Gen3 SG_ 2589283611 WLC1_Charger_laedt 5000;
BA_REL_ "GenSigTimeoutTime" BU_SG_REL_ ZR_MIB_EINSTIEG_ab_Gen3 SG_ 2589283611 WLC1_Fremdobjekt_erkannt 5000;
BA_REL_ "GenSigTimeoutTime" BU_SG_REL_ ZR_MIB_EINSTIEG_ab_Gen3 SG_ 2589283611 WLC1_Leistungsklasse_Receiver 5000;
BA_REL_ "GenSigTimeoutTime" BU_SG_REL_ ZR_MIB_EINSTIEG_ab_Gen3 SG_ 2589283611 WLC1_Objekt_erkannt 5000;
BA_REL_ "GenSigTimeoutTime" BU_SG_REL_ ZR_MIB_EINSTIEG_ab_Gen3 SG_ 2589283611 WLC1_Receiver_erkannt 5000;
BA_REL_ "GenSigTimeoutTime" BU_SG_REL_ ZR_MIB_EINSTIEG_ab_Gen3 SG_ 2589283611 WLC1_Receiver_voll_geladen 5000;
BA_REL_ "GenSigTimeoutTime" BU_SG_REL_ ZR_MIB_EINSTIEG_ab_Gen3 SG_ 2589283611 WLC1_verwendeter_Ladestandard 5000;
BA_REL_ "GenSigTimeoutTime" BU_SG_REL_ ZR_MIB_EINSTIEG_ab_Gen3 SG_ 2589283611 WLC1_Temp_Leistungsteil_Charger 5000;
BA_REL_ "GenSigTimeoutTime" BU_SG_REL_ ZR_MIB_EINSTIEG_ab_Gen3 SG_ 2589283611 WLC1_Temp_Oberfaeche_Charger 5000;
BA_REL_ "GenSigTimeoutTime" BU_SG_REL_ ZR_MIB_EINSTIEG_ab_Gen3 SG_ 2589283611 WLC1_Temp_Receiver 5000;
BA_REL_ "GenSigTimeoutTime" BU_SG_REL_ ZR_MIB_EINSTIEG_ab_Gen3 SG_ 2527679836 WLC1_ChargingStatus 5000;
BA_REL_ "GenSigTimeoutTime" BU_SG_REL_ ZR_MIB_EINSTIEG_ab_Gen3 SG_ 2527679836 WLC1_ChargingEfficiency 5000;
BA_REL_ "GenSigTimeoutTime" BU_SG_REL_ ZR_MIB_EINSTIEG_ab_Gen3 SG_ 2527679836 WLC1_UsedChargingStandard 5000;
BA_REL_ "GenSigTimeoutTime" BU_SG_REL_ ZR_MIB_EINSTIEG_ab_Gen3 SG_ 2527679837 WLC2_ChargingStatus 5000;
BA_REL_ "GenSigTimeoutTime" BU_SG_REL_ ZR_MIB_EINSTIEG_ab_Gen3 SG_ 2527679837 WLC2_ChargingEfficiency 5000;
BA_REL_ "GenSigTimeoutTime" BU_SG_REL_ ZR_MIB_EINSTIEG_ab_Gen3 SG_ 2527679837 WLC2_UsedChargingStandard 5000;
BA_REL_ "GenSigTimeoutTime" BU_SG_REL_ ZR_MIB_EINSTIEG_ab_Gen3 SG_ 1411 ZV_verriegelt_extern_soll 2000;
BA_REL_ "GenSigTimeoutTime" BU_SG_REL_ ZR_MIB_EINSTIEG_ab_Gen3 SG_ 1411 ZV_FT_offen 2000;
BA_REL_ "GenSigTimeoutTime" BU_SG_REL_ ZR_MIB_EINSTIEG_ab_Gen3 SG_ 1411 ZV_BT_offen 2000;
BA_REL_ "GenSigTimeoutTime" BU_SG_REL_ ZR_MIB_EINSTIEG_ab_Gen3 SG_ 1411 ZV_HFS_offen 2000;
BA_REL_ "GenSigTimeoutTime" BU_SG_REL_ ZR_MIB_EINSTIEG_ab_Gen3 SG_ 1411 ZV_HBFS_offen 2000;
BA_REL_ "GenSigTimeoutTime" BU_SG_REL_ ZR_MIB_EINSTIEG_ab_Gen3 SG_ 1411 ZV_HD_offen 2000;
BA_REL_ "GenSigTimeoutTime" BU_SG_REL_ ZR_MIB_OPTION_ab_Gen3 SG_ 1716 VIN_01_MUX 2000;
BA_REL_ "GenSigTimeoutTime" BU_SG_REL_ ZR_MIB_OPTION_ab_Gen3 SG_ 1716 KS_Geheimnis_1 2000;
BA_REL_ "GenSigTimeoutTime" BU_SG_REL_ ZR_MIB_OPTION_ab_Gen3 SG_ 1716 VIN_4 2000;
BA_REL_ "GenSigTimeoutTime" BU_SG_REL_ ZR_MIB_OPTION_ab_Gen3 SG_ 1716 VIN_11 2000;
BA_REL_ "GenSigTimeoutTime" BU_SG_REL_ ZR_MIB_OPTION_ab_Gen3 SG_ 1716 KS_Geheimnis_2 2000;
BA_REL_ "GenSigTimeoutTime" BU_SG_REL_ ZR_MIB_OPTION_ab_Gen3 SG_ 1716 VIN_5 2000;
BA_REL_ "GenSigTimeoutTime" BU_SG_REL_ ZR_MIB_OPTION_ab_Gen3 SG_ 1716 VIN_12 2000;
BA_REL_ "GenSigTimeoutTime" BU_SG_REL_ ZR_MIB_OPTION_ab_Gen3 SG_ 1716 KS_Geheimnis_3 2000;
BA_REL_ "GenSigTimeoutTime" BU_SG_REL_ ZR_MIB_OPTION_ab_Gen3 SG_ 1716 VIN_6 2000;
BA_REL_ "GenSigTimeoutTime" BU_SG_REL_ ZR_MIB_OPTION_ab_Gen3 SG_ 1716 VIN_13 2000;
BA_REL_ "GenSigTimeoutTime" BU_SG_REL_ ZR_MIB_OPTION_ab_Gen3 SG_ 1716 KS_Geheimnis_4 2000;
BA_REL_ "GenSigTimeoutTime" BU_SG_REL_ ZR_MIB_OPTION_ab_Gen3 SG_ 1716 VIN_7 2000;
BA_REL_ "GenSigTimeoutTime" BU_SG_REL_ ZR_MIB_OPTION_ab_Gen3 SG_ 1716 VIN_14 2000;
BA_REL_ "GenSigTimeoutTime" BU_SG_REL_ ZR_MIB_OPTION_ab_Gen3 SG_ 1716 VIN_1 2000;
BA_REL_ "GenSigTimeoutTime" BU_SG_REL_ ZR_MIB_OPTION_ab_Gen3 SG_ 1716 VIN_8 2000;
BA_REL_ "GenSigTimeoutTime" BU_SG_REL_ ZR_MIB_OPTION_ab_Gen3 SG_ 1716 VIN_15 2000;
BA_REL_ "GenSigTimeoutTime" BU_SG_REL_ ZR_MIB_OPTION_ab_Gen3 SG_ 1716 VIN_2 2000;
BA_REL_ "GenSigTimeoutTime" BU_SG_REL_ ZR_MIB_OPTION_ab_Gen3 SG_ 1716 VIN_9 2000;
BA_REL_ "GenSigTimeoutTime" BU_SG_REL_ ZR_MIB_OPTION_ab_Gen3 SG_ 1716 VIN_16 2000;
BA_REL_ "GenSigTimeoutTime" BU_SG_REL_ ZR_MIB_OPTION_ab_Gen3 SG_ 1716 VIN_3 2000;
BA_REL_ "GenSigTimeoutTime" BU_SG_REL_ ZR_MIB_OPTION_ab_Gen3 SG_ 1716 VIN_10 2000;
BA_REL_ "GenSigTimeoutTime" BU_SG_REL_ ZR_MIB_OPTION_ab_Gen3 SG_ 1716 VIN_17 2000;
BA_REL_ "GenSigTimeoutTime" BU_SG_REL_ ZR_MIB_OPTION_ab_Gen3 SG_ 916 WBA_Fahrstufe_02 1600;
BA_REL_ "GenSigTimeoutTime" BU_SG_REL_ ZR_MIB_OPTION_ab_Gen3 SG_ 916 WBA_eing_Gang_02 1600;
BA_REL_ "GenSigTimeoutTime" BU_SG_REL_ ZR_MIB_OPTION_ab_Gen3 SG_ 916 WBA_Segeln_aktiv 1600;
BA_REL_ "GenSigTimeoutTime" BU_SG_REL_ ZR_MIB_OPTION_ab_Gen3 SG_ 916 GE_Sollgang 1600;
BA_REL_ "GenSigTimeoutTime" BU_SG_REL_ ZR_MIB_OPTION_ab_Gen3 SG_ 916 GE_Tipschaltempf_verfuegbar 1600;
BA_REL_ "GenSigTimeoutTime" BU_SG_REL_ ZR_MIB_OPTION_ab_Gen3 SG_ 2589283611 WLC1_Charger_Effizienz 5000;
BA_REL_ "GenSigTimeoutTime" BU_SG_REL_ ZR_MIB_OPTION_ab_Gen3 SG_ 2589283611 WLC1_Charger_laedt 5000;
BA_REL_ "GenSigTimeoutTime" BU_SG_REL_ ZR_MIB_OPTION_ab_Gen3 SG_ 2589283611 WLC1_Fremdobjekt_erkannt 5000;
BA_REL_ "GenSigTimeoutTime" BU_SG_REL_ ZR_MIB_OPTION_ab_Gen3 SG_ 2589283611 WLC1_Leistungsklasse_Receiver 5000;
BA_REL_ "GenSigTimeoutTime" BU_SG_REL_ ZR_MIB_OPTION_ab_Gen3 SG_ 2589283611 WLC1_Objekt_erkannt 5000;
BA_REL_ "GenSigTimeoutTime" BU_SG_REL_ ZR_MIB_OPTION_ab_Gen3 SG_ 2589283611 WLC1_Receiver_erkannt 5000;
BA_REL_ "GenSigTimeoutTime" BU_SG_REL_ ZR_MIB_OPTION_ab_Gen3 SG_ 2589283611 WLC1_Receiver_voll_geladen 5000;
BA_REL_ "GenSigTimeoutTime" BU_SG_REL_ ZR_MIB_OPTION_ab_Gen3 SG_ 2589283611 WLC1_verwendeter_Ladestandard 5000;
BA_REL_ "GenSigTimeoutTime" BU_SG_REL_ ZR_MIB_OPTION_ab_Gen3 SG_ 2589283611 WLC1_Temp_Leistungsteil_Charger 5000;
BA_REL_ "GenSigTimeoutTime" BU_SG_REL_ ZR_MIB_OPTION_ab_Gen3 SG_ 2589283611 WLC1_Temp_Oberfaeche_Charger 5000;
BA_REL_ "GenSigTimeoutTime" BU_SG_REL_ ZR_MIB_OPTION_ab_Gen3 SG_ 2589283611 WLC1_Temp_Receiver 5000;
BA_REL_ "GenSigTimeoutTime" BU_SG_REL_ ZR_MIB_OPTION_ab_Gen3 SG_ 2527679836 WLC1_ChargingStatus 5000;
BA_REL_ "GenSigTimeoutTime" BU_SG_REL_ ZR_MIB_OPTION_ab_Gen3 SG_ 2527679836 WLC1_ChargingEfficiency 5000;
BA_REL_ "GenSigTimeoutTime" BU_SG_REL_ ZR_MIB_OPTION_ab_Gen3 SG_ 2527679836 WLC1_UsedChargingStandard 5000;
BA_REL_ "GenSigTimeoutTime" BU_SG_REL_ ZR_MIB_OPTION_ab_Gen3 SG_ 2527679837 WLC2_ChargingStatus 5000;
BA_REL_ "GenSigTimeoutTime" BU_SG_REL_ ZR_MIB_OPTION_ab_Gen3 SG_ 2527679837 WLC2_ChargingEfficiency 5000;
BA_REL_ "GenSigTimeoutTime" BU_SG_REL_ ZR_MIB_OPTION_ab_Gen3 SG_ 2527679837 WLC2_UsedChargingStandard 5000;
BA_REL_ "GenSigTimeoutTime" BU_SG_REL_ ZR_MIB_OPTION_ab_Gen3 SG_ 1411 ZV_verriegelt_extern_soll 2000;
BA_REL_ "GenSigTimeoutTime" BU_SG_REL_ ZR_MIB_OPTION_ab_Gen3 SG_ 1411 ZV_FT_offen 2000;
BA_REL_ "GenSigTimeoutTime" BU_SG_REL_ ZR_MIB_OPTION_ab_Gen3 SG_ 1411 ZV_BT_offen 2000;
BA_REL_ "GenSigTimeoutTime" BU_SG_REL_ ZR_MIB_OPTION_ab_Gen3 SG_ 1411 ZV_HFS_offen 2000;
BA_REL_ "GenSigTimeoutTime" BU_SG_REL_ ZR_MIB_OPTION_ab_Gen3 SG_ 1411 ZV_HBFS_offen 2000;
BA_REL_ "GenSigTimeoutTime" BU_SG_REL_ ZR_MIB_OPTION_ab_Gen3 SG_ 1411 ZV_HD_offen 2000;
BA_REL_ "GenSigTimeoutTime" BU_SG_REL_ ZR_MIB_TOP_ab_Gen3 SG_ 975 HBFS_Tuer_geoeffnet 1000;
BA_REL_ "GenSigTimeoutTime" BU_SG_REL_ ZR_MIB_TOP_ab_Gen3 SG_ 975 HBFS_FH_Oeffnung 1000;
BA_REL_ "GenSigTimeoutTime" BU_SG_REL_ ZR_MIB_TOP_ab_Gen3 SG_ 974 HFS_Tuer_geoeffnet 1000;
BA_REL_ "GenSigTimeoutTime" BU_SG_REL_ ZR_MIB_TOP_ab_Gen3 SG_ 974 HFS_FH_Oeffnung 1000;
BA_REL_ "GenSigTimeoutTime" BU_SG_REL_ ZR_MIB_TOP_ab_Gen3 SG_ 995 VS_VD_zu_ver 1000;
BA_REL_ "GenSigTimeoutTime" BU_SG_REL_ ZR_MIB_TOP_ab_Gen3 SG_ 995 VS_VD_offen_ver 1000;
BA_REL_ "GenSigTimeoutTime" BU_SG_REL_ ZR_MIB_TOP_ab_Gen3 SG_ 1716 VIN_01_MUX 2000;
BA_REL_ "GenSigTimeoutTime" BU_SG_REL_ ZR_MIB_TOP_ab_Gen3 SG_ 1716 VIN_4 2000;
BA_REL_ "GenSigTimeoutTime" BU_SG_REL_ ZR_MIB_TOP_ab_Gen3 SG_ 1716 VIN_11 2000;
BA_REL_ "GenSigTimeoutTime" BU_SG_REL_ ZR_MIB_TOP_ab_Gen3 SG_ 1716 VIN_5 2000;
BA_REL_ "GenSigTimeoutTime" BU_SG_REL_ ZR_MIB_TOP_ab_Gen3 SG_ 1716 VIN_12 2000;
BA_REL_ "GenSigTimeoutTime" BU_SG_REL_ ZR_MIB_TOP_ab_Gen3 SG_ 1716 VIN_6 2000;
BA_REL_ "GenSigTimeoutTime" BU_SG_REL_ ZR_MIB_TOP_ab_Gen3 SG_ 1716 VIN_13 2000;
BA_REL_ "GenSigTimeoutTime" BU_SG_REL_ ZR_MIB_TOP_ab_Gen3 SG_ 1716 VIN_7 2000;
BA_REL_ "GenSigTimeoutTime" BU_SG_REL_ ZR_MIB_TOP_ab_Gen3 SG_ 1716 VIN_14 2000;
BA_REL_ "GenSigTimeoutTime" BU_SG_REL_ ZR_MIB_TOP_ab_Gen3 SG_ 1716 VIN_1 2000;
BA_REL_ "GenSigTimeoutTime" BU_SG_REL_ ZR_MIB_TOP_ab_Gen3 SG_ 1716 VIN_8 2000;
BA_REL_ "GenSigTimeoutTime" BU_SG_REL_ ZR_MIB_TOP_ab_Gen3 SG_ 1716 VIN_15 2000;
BA_REL_ "GenSigTimeoutTime" BU_SG_REL_ ZR_MIB_TOP_ab_Gen3 SG_ 1716 VIN_2 2000;
BA_REL_ "GenSigTimeoutTime" BU_SG_REL_ ZR_MIB_TOP_ab_Gen3 SG_ 1716 VIN_9 2000;
BA_REL_ "GenSigTimeoutTime" BU_SG_REL_ ZR_MIB_TOP_ab_Gen3 SG_ 1716 VIN_16 2000;
BA_REL_ "GenSigTimeoutTime" BU_SG_REL_ ZR_MIB_TOP_ab_Gen3 SG_ 1716 VIN_3 2000;
BA_REL_ "GenSigTimeoutTime" BU_SG_REL_ ZR_MIB_TOP_ab_Gen3 SG_ 1716 VIN_10 2000;
BA_REL_ "GenSigTimeoutTime" BU_SG_REL_ ZR_MIB_TOP_ab_Gen3 SG_ 1716 VIN_17 2000;
BA_REL_ "GenSigTimeoutTime" BU_SG_REL_ ZR_MIB_TOP_ab_Gen3 SG_ 916 WBA_Fahrstufe_02 1600;
BA_REL_ "GenSigTimeoutTime" BU_SG_REL_ ZR_MIB_TOP_ab_Gen3 SG_ 916 WBA_eing_Gang_02 1600;
BA_REL_ "GenSigTimeoutTime" BU_SG_REL_ ZR_MIB_TOP_ab_Gen3 SG_ 916 WBA_Segeln_aktiv 1600;
BA_REL_ "GenSigTimeoutTime" BU_SG_REL_ ZR_MIB_TOP_ab_Gen3 SG_ 916 WBA_GE_Zusatzwarnungen 1600;
BA_REL_ "GenSigTimeoutTime" BU_SG_REL_ ZR_MIB_TOP_ab_Gen3 SG_ 916 GE_Sollgang 1600;
BA_REL_ "GenSigTimeoutTime" BU_SG_REL_ ZR_MIB_TOP_ab_Gen3 SG_ 1361 WFS_Schluessel_Soll 2000;
BA_REL_ "GenSigTimeoutTime" BU_SG_REL_ ZR_MIB_TOP_ab_Gen3 SG_ 1361 WFS_Schluessel_Ist 2000;
BA_REL_ "GenSigTimeoutTime" BU_SG_REL_ ZR_MIB_TOP_ab_Gen3 SG_ 2527679836 WLC1_ChargingStatus 5000;
BA_REL_ "GenSigTimeoutTime" BU_SG_REL_ ZR_MIB_TOP_ab_Gen3 SG_ 2527679836 WLC1_ChargingEfficiency 5000;
BA_REL_ "GenSigTimeoutTime" BU_SG_REL_ ZR_MIB_TOP_ab_Gen3 SG_ 2527679836 WLC1_UsedChargingStandard 5000;
BA_REL_ "GenSigTimeoutTime" BU_SG_REL_ ZR_MIB_TOP_ab_Gen3 SG_ 1411 ZV_verriegelt_extern_soll 2000;
BA_REL_ "GenSigTimeoutTime" BU_SG_REL_ ZR_MIB_TOP_ab_Gen3 SG_ 1411 ZV_FT_offen 2000;
BA_REL_ "GenSigTimeoutTime" BU_SG_REL_ ZR_MIB_TOP_ab_Gen3 SG_ 1411 ZV_BT_offen 2000;
BA_REL_ "GenSigTimeoutTime" BU_SG_REL_ ZR_MIB_TOP_ab_Gen3 SG_ 1411 ZV_HFS_offen 2000;
BA_REL_ "GenSigTimeoutTime" BU_SG_REL_ ZR_MIB_TOP_ab_Gen3 SG_ 1411 ZV_HBFS_offen 2000;
BA_REL_ "GenSigTimeoutTime" BU_SG_REL_ ZR_MIB_TOP_ab_Gen3 SG_ 1411 ZV_HD_offen 2000;
VAL_ 975 HBFS_Tuer_geoeffnet 0 "geschlossen" 1 "offen" ;
VAL_ 975 HBFS_verriegelt 0 "nicht_verriegelt" 1 "verriegelt" ;
VAL_ 975 HBFS_gesafet 0 "nicht_gesafet" 1 "gesafet" ;
VAL_ 975 HBFS_Heckrollotaster_betaetigt 0 "keine_Verfahranweisung_in_Richtung_Hoch" 1 "In_Richtung_Hoch_Verfahren" ;
VAL_ 975 HBFS_Tuerschloss_defekt 0 "Tuerschloss_funktionsfaehig" 1 "Tuerschloss_defekt" ;
VAL_ 975 HBFS_Unlock_Taster 0 "nicht_betaetigt" 1 "betaetigt" ;
VAL_ 975 HBFS_Lock_Taster 0 "nicht_betaetigt" 1 "betaetigt" ;
VAL_ 975 HBFS_Sperrklinke 0 "Schloss_in_Vorraste_und_Hauptraste" 1 "Tuer_auf_oder_Tuer_Position_zwischen_Vor_und_Hauptraste" ;
VAL_ 975 HBFS_TAG_betaetigt 0 "nicht_betaetigt" 1 "betaetigt" ;
VAL_ 975 HBFS_TIG_betaetigt 0 "nicht_betaetigt" 1 "betaetigt" ;
VAL_ 975 HBFS_FH_S_HFS_AutoHoch 0 "keine_Bedienung" 1 "Automatiklauf_Angefordert" ;
VAL_ 975 HBFS_FH_S_HFS_AutoTief 0 "keine_Bedienung" 1 "Automatiklauf_Angefordert" ;
VAL_ 975 HBFS_FH_S_HFS_ManHoch 0 "keine_Bedienung" 1 "Manueller_Lauf_Angefordert" ;
VAL_ 975 HBFS_FH_S_HFS_ManTief 0 "keine_Bedienung" 1 "Manueller_Lauf_Angefordert" ;
VAL_ 975 HBFS_Tuer_Status 0 "Init" 1 "Tuer_geschlossen" 2 "Tuer_offen" 3 "Fehler" ;
VAL_ 975 HBFS_SAD_Schalter 0 "nicht_betaetigt" 5 "AUF_manuell" 6 "AUF_automatik" 7 "ZU_manuell" 8 "ZU_automatik" 13 "nicht_verfuegbar" 14 "Init" 15 "Fehler" ;
VAL_ 975 HBFS_FH_S_ManHoch 0 "nicht_betaetigt" 1 "betaetigt" ;
VAL_ 975 HBFS_FH_S_AutoHoch 0 "nicht_betaetigt" 1 "betaetigt" ;
VAL_ 975 HBFS_FH_S_ManTief 0 "nicht_betaetigt" 1 "betaetigt" ;
VAL_ 975 HBFS_FH_S_AutoTief 0 "nicht_betaetigt" 1 "betaetigt" ;
VAL_ 975 HBFS_FH_Bew_hoch 0 "inaktiv" 1 "aktiv" ;
VAL_ 975 HBFS_FH_Bew_tief 0 "inaktiv" 1 "aktiv" ;
VAL_ 975 HBFS_FH_Fang 0 "ausserhalb_Fangbereich" 1 "innerhalb_Fangbereich" ;
VAL_ 975 HBFS_FH_Block 0 "inaktiv" 1 "aktiv" ;
VAL_ 975 HBFS_FH_Thermo 0 "inaktiv" 1 "aktiv" ;
VAL_ 975 HBFS_UEKB_aktiviert 0 "inaktiv" 1 "aktiv" ;
VAL_ 975 HBFS_Tueroeffnen_Warnung 0 "Tuerwarnung_nicht_aktiv" 1 "Tuerwarnung_aktiv" ;
VAL_ 975 HBFS_FH_normiert 0 "inaktiv" 1 "aktiv" ;
VAL_ 975 ASW_Warnung_aktiv_HBFS 0 "nicht_angefordert" 1 "angefordert" ;
VAL_ 975 HBFS_Zuziehhilfe_aktiv 0 "Init" 1 "Zuziehhilfe_aktiv" ;
VAL_ 975 HBFS_Seitenrollo_hoch 1 "Seitenrollo_in_Bewegung_hoch" ;
VAL_ 975 HBFS_Seitenrollo_tief 0 "Init" 1 "Seitenrollo_in_Bewegung_tief" ;
VAL_ 975 HBFS_Status_KiSi 0 "inaktiv" 1 "aktiv" ;
VAL_ 975 SSR_HBFS_Pos_Unten 0 "SSR_Oben" 1 "SSR_Unten" ;
VAL_ 975 HBFS_Oben_Block_erw 0 "Fensterheber_nicht_in_Blockerwar" 1 "Fensterheber_in_Blockerwartung_o" ;
VAL_ 975 HBFS_Unten_Block_erw 0 "Fensterheber_nicht_in_Blockerwar" 1 "Fensterheber_in_Blockerwartung_u" ;
VAL_ 975 MTHBFS_M_Taste 0 "nicht_betaetigt" 1 "betaetigt" ;
VAL_ 975 MTHBFS_Pos1 0 "nicht_betaetigt" 1 "betaetigt" ;
VAL_ 975 MTHBFS_Pos2 0 "nicht_betaetigt" 1 "betaetigt" ;
VAL_ 975 MTHBFS_Pos3 0 "nicht_betaetigt" 1 "betaetigt" ;
VAL_ 975 HBFS_MRollo_Schalter 0 "nicht_betaetigt" 1 "ZU_manuell" 2 "ZU_automatik" 3 "AUF_manuell" 4 "AUF_automatik" 5 "nicht_verfuegbar" 6 "Init" 7 "Fehler" ;
VAL_ 975 HBFS_Lock_Taster_inv 0 "Lock Taster betätgit" 1 "Lock Taster nicht betätigt" ;
VAL_ 975 HBFS_Status_KiSi_inv 0 "aktiv" 1 "inaktiv" ;
VAL_ 975 HBFS_Status_eTAG 0 "Init" 1 "Griff_ausgefahren" 2 "Griff_eingefahren" 3 "Fehler" ;
VAL_ 975 HBFS_Tuer_Status_QBit 0 "Status_Tuerkontakt_sicher" 1 "Status_Tuerkontakt_unsicher" ;
VAL_ 975 HBFS_TIG_betaetigt_schliessen 0 "nicht_betaetigt" 1 "betaetigt" ;
VAL_ 975 HBFS_TIG_betaetigt_oeffnen 0 "nicht_betaetigt" 1 "betaetigt" ;
VAL_ 975 HBFS_Vorraste_betaetigt 0 "nicht_in_Vorraste" 1 "in_Vorraste" ;
VAL_ 975 HBFS_SK_betaetigt 0 "ausgehoben" 1 "eingefallen" ;
VAL_ 974 HFS_Tuer_geoeffnet 0 "geschlossen" 1 "offen" ;
VAL_ 974 HFS_verriegelt 0 "nicht_verriegelt" 1 "verriegelt" ;
VAL_ 974 HFS_gesafet 0 "nicht_gesafet" 1 "gesafet" ;
VAL_ 974 HFS_Heckrollotaster_betaetigt 0 "keine_Verfahranweisung_in_Richtung_Hoch" 1 "In_Richtung_Hoch_Verfahren" ;
VAL_ 974 HFS_Tuerschloss_defekt 0 "Tuerschloss_funktionsfaehig" 1 "Tuerschloss_defekt" ;
VAL_ 974 HFS_Unlock_Taster 0 "nicht_betaetigt" 1 "betaetigt" ;
VAL_ 974 HFS_Lock_Taster 0 "nicht_betaetigt" 1 "betaetigt" ;
VAL_ 974 HFS_Sperrklinke 0 "Schloss_in_Vorraste_und_Hauptraste" 1 "Tuer_auf_oder_Tuer_Position_zwischen_Vor_und_Hauptraste" ;
VAL_ 974 HFS_TAG_betaetigt 0 "nicht_betaetigt" 1 "betaetigt" ;
VAL_ 974 HFS_TIG_betaetigt 0 "nicht_betaetigt" 1 "betaetigt" ;
VAL_ 974 HFS_FH_S_HBFS_AutoHoch 0 "keine_Bedienung" 1 "Automatiklauf_Angefordert" ;
VAL_ 974 HFS_FH_S_HBFS_AutoTief 0 "keine_Bedienung" 1 "Automatiklauf_Angefordert" ;
VAL_ 974 HFS_FH_S_HBFS_ManHoch 0 "keine_Bedienung" 1 "Manueller_Lauf_Angefordert" ;
VAL_ 974 HFS_FH_S_HBFS_ManTief 0 "keine_Bedienung" 1 "Manueller_Lauf_Angefordert" ;
VAL_ 974 HFS_Tuer_Status 0 "Init" 1 "Tuer_geschlossen" 2 "Tuer_offen" 3 "Fehler" ;
VAL_ 974 HFS_SAD_Schalter 0 "nicht_betaetigt" 5 "AUF_manuell" 6 "AUF_automatik" 7 "ZU_manuell" 8 "ZU_automatik" 13 "nicht_verfuegbar" 14 "Init" 15 "Fehler" ;
VAL_ 974 HFS_FH_S_ManHoch 0 "nicht_betaetigt" 1 "betaetigt" ;
VAL_ 974 HFS_FH_S_AutoHoch 0 "nicht_betaetigt" 1 "betaetigt" ;
VAL_ 974 HFS_FH_S_ManTief 0 "nicht_betaetigt" 1 "betaetigt" ;
VAL_ 974 HFS_FH_S_AutoTief 0 "nicht_betaetigt" 1 "betaetigt" ;
VAL_ 974 HFS_FH_Bew_hoch 0 "inaktiv" 1 "aktiv" ;
VAL_ 974 HFS_FH_Bew_tief 0 "inaktiv" 1 "aktiv" ;
VAL_ 974 HFS_FH_Fang 0 "ausserhalb_Fangbereich" 1 "innerhalb_Fangbereich" ;
VAL_ 974 HFS_FH_Block 0 "inaktiv" 1 "aktiv" ;
VAL_ 974 HFS_FH_Thermo 0 "inaktiv" 1 "aktiv" ;
VAL_ 974 HFS_UEKB_aktiviert 0 "inaktiv" 1 "aktiv" ;
VAL_ 974 HFS_Tueroeffnen_Warnung 0 "Tuerwarnung_nicht_aktiv" 1 "Tuerwarnung_aktiv" ;
VAL_ 974 HFS_FH_normiert 0 "inaktiv" 1 "aktiv" ;
VAL_ 974 ASW_Warnung_aktiv_HFS 0 "nicht_angefordert" 1 "angefordert" ;
VAL_ 974 HFS_Zuziehhilfe_aktiv 0 "Init" 1 "Zuziehhilfe_aktiv" ;
VAL_ 974 HFS_Seitenrollo_hoch 0 "Init" 1 "Seitenrollo_in_Bewegung_hoch" ;
VAL_ 974 HFS_Seitenrollo_tief 0 "Init" 1 "Seitenrollo_in_Bewegung_tief" ;
VAL_ 974 HFS_Status_KiSi 0 "inaktiv" 1 "aktiv" ;
VAL_ 974 SSR_HFS_Pos_Unten 0 "SSR_Oben" 1 "SSR_Unten" ;
VAL_ 974 HFS_Oben_Block_erw 0 "Fensterheber_nicht_in_Blockerwar" 1 "Fensterheber_in_Blockerwartung_o" ;
VAL_ 974 HFS_Unten_Block_erw 0 "Fensterheber_nicht_in_Blockerwar" 1 "Fensterheber_in_Blockerwartung_u" ;
VAL_ 974 MTHFS_M_Taste 0 "nicht_betaetigt" 1 "betaetigt" ;
VAL_ 974 MTHFS_Pos1 0 "nicht_betaetigt" 1 "betaetigt" ;
VAL_ 974 MTHFS_Pos2 0 "nicht_betaetigt" 1 "betaetigt" ;
VAL_ 974 MTHFS_Pos3 0 "nicht_betaetigt" 1 "betaetigt" ;
VAL_ 974 HFS_MRollo_Schalter 0 "nicht_betaetigt" 1 "ZU_manuell" 2 "ZU_automatik" 3 "AUF_manuell" 4 "AUF_automatik" 5 "nicht_verfuegbar" 6 "Init" 7 "Fehler" ;
VAL_ 974 HFS_Lock_Taster_inv 0 "Lock Taster betätgit" 1 "Lock Taster nicht betätigt" ;
VAL_ 974 HFS_Status_eTAG 0 "Init" 1 "Griff_ausgefahren" 2 "Griff_eingefahren" 3 "Fehler" ;
VAL_ 974 HFS_Tuer_Status_QBit 0 "Status_Tuerkontakt_sicher" 1 "Status_Tuerkontakt_unsicher" ;
VAL_ 974 HFS_TCR_Mode_aktiv 0 "TCR_Mode_deaktiv" 1 "TCR_Mode_aktiv" ;
VAL_ 974 HFS_TIG_betaetigt_schliessen 0 "nicht_betaetigt" 1 "betaetigt" ;
VAL_ 974 HFS_TIG_betaetigt_oeffnen 0 "nicht_betaetigt" 1 "betaetigt" ;
VAL_ 974 HFS_Vorraste_betaetigt 0 "nicht_in_Vorraste" 1 "in_Vorraste" ;
VAL_ 974 HFS_SK_betaetigt 0 "ausgehoben" 1 "eingefallen" ;
VAL_ 1718 UH_Typ 0 "undefiniert" 1 "Quarzuhr" 2 "DCF" 3 "GPS" ;
VAL_ 1718 UH_DLS 0 "Winterzeit" 1 "Sommerzeit" ;
VAL_ 1718 UH_Monat 0 "Init" 14 "Relatives_Datum" 15 "Fehler" ;
VAL_ 1718 UH_Tag 0 "Init" ;
VAL_ 2463978710 OPS_ComfortReadyStatus 0 "Init" 1 "aktiv" 2 "inaktiv" 3 "Fehler" ;
VAL_ 2463978710 OPS_OccupantPresenceStatus 0 "Init" 1 "OccupantAbsent" 2 "reserviert" 3 "OccupantEntryExit" 4 "reserviert" 5 "OccupantPresent" 6 "OccupantPresentVerified" 7 "Fehler" ;
VAL_ 2463978710 OPS_DriverPresenceStatus 0 "Init" 1 "reserviert" 2 "DriverAbsent" 3 "reserviert" 4 "DriverEntry" 5 "reserviert" 6 "DriverPresent" 7 "reserviert" 8 "DriverPresentVerified" 9 "reserviert" 10 "reserviert" 11 "DriverExitIntent" 12 "reserviert" 13 "DriverExit" 14 "reserviert" 15 "Fehler" ;
VAL_ 2463978710 OPS_QBit_DriverPresence 0 "gueltiger_Wert" 1 "Ersatz_Init_oder_Fehlerwert" ;
VAL_ 2463978710 OPS_SafeDriverPresenceStatus 0 "Init" 1 "Driver_Safe_Present" 2 "Driver_Not_Safe_Present" 3 "Fehler" ;
VAL_ 2463978710 OPS_SafeDriverPresence_available 0 "Verfuegbar" 1 "Verfuegbar_eingeschr_Performance" ;
VAL_ 995 VS_VD_zu_ver 1 "Zustand des Verdecks verriegelt und geschlossen" ;
VAL_ 995 VS_VD_entriegelt 0 "Init" 1 "Zustand_des_Verdeck_entriegelt" ;
VAL_ 995 VS_VD_offen_ver 0 "Init" 1 "Verdeck_verriegelt_und_offen" ;
VAL_ 995 VS_VD_Zwischenposition 0 "Init" 1 "Verdeck_in_Zwischenposition" ;
VAL_ 995 VS_VD_Bew_auf 1 "Verdeck in Bewegung auf" ;
VAL_ 995 VS_VD_Bew_zu 1 "Verdeck in Bewegung zu" ;
VAL_ 995 VS_Verdeck_Anf 0 "init_nicht_aktiv" 1 "aktiv" ;
VAL_ 995 VS_Hardtop 0 "Init" 1 "Hardtop_montiert" ;
VAL_ 995 VS_VD_Fehler 0 "Init" 1 "Fehlerzustand Verdeck" ;
VAL_ 995 VS_Lampe_Blk 0 "Kontrollleuchte_inaktiv" 1 "Kontrollleuchte_aktiv" ;
VAL_ 995 VS_HD_sperren 0 "HD Entriegelung freigegeben" 1 "HD Entriegelung gesperrt" ;
VAL_ 995 VS_HHS_enable 0 "Init" 1 "Freigabe HHS" ;
VAL_ 995 VD_SpannungsAnf 0 "keine_Anforderung" 1 "Anforderung_Stufe1" 2 "Anforderung_Stufe2" 3 "Anforderung_Stufe3" ;
VAL_ 995 VS_VDKD_auf 0 "VDKD_nicht_vollst_auf" 1 "VDKD_vollstaendig_auf" ;
VAL_ 995 VS_FS_AutoHoch 0 "Keine_Verfahranforderung" 1 "Automatischer_Hochlauf" ;
VAL_ 995 VS_FS_AutoTief 0 "Keine_Verfahranforderung" 1 "Automatischer_Tieflauf" ;
VAL_ 995 VS_FS_ManHoch 0 "Keine_Verfahranforderung" 1 "Manueller_Hochlauf" ;
VAL_ 995 VS_FS_ManTief 0 "Keine_Verfahranforderung" 1 "Manueller_Tieflauf" ;
VAL_ 995 VS_BFS_AutoHoch 0 "Keine_Verfahranforderung" 1 "Automatischer_Hochlauf" ;
VAL_ 995 VS_BFS_AutoTief 0 "Keine_Verfahranforderung" 1 "Automatischer_Tieflauf" ;
VAL_ 995 VS_BFS_ManHoch 0 "Keine_Verfahranforderung" 1 "Manueller_Hochlauf" ;
VAL_ 995 VS_BFS_ManTief 0 "Keine_Verfahranforderung" 1 "Manueller_Tieflauf" ;
VAL_ 995 VS_HFS_AutoHoch 0 "Keine_Verfahranforderung" 1 "Automatischer_Hochlauf" ;
VAL_ 995 VS_HFS_AutoTief 0 "Keine_Verfahranforderung" 1 "Automatischer_Tieflauf" ;
VAL_ 995 VS_HFS_ManHoch 0 "Keine_Verfahranforderung" 1 "Manueller_Hochlauf" ;
VAL_ 995 VS_HFS_ManTief 0 "Keine_Verfahranforderung" 1 "Manueller_Tieflauf" ;
VAL_ 995 VS_HBFS_AutoHoch 0 "Keine_Verfahranforderung" 1 "Automatischer_Hochlauf" ;
VAL_ 995 VS_HBFS_AutoTief 0 "Keine_Verfahranforderung" 1 "Automatischer_Tieflauf" ;
VAL_ 995 VS_HBFS_ManHoch 0 "Keine_Verfahranforderung" 1 "Manueller_Hochlauf" ;
VAL_ 995 VS_HBFS_ManTief 0 "Keine_Verfahranforderung" 1 "Manueller_Tieflauf" ;
VAL_ 995 VS_FH_FT_Langhub 0 "Init" ;
VAL_ 995 VS_Windschott_nicht_abgelegt 0 "inaktiv" 1 "aktiv" ;
VAL_ 995 VS_FH_BT_Langhub 0 "Init" ;
VAL_ 995 VS_FH_HFS_Langhub 0 "Init" ;
VAL_ 995 VS_Heckschloss_auf 0 "kein_Oeffnen" 1 "Heckschloss_oeffnen" ;
VAL_ 995 VS_FH_HBFS_Langhub 0 "Init" ;
VAL_ 995 VSG_Meldungen 0 "keine_Meldung" ;
VAL_ 995 VS_StartStopp_Info 0 "Stoppfreigabe" 1 "Stoppverbot" 2 "Startanforderung" 3 "Fehler" ;
VAL_ 916 WBA_Fahrstufe_02 0 "Zwischenstellung_keine_Position" 1 "Position_P" 2 "Position_R" 3 "Position_N" 4 "Position_D" 5 "Position_S" 6 "Position_M_Tippfunktion" 7 "Kurzzeit_M" 8 "Position_E" 9 "Position_MS" 10 "Position_S_Plus" 11 "Position_MS_Plus" 12 "Position_Offroad" 13 "Position_B" 14 "Position_M_Plus" ;
VAL_ 916 WBA_ZielFahrstufe 0 "keine_Gangempfehlung_kein_Gang_eingelegt" 1 "Pfeil_nach_S" 2 "Pfeil_nach_D" 3 "Pfeil_nach_M" 4 "Pfeil_nach_E" ;
VAL_ 916 WBA_GE_Warnung_02 0 "keine_Anzeige" 1 "Fehlereskalationsstufe_I" 2 "Fehlereskalationsstufe_II" 3 "Weiterfahrt_nur_eingeschraenkt_moeglich__Kein_R_Gang" 4 "Getriebefehler_Weiterfahrt_nur_in_D_moeglich__P_bei_Motor_aus" 5 "Wegrollgefahr__P_nicht_moeglich" 6 "Paddlenotbetrieb_Schema+Warnung" 7 "Paddlenotbetrieb_Schema" 8 "Geschwindigkeitsbegrenzung_Notlauf" 9 "Fehlereskalationsst_o_Einschr" 10 "Fehlereskalationsstufe_v_Limit" 11 "Parksperre_Infostufe" 12 "Parksperre_Warnstufe_I" 13 "Parksperre_Warnstufe_II" ;
VAL_ 916 WBA_eing_Gang_02 0 "keine_Ganganzeige" 1 "Gang_1" 2 "Gang_2" 3 "Gang_3" 4 "Gang_4" 5 "Gang_5" 6 "Gang_6" 7 "Gang_7" 8 "Gang_8" 9 "Gang_9" 10 "Funktion_Ganganzeigeunterdrueckung" 11 "Gang_10" ;
VAL_ 916 WBA_GE_Texte 0 "keine_Anzeige" 1 "zum_Einlegen_einer_Fahrstufe_Fussbremse_betaetigen__ShiftLock_Information" 2 "zum_Einlegen_von_R_N_D_Fussbremse_betaetigen_und_Motor_starten" 3 "Wegrollgefahr_bitte_P_einlegen" 4 "Achtung_Zeitueberschreitung_P_wird_eingelegt" 5 "Wiederanmeldeprozedur_Bremse_betaetigen" 6 "P_nur_im_Stillstand_moeglich" 7 "Rennstart_aktiv" ;
VAL_ 916 WBA_Segeln_aktiv 0 "inaktiv" 1 "aktiv" ;
VAL_ 916 WBA_Schaltschema_02 0 "kein_Schaltschema" 1 "R_N_DS" 2 "R_N_ES" 3 "R_N_DB" 4 "R_N_D" 5 "R_N_SSplus" ;
VAL_ 916 WBA_Schaltschema_FS_inaktiv 0 "alle_Fahrstufen_aktiv" 1 "Fahrstufe_Rueckwaerts_inaktiv" 2 "nur_P_und_N_aktiv" 3 "alle_Fahrstufen_inaktiv" ;
VAL_ 916 WBA_GE_Zusatzwarnungen 0 "keine_Anzeige" 1 "Getriebeueberhitzung_Warnstufe_I" 2 "Getriebeueberhitzung_Warnstufe_II" 3 "Getriebefehler_Bitte_anhalten_und_P_einlegen" ;
VAL_ 916 GE_Sollgang 0 "keine_Empfehlung" 1 "Gang_1" 2 "Gang_2" 3 "Gang_3" 4 "Gang_4" 5 "Gang_5" 6 "Gang_6" 7 "Gang_7" 8 "Gang_8" 9 "Gang_9" 11 "Gang_10" ;
VAL_ 916 GE_Tipschaltempf_verfuegbar 0 "nicht_verfuegbar" 1 "verfuegbar" ;
VAL_ 916 WBA_GE_Texte_02 0 "Keine_Anzeige" 1 "Fahrtrichtungswechsel_nur_nach_Stillstandt" 2 "Ladestecker_gesteckt" 3 "zusaetzlicher_Service_erforderlich" 4 "eLaunch_Aktiv" 5 "eLaunch_nicht_moeglich" 6 "WH_S_nicht_moeglich_Offroad" 7 "WH_S_nicht_moeglich_RangeMode" ;
VAL_ 916 WBA_Schaltschema_Tippgasse 0 "keine_Tippgasse_vorhanden" 1 "Tippgasse_vorhanden" ;
VAL_ 916 WBA_Schaltschema_Fahreraktion 0 "keine_Fahreraktion" 1 "Fahreraktion" ;
VAL_ 916 WBA_Schaltschema_FS_vorwaerts 0 "FS1_aktiv__FS2_moeglich" 1 "FS2_aktiv__FS1_moeglich" 2 "FS1_aktiv__FS2_nicht_moeglich" 3 "FS2_aktiv__FS1_nicht_moeglich" ;
VAL_ 916 WBA_Shiftlock_Lampe 0 "Shiftlock_Lampe_AUS" 1 "Shiftlock_Lampe_EIN" ;
VAL_ 916 WBA_Anforderung_Akustik 0 "Akustik_aus" 1 "Akustik_ein" ;
VAL_ 916 WBA_Blinken 0 "kein_WBA_Blinken" 1 "WBA_Blinken" ;
VAL_ 916 GE_Wiederstart_Anz_Std 0 "keine_Anzeige" 1 "Standard_Wiederstartgrund" ;
VAL_ 916 GE_Stoppverbot_Anz_01 0 "keine_Anzeige" 1 "Temperaturbedingung" ;
VAL_ 916 GE_Stoppverbot_Anz_02 0 "keine_Anzeige" 1 "Drucksensorausfall" ;
VAL_ 916 GE_Stoppverbot_Anz_03 0 "keine_Anzeige" 1 "Grundeinstellung" ;
VAL_ 916 GE_Stoppverbot_Anz_04 0 "keine_Anzeige" 1 "Demontagestellung" ;
VAL_ 916 GE_Stoppverbot_Anz_05 0 "keine_Anzeige" 1 "Eingeschraenkte_Fahrfunktion_Notlauf_Liegenbleiber" ;
VAL_ 916 GE_Stoppverbot_Anz_06 0 "keine_Anzeige" 1 "Stoppverbot_ueber_Applikation" ;
VAL_ 916 GE_Stoppverbot_Anz_07 0 "keine_Anzeige" 1 "Schaltung_aktiv" ;
VAL_ 916 GE_Stoppverbot_Anz_Std 0 "keine_Anzeige" 1 "Standard_Stoppvetogrund" ;
VAL_ 1361 WFS_Schluessel_Fahrberecht 0 "kein authorisierter Schluessel erkannt" 1 "aktive_Funkschluessel_Nr_01" 2 "aktive_Funkschluessel_Nr_02" 3 "aktive_Funkschluessel_Nr_03" 4 "aktive_Funkschluessel_Nr_04" 5 "aktive_Funkschluessel_Nr_05" 6 "aktive_Funkschluessel_Nr_06" 7 "aktive_Funkschluessel_Nr_07" 8 "aktive_Funkschluessel_Nr_08" 9 "ungueltig_09" 10 "ungueltig_10" 11 "ungueltig_11" 12 "ungueltig_12" 13 "ungueltig_13" 14 "ungueltig_14" 15 "digitaler_Schluessel_aktiv" ;
VAL_ 1361 WFS_Verbauinfo_ELV 0 "ELV_nicht_verbaut" 1 "ELV_verbaut" ;
VAL_ 1361 WFS_ID_Geb_autorisiert 0 "Schluessel_nicht_authorisiert" 1 "Schluessel_authorisiert" ;
VAL_ 1361 WFS_ID_Geb_autorisiert_in_Kl15 0 "nicht_authorisiert_in_Kl15" 1 "authorisiert_in_Kl15" ;
VAL_ 1361 WFS_ID_Geb_steckt 0 "kein_Schluessel_im_Zuendschloss" 1 " Schluessel steckt im Zuendschloss" ;
VAL_ 1361 WFS_Safe 0 "Init" 1 "WFS nicht deaktiviert" ;
VAL_ 1361 WFS_LZ 0 "nicht def." 1 "LZ 1" 2 "LZ 2" 3 "LZ 3" ;
VAL_ 1361 WFS_ELV_authorisiert 0 "ELV_nicht_authorisiert" 1 "ELV_authorisiert" ;
VAL_ 1361 WFS_LF_Aktiv 0 "Funktempfang_nicht_aktiv" 1 "LF_Funkempfang_aktiv" ;
VAL_ 1361 WFS_Betrieb_Lesespule 0 "keine_Schluesselkomm_Lesespule" 1 "Schluesselkomm_Lesespule" ;
VAL_ 1361 WFS_Klemmenfreigabe 0 "keine_Freigabe" 1 "Freigabe" ;
VAL_ 1361 WFS_Fahrerhinweise 0 "Keine_Anzeigeanforderung" 1 "Schuessel_Auth_niO" 2 "Notlauf_aktiv" 3 "Schluessel_Kessy_nicht_gefunden" ;
VAL_ 1361 WFS_Parken_Status 0 "Limitierung_inaktiv" 1 "Limitierung_aktiv" 2 "Abbruch" ;
VAL_ 1702 Wischer_vorne_aktiv 0 "Init" 1 "Wischer_vorne_laeuft" ;
VAL_ 1702 Waschen_vorne_aktiv 0 "inaktiv" 1 "Waschen_aktiv" ;
VAL_ 1702 Wischer_vorne_Normal 1 "Wischer Front normal aktiv" ;
VAL_ 1702 Wischer_vorne_Schnell 1 "Wischer vorne schnell aktiv" ;
VAL_ 1702 Wischer_vorne_Parklage 0 "Wischer_Front_nicht_in_Parklage" 1 "Wischer_Front_in_Parklage__Initialzustand" ;
VAL_ 1702 WWSs_01_alt 0 "aktuell" 1 "veraltet" ;
VAL_ 1702 Wischer_vorne_defekt 0 "Init" 1 "Wischer vorne defekt" ;
VAL_ 1702 Wischer_vorne_blockiert 1 "Wischer vorne blockiert" ;
VAL_ 1702 Wischer1_Wischgeschwindigkeit 0 "0 U/min" 62 "Init" 63 "Fehler" ;
VAL_ 1702 BCM1_SRA_aktiv 0 "nicht aktiv" 1 "aktiv" ;
VAL_ 1702 Heckwischer_Anforderung 0 "Aus" 1 "Ein" ;
VAL_ 1702 Wischer_Anzeigetext 0 "keine_Anzeige" 1 "Hinweis_Service_Position" 2 "void" 3 "void" ;
VAL_ 1702 Wischer_WH_Typ 0 "Lenkstockschalter_0_Int_Stufen" 1 "Lenkstockschalter_2_Int_Stufen" 2 "Lenkstockschalter_4_Int_Stufen" ;
VAL_ 1702 Wischer_WH_PopUp_Anf 0 "keine_Anzeige" 1 "Intervallstufe_1_aktiv" 2 "Intervallstufe_2_aktiv" 3 "Intervallstufe_3_aktiv" 4 "Intervallstufe_4_aktiv" 5 "Regensensorstufe_1_aktiv" 6 "Regensensorstufe_2_aktiv" 7 "Regensensorstufe_3_aktiv" 8 "Regensensorstufe_4_aktiv" 9 "Wischerstufe_1_aktiv" 10 "Wischerstufe_2_aktiv" 11 "Tippwischen_aktiv" 12 "Heckwischen_aktiv" ;
VAL_ 2589283611 WLC1_Fehler 0 "kein_Fehler" 1 "WLC_Kompensor_Kurzschluss" 2 "WLC_Kompensor_Unterbrechung" 4 "WLC_Antenne_Kurzschluss" 8 "WLC_Antenne_Unterbrechung" 16 "Kompensor_keine_Versorgung" 32 "Kompensor_defekt" 64 "WLC_defekt" ;
VAL_ 2589283611 WLC1_Fremdobjekt_erkannt 0 "no_Foreign_object" 1 "Foreign_object_detected" ;
VAL_ 2589283611 WLC1_Objekt_erkannt 0 "no_Device_in_Tray" 1 "non_WLC_Device_in_Tray" ;
VAL_ 2589283611 WLC1_Receiver_erkannt 0 "no_Device_in_tray" 1 "WLC_Device_in_tray" ;
VAL_ 2589283611 WLC1_Receiver_voll_geladen 0 "WLC_not_fully_charged" 1 "WLC_Device_fully_charged" ;
VAL_ 2527679836 WLC1_ChargingStatus 0 "no_device_in_tray" 1 "no_wlc_device_in_tray" 2 "wlc_device_in_tray" 3 "wlc_charging_active" 4 "wlc_device_fully_charged" 5 "foreign_object_detected" 6 "nfc_card_and_wlc_device_detected" ;
VAL_ 2527679836 WLC1_UsedChargingStandard 0 "charging_not_active" 1 "qi" 2 "qi_fast_charge" 3 "samsung_fast_charge" 4 "apple_fast_charge" 5 "reduced_power_nfc_card_detected" ;
VAL_ 2527679837 WLC2_ChargingStatus 0 "no_device_in_tray" 1 "no_wlc_device_in_tray" 2 "wlc_device_in_tray" 3 "wlc_charging_active" 4 "wlc_device_fully_charged" 5 "foreign_object_detected" 6 "nfc_card_and_wlc_device_detected" ;
VAL_ 2527679837 WLC2_UsedChargingStandard 0 "charging_not_active" 1 "qi" 2 "qi_fast_charge" 3 "samsung_fast_charge" 4 "apple_fast_charge" 5 "reduced_power_nfc_card_detected" ;
VAL_ 1140 ZR_State_DU_1 0 "Disp_Off" 1 "Disp_On" 2 "LowPow" ;
VAL_ 1140 ZR_State_DU_2 0 "Disp_Off" 1 "Disp_On" 2 "LowPow" ;
VAL_ 1140 ZR_State_DU_3 0 "Disp_Off" 1 "Disp_On" 2 "LowPow" ;
VAL_ 1140 ZR_WecktGesp 0 "entsperrt" 1 "gesperrt" ;
VAL_ 1140 MMI_State 0 "MMI_OFF" 1 "MMI_IOC" 2 "MMI_STDBY" 3 "MMI_ON" 4 "MMI_STDBY_PWR_SAVE" 5 "MMI_STDBY_RESTR" 6 "MMI_ON_DIAG" 7 "MMI_ON_TEL" 8 "MMI_ON_SWDL" 9 "MMI_ON_CUST_SWDL" 10 "MMI_STDBY_PWR_SAVE_1" 11 "MMI_STDBY_PWR_SAVE_2" 12 "MMI_STANDBY_CUST_SWDL" 13 "MMI_ONLINE_IOC" 14 "MMI_ONLINE" 15 "MMI_PHONE_IOC" 16 "MMI_PHONE" 17 "MMI_RTC" 18 "MMI_DCI" ;
VAL_ 1140 ZR_DimOffs_DU_1 14 "Init" ;
VAL_ 1140 ZR_DimOffs_DU_2 14 "Init" ;
VAL_ 1140 ZR_DimOffs_DU_3 14 "Init" ;
VAL_ 1140 SI_ICAN 0 "keine_Busruhe" 1 "Busruhe" ;
VAL_ 1140 ZR_Lenkerposition 0 "links" 1 "rechts" ;
VAL_ 1140 WLC1_Systemzustand 0 "Wireless_Charger_off" 1 "InitWert_Wireless_Charger_on" ;
VAL_ 1140 WLC2_Systemzustand 0 "Wireless_Charger_off" 1 "InitWert_Wireless_Charger_on" ;
VAL_ 1140 DI_Screendesign 0 "Automatisch" 1 "Tag" 2 "Nacht" 6 "Init" 7 "Fehler" ;
VAL_ 1140 ZR_State_DU_4 0 "Disp_Off" 1 "Disp_On" 2 "LowPow" ;
VAL_ 1140 ZR_DimOffs_DU_4 14 "Init" ;
VAL_ 2589283965 ZR_Plattform 0 "Init" 1 "MQB" 2 "MQB2020_MQB_W" 3 "MQBw_Baseline" 4 "Reserviert" 5 "Reserviert" 6 "MLBevo_Gen2" 7 "Reserviert" 8 "Reserviert" 9 "E3_1_1_MEB" 10 "E3_1_1_UNECE" 11 "E3_1_2_Premium" 12 "Reserviert" ;
VAL_ 2589283965 DFB_CILState_ADA 0 "idle" 1 "onZero" 2 "onUnblock" 3 "onWarn" 4 "onBlock" 5 "unblockPassenger" 6 "error" 7 "reserved" ;
VAL_ 2589283965 DFB_InteractionStatus_ADA 0 "idle" 1 "no_interaction" 2 "interaction" 3 "error" ;
VAL_ 2589283965 SpeechAssistant_State 0 "init" 1 "nicht_aktiv" 2 "aktiv" 3 "nicht_verbaut" ;
VAL_ 2589283965 Info_El_Lade_Fehler 0 "Init" 1 "Fehler" ;
VAL_ 2589283965 FaceRec2_Control_Challenge_Req 0 "SEND_NOTHING" 1 "SEND_CHALLENGE" ;
VAL_ 2463978864 ZR_BedienDisp_X_control_surround 125 "Surround_off" 126 "Init" 127 "Fehler" ;
VAL_ 2463978864 ZR_BedienDisp_X_fokus_zone 0 "Init" 1 "All" 2 "Front_left" 3 "Front_right" 4 "Front" 5 "Rear_left" 6 "Rear_right" 7 "Rear" 13 "Individual" 14 "Surround" 15 "Fehler" ;
VAL_ 2463978864 ZR_BedienDisp_X_contr_iClima_av 0 "Init" 1 "No_function_availible" 2 "Function_availible" 3 "Fehler" ;
VAL_ 2463978864 ZR_BedienDisp_X_control_fct 0 "Init" 1 "No_function_availible" 2 "Air_Volume" 3 "Air_Distribution" 4 "iClimate" 5 "Volume" 6 "Driving_modes" 7 "MapZoom" 14 "Configuration" 15 "Fehler" ;
VAL_ 2463978864 ZR_BedienDisp_X_control_iClima 0 "Init" 1 "No_function_availible" 2 "Defog_certain_window" 3 "fast_cooling" 4 "fast_heating" 5 "feet_cooling" 6 "feet_heating" 7 "air_refreshing" 8 "hand_heating" 9 "Pollution_protection" 15 "Fehler" ;
VAL_ 2463978864 ZR_BedienDisp_X_control_MapMode 0 "Init" 1 "No_function_availible" 2 "Manual" 3 "Automatic" 7 "Fehler" ;
VAL_ 2463978864 ZR_BedienDisp_X_control_MapZoom 0 "Init" 1 "scale_1" 2 "scale_2" 3 "scale_3" 4 "scale_4" 5 "scale_5" 6 "scale_6" 7 "scale_7" 8 "scale_8" 9 "scale_9" 10 "scale_10" 11 "scale_11" 12 "scale_12" 13 "scale_13" 14 "scale_14" 15 "scale_15" 16 "scale_16" 17 "scale_17" ;
VAL_ 2463978864 ZR_BedienDisp_X_control_sound 0 "Init" 1 "No_function_availible" 2 "NaVi" 3 "SDS" 4 "Audio" 5 "TA" 6 "Phone" 7 "Phone_ringing" 8 "Digital_voice_assistant" ;
VAL_ 2463978864 ZR_BedienDisp_X_control_vol 61 "mute" 62 "No_function_availible" 126 "Init" 127 "Fehler" ;
VAL_ 2463978864 ZR_BedienDisp_X_control_vol_max 61 "No_function_availible" 62 "Init" 63 "Fehler" ;
VAL_ 2463978864 ZR_BedienDisp_X_control_vol_min 61 "No_function_availible" 62 "Init" 63 "Fehler" ;
VAL_ 2463978864 ZR_BedienDisp_X_control_Point 0 "Init" 1 "nmr_profiles_1" 2 "nmr_profiles_2" 3 "nmr_profiles_3" 4 "nmr_profiles_4" 5 "nmr_profiles_5" 6 "nmr_profiles_6" 7 "Fehler" ;
VAL_ 2463978864 ZR_BedienDisp_X_navidot_position 0 "init" 1 "A" 2 "B" 3 "C" 4 "D" 5 "E_NA_" 6 "F_NA_" 7 "Fehler" ;
VAL_ 388 ZV_FT_verriegeln 0 "FT_nicht_verriegeln" 1 "FT_verriegeln" ;
VAL_ 388 ZV_FT_entriegeln 0 "FT_nicht_entriegeln" 1 "FT_entriegeln" ;
VAL_ 388 ZV_BT_verriegeln 0 "BT_nicht_verriegeln" 1 "BT_verriegeln" ;
VAL_ 388 ZV_BT_entriegeln 0 "BT_nicht_entriegeln" 1 "BT_ist_zu_entriegeln" ;
VAL_ 388 ZV_HFS_verriegeln 0 "inaktiv" 1 "aktiv" ;
VAL_ 388 ZV_HFS_entriegeln 0 "inaktiv" 1 "aktiv" ;
VAL_ 388 ZV_HBFS_verriegeln 0 "inaktiv" 1 "aktiv" ;
VAL_ 388 ZV_HBFS_entriegeln 0 "inaktiv" 1 "aktiv" ;
VAL_ 388 ZV_zentral_safen 0 "nicht_safen" 1 "Befehl_zentral_safen" ;
VAL_ 388 ZV_zentral_entsafen 0 "Init" 1 "Befehl_zentral_entsafen" ;
VAL_ 388 ZV_Spg_Anklappen 0 "inaktiv" 1 "aktiv" ;
VAL_ 388 ZV_Softtouch_betaetigt 0 "Softtouch_nicht_betaetigt" 1 "Softtouch_betaetigt" ;
VAL_ 388 ZV_LED_Steuerung 0 "LED_aus" 1 "LED_ein" ;
VAL_ 388 ZV_LED_Uebernahme 0 "Init" 1 "TSG_uebernimmt_LED_Steuerung" ;
VAL_ 388 ZV_auf_FT 0 "nicht_betaetigt" 1 "betaetigt" ;
VAL_ 388 ZV_zu_FT 0 "nicht_betaetigt" 1 "betaetigt" ;
VAL_ 388 ZV_auf_BT 0 "nicht_betaetigt" 1 "betaetigt" ;
VAL_ 388 ZV_zu_BT 0 "nicht_betaetigt" 1 "betaetigt" ;
VAL_ 388 ZV_auf_Funk 0 "nicht_betaetigt" 1 "betaetigt" ;
VAL_ 388 ZV_zu_Funk 0 "nicht_betaetigt" 1 "betaetigt" ;
VAL_ 388 VIP_Sensor_betaetigt 0 "Heckentr_VIP_nicht_angefordert" 1 "Heckentr_VIP_angefordert" ;
VAL_ 388 VIP_Freigabe 0 "keine_Freigabe" 1 "Freigabe" ;
VAL_ 388 ZV_zu_Zeitl_Nachverr 0 "Init" 1 "Nachverriegeln" ;
VAL_ 388 ZV_HSK_entriegeln 0 "Handschuhkasten nicht entriegeln" 1 "Handschuhkasten entriegeln" ;
VAL_ 388 ZV_HSK_verriegeln 0 "Handschuhkasten nicht verriegeln" 1 "Handschuhkasten_verriegelt" ;
VAL_ 388 ZV_Verdeck_zu 0 "inaktiv" 1 "aktiv" ;
VAL_ 388 ZV_Verdeck_auf 0 "inaktiv" 1 "aktiv" ;
VAL_ 388 FH_FT_hoch 0 "keine_Anforderung" 1 "FT_hoch" ;
VAL_ 388 FH_FT_tief 0 "keine_Anforderung" 1 "FT_tief" ;
VAL_ 388 FH_BT_hoch 0 "keine_Anforderung" 1 "BT_hoch" ;
VAL_ 388 FH_BT_tief 0 "keine_Anforderung" 1 "BT_tief" ;
VAL_ 388 FH_HFS_hoch 0 "inaktiv" 1 "aktiv" ;
VAL_ 388 FH_HFS_tief 0 "inaktiv" 1 "aktiv" ;
VAL_ 388 FH_HBFS_hoch 0 "inaktiv" 1 "aktiv" ;
VAL_ 388 FH_HBFS_tief 0 "inaktiv" 1 "aktiv" ;
VAL_ 388 BCM_Spg_Synchron 0 "inaktiv" 1 "aktiv" ;
VAL_ 388 BCM_BF_Spg_Absenkung 0 "inaktiv" 1 "aktiv" ;
VAL_ 388 ZV_entriegeln_Anf 0 "nicht_betaetigt" 1 "betaetigt" ;
VAL_ 388 ZV_auto_Ansteuerung 0 "Kein_Autolock_Unlock" 1 "Autolock_Unlock" ;
VAL_ 1411 ZV_verriegeln_Anf 0 "nicht_betaetigt" 1 "betaetigt" ;
VAL_ 1411 ZV_STSG_HFS_Anf 0 "keine_Anforderung" 1 "Anforderung" ;
VAL_ 1411 ZV_STSG_HBFS_Anf 0 "keine_Anforderung" 1 "Anforderung" ;
VAL_ 1411 ZV_Anf_Challenge_Auth 0 "nicht_aktiv" 1 "aktiv" ;
VAL_ 1411 ZV_STSG_Crashzustand 0 "inaktiv" 1 "aktiv" ;
VAL_ 1411 ZV_STSG_eKiSi_defekt 0 "inaktiv" 1 "aktiv" ;
VAL_ 1411 ZV_eRWK_Umfeld_Pruefung 0 "nicht_aktiv" 1 "aktiv" ;
VAL_ 1411 VIP_Sensor_STSG_HFS_betaetigt 0 "keine_VIP_Anforderung_STSG_HFS" 1 "VIP_Anforderung_STSG_HFS" ;
VAL_ 1411 VIP_Sensor_STSG_HBFS_betaetigt 0 "keine_VIP_Anforderung_STSG_HBFS" 1 "VIP_Anforderung_STSG_HBFS" ;
VAL_ 1411 BCM_FH_Freigabe 1 "Funktionsfreigabe Fensterheber" ;
VAL_ 1411 BCM_Komfortfkt_Freigabe 0 "Komfortfunktion gesperrt" 1 "globale Freigabe der Komfortfunktion erteilt" ;
VAL_ 1411 BCM_HSK_Freigabe 0 "erlauben" 1 "sperren" ;
VAL_ 1411 BCM_Verdeck_Freigabe 0 "Verdeckbetrieb nicht erlaubt" 1 "Verdeckbetrieb erlaubt" ;
VAL_ 1411 ZV_verriegelt_intern_ist 1 "Fahrzeug innen verriegelt; Istzustand" ;
VAL_ 1411 ZV_verriegelt_extern_ist 1 "Fahrzeug_aussen_verriegelt_Istzustand" ;
VAL_ 1411 ZV_verriegelt_intern_soll 1 "Fahrzeug verriegelt intern; Sollzusstand" ;
VAL_ 1411 ZV_verriegelt_extern_soll 1 "Fahrzeug verriegelt extern; Sollzusstand" ;
VAL_ 1411 ZV_gesafet_extern_ist 1 "Fahrzeug aussen gesafet; Istzustand" ;
VAL_ 1411 ZV_gesafet_extern_soll 1 "Fahrzeug_aussen_gesafet_Sollzustand" ;
VAL_ 1411 ZV_Einzeltuerentriegelung 1 "Fahrzeug an Einzeltuer entriegelt" ;
VAL_ 1411 ZV_Heckeinzelentriegelung 1 "Heckdeckeleinzelentriegelung" ;
VAL_ 1411 ZV_FT_offen 0 "FT_geschlossen" 1 "FT_geoeffnet" ;
VAL_ 1411 ZV_BT_offen 0 "BT_geschlossen" 1 "BT_geoeffnet" ;
VAL_ 1411 ZV_HFS_offen 0 "geschlossen" 1 "offen" ;
VAL_ 1411 ZV_HBFS_offen 0 "geschlossen" 1 "offen" ;
VAL_ 1411 ZV_HD_offen 1 "Heckdeckel_auf" ;
VAL_ 1411 ZV_HS_offen 0 "Heckscheibe_geschlossen" 1 "Heckscheibe auf" ;
VAL_ 1411 IRUE_aktiv 0 "unscharf" 1 "scharf" ;
VAL_ 1411 DWA_aktiv 0 "unscharf" 1 "scharf" ;
VAL_ 1411 HD_Hauptraste 0 "geschlossen" 1 "offen" ;
VAL_ 1411 HD_Vorraste 0 "geschlossen" 1 "offen" ;
VAL_ 1411 FFB_HDF_Taste 0 "Taste_nicht_betaetigt" 1 "HDF_Taste_am_Funkschluessel_betaetigt" ;
VAL_ 1411 FFB_Panik_Taste 0 "Taste_nicht_betaetigt" 1 "Panik_Taste_am_Funkschluessel_betaetigt" ;
VAL_ 1411 FFB_Auf_Taste 0 "Taste_nicht_betaetigt" 1 "Oeffnentaste_betaetigt" ;
VAL_ 1411 FFB_Zu_Taste 0 "Taste_nicht_betaetigt" 1 "Zu_Taste_am_Funkschluessel_betaetigt" ;
VAL_ 1411 FFB_CarFinder 0 "nicht aktiv" 1 "aktiv" ;
VAL_ 1411 FFB_Komfortoeffnen 0 "kein_Komfortoeffnen_empfangen" 1 "Komfortoeffnen ueber Funk empfangen" ;
VAL_ 1411 FFB_Komfortschliessen 0 "kein_Komfortschliessen_empfangen" 1 "Komfortschliessen ueber Funk empfangen" ;
VAL_ 1411 FBS_IDG_in_Reichweite 0 "ausser_Reichweite_bzw_nicht_ermittelbar" 1 "innerhalb_Reichweite" ;
VAL_ 1411 ZV_Schluessel_Zugang 0 "kein_auth_Schluessel_erkannt" 1 "aktive_Funkschluessel_Nr_01" 2 "aktive_Funkschluessel_Nr_02" 3 "aktive_Funkschluessel_Nr_03" 4 "aktive_Funkschluessel_Nr_04" 5 "aktive_Funkschluessel_Nr_05" 6 "aktive_Funkschluessel_Nr_06" 7 "aktive_Funkschluessel_Nr_07" 8 "aktive_Funkschluessel_Nr_08" 9 "aktive_SmartDevice_Nr_09" 10 "ungueltig_10" 11 "ungueltig_11" 12 "ungueltig_12" 13 "ungueltig_13" 14 "ungueltig_14" 15 "ungueltig_15" ;
VAL_ 1411 ZV_SafeFunktion_aktiv 0 "inaktiv" 1 "aktiv" ;
VAL_ 1411 FBS_Warn_Schluessel_Batt 0 "i.O." 1 "defekt" ;
VAL_ 1411 ZV_Oeffnungsmodus 0 "globale_Oeffnung" 1 "ZV_mit_Einzeltuerentr" 2 "ZV_individuell_selektiv" 3 "ZV_seitenselektiv" ;
VAL_ 1411 HFS_verriegelt 0 "nicht_verriegelt" 1 "verriegelt" ;
VAL_ 1411 HFS_gesafet 0 "nicht_gesafet" 1 "gesafet" ;
VAL_ 1411 HBFS_verriegelt 0 "nicht_verriegelt" 1 "verriegelt" ;
VAL_ 1411 HBFS_gesafet 0 "nicht_gesafet" 1 "gesafet" ;
VAL_ 1411 ZV_ist_Zustand_verfuegbar 0 "nicht_verfuegbar" 1 "verfuegbar_alle_TSGs_am_Bus" ;
VAL_ 1411 IRUE_Taster_Fkts_LED 0 "LED_aus" 1 "LED_ein" ;
VAL_ 1411 ZV_Tankklappe_offen 0 "Tankklappe_geschlossen" 1 "Tankklappe_offen" ;
VAL_ 1411 ZV_Rollo_auf 0 "inaktiv" 1 "aktiv" ;
VAL_ 1411 ZV_Rollo_zu 0 "inaktiv" 1 "aktiv" ;
VAL_ 1411 ZV_SAD_auf 0 "inaktiv" 1 "aktiv" ;
VAL_ 1411 ZV_SAD_zu 0 "inaktiv" 1 "aktiv" ;
VAL_ 1411 BCM_Tankklappensteller_Fehler 0 "kein_Fehler" 1 "Fehler" ;
VAL_ 1411 ZV_verriegelt_soll 0 "Init" 1 "nicht_verriegelt" 2 "verriegelt" ;
